VERSION "HNNBNNNYNNNNNNNNNNNNNNNNNNNNNNNNNNNNNNNNNN/4/%%%/4/'%**4NNN///"

NS_ :

BS_:

BU_: BAP_Tester BCM1 Gateway Gateway_PAG Klima_MSB Lift_VA VAS_L VAS_R

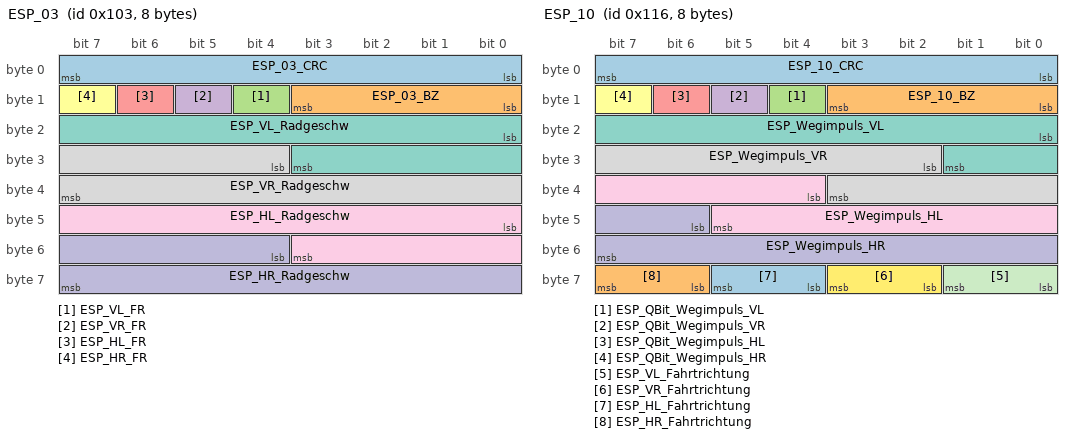
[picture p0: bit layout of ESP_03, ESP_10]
BO_ 259 ESP_03: 8 Gateway
 SG_ ESP_03_CRC : 0|8@1+ (1,0) [0|255] ""  Vector__XXX
 SG_ ESP_03_BZ : 8|4@1+ (1,0) [0|15] ""  Vector__XXX
 SG_ ESP_VL_FR : 12|1@1+ (1.0,0.0) [0.0|1] ""  BCM1
 SG_ ESP_VR_FR : 13|1@1+ (1.0,0.0) [0.0|1] ""  BCM1
 SG_ ESP_HL_FR : 14|1@1+ (1.0,0.0) [0.0|1] ""  BCM1
 SG_ ESP_HR_FR : 15|1@1+ (1.0,0.0) [0.0|1] ""  BCM1
 SG_ ESP_VL_Radgeschw : 16|12@1+ (0.1,0) [0.0|409.2] "Unit_KiloMeterPerHour"  BCM1
 SG_ ESP_VR_Radgeschw : 28|12@1+ (0.1,0) [0.0|409.2] "Unit_KiloMeterPerHour"  BCM1
 SG_ ESP_HL_Radgeschw : 40|12@1+ (0.1,0) [0.0|409.2] "Unit_KiloMeterPerHour"  BCM1
 SG_ ESP_HR_Radgeschw : 52|12@1+ (0.1,0) [0.0|409.2] "Unit_KiloMeterPerHour"  BCM1

BO_ 914 ESP_07: 8 Gateway
 SG_ ESP_07_CRC : 0|8@1+ (1,0) [0|255] ""  Vector__XXX
 SG_ ESP_07_BZ : 8|4@1+ (1,0) [0|15] ""  Vector__XXX
 SG_ ESP_Allrad_Antrieb : 13|1@1+ (1.0,0.0) [0.0|1] ""  Vector__XXX
 SG_ ESP_Codierung_ADS : 14|2@1+ (1.0,0.0) [0.0|3] ""  BCM1
 SG_ ESP_RTA_HL : 16|8@1+ (0.048828125,-6.20117) [-6.201170000|6.152345625] "Unit_PerCent"  Vector__XXX
 SG_ ESP_RTA_HR : 24|8@1+ (0.048828125,-6.20117) [-6.201170000|6.152345625] "Unit_PerCent"  Vector__XXX
 SG_ ESP_RTA_VR : 32|8@1+ (0.048828125,-6.20117) [-6.201170000|6.152345625] "Unit_PerCent"  Vector__XXX
 SG_ OBD_Fehler_Radsensor_HL : 40|4@1+ (1.0,0.0) [0.0|15] ""  Vector__XXX
 SG_ OBD_Fehler_Radsensor_HR : 44|4@1+ (1.0,0.0) [0.0|15] ""  Vector__XXX
 SG_ OBD_Fehler_Radsensor_VL : 48|4@1+ (1.0,0.0) [0.0|15] ""  Vector__XXX
 SG_ OBD_Fehler_Radsensor_VR : 52|4@1+ (1.0,0.0) [0.0|15] ""  Vector__XXX
 SG_ ESP_Qualifizierung_Antriebsart : 56|1@1+ (1.0,0.0) [0.0|1] ""  Vector__XXX
 SG_ ESP_Offroad_Modus : 57|1@1+ (1.0,0.0) [0.0|1] ""  Vector__XXX
 SG_ ESP_MKB_ausloesbar : 58|1@1+ (1.0,0.0) [0.0|1] ""  Vector__XXX
 SG_ ESP_Stat_FallBack_eBKV : 59|1@1+ (1.0,0.0) [0.0|1] ""  Vector__XXX
 SG_ ESC_cAQP_Trigger : 60|1@1+ (1.0,0.0) [0.0|1] ""  Vector__XXX
 SG_ ESP_OBD_Status : 61|1@1+ (1.0,0.0) [0.0|1] ""  Vector__XXX
 SG_ ESP_Rollenmodus_Deaktivieren : 62|1@1+ (1.0,0.0) [0.0|1] ""  BCM1,Klima_MSB
 SG_ ESP_nachtr_Stopp_Anf : 63|1@1+ (1.0,0.0) [0.0|1] ""  Vector__XXX

BO_ 278 ESP_10: 8 Gateway
 SG_ ESP_10_CRC : 0|8@1+ (1,0) [0|255] ""  BCM1
 SG_ ESP_10_BZ : 8|4@1+ (1,0) [0|15] ""  BCM1
 SG_ ESP_QBit_Wegimpuls_VL : 12|1@1+ (1.0,0.0) [0.0|1] ""  BCM1
 SG_ ESP_QBit_Wegimpuls_VR : 13|1@1+ (1.0,0.0) [0.0|1] ""  BCM1
 SG_ ESP_QBit_Wegimpuls_HL : 14|1@1+ (1.0,0.0) [0.0|1] ""  BCM1
 SG_ ESP_QBit_Wegimpuls_HR : 15|1@1+ (1.0,0.0) [0.0|1] ""  BCM1
 SG_ ESP_Wegimpuls_VL : 16|10@1+ (1,0) [0|1000] ""  BCM1
 SG_ ESP_Wegimpuls_VR : 26|10@1+ (1,0) [0|1000] ""  BCM1
 SG_ ESP_Wegimpuls_HL : 36|10@1+ (1,0) [0|1000] ""  BCM1
 SG_ ESP_Wegimpuls_HR : 46|10@1+ (1,0) [0|1000] ""  BCM1
 SG_ ESP_VL_Fahrtrichtung : 56|2@1+ (1.0,0.0) [0.0|3] ""  BCM1
 SG_ ESP_VR_Fahrtrichtung : 58|2@1+ (1.0,0.0) [0.0|3] ""  BCM1
 SG_ ESP_HL_Fahrtrichtung : 60|2@1+ (1.0,0.0) [0.0|3] ""  BCM1
 SG_ ESP_HR_Fahrtrichtung : 62|2@1+ (1.0,0.0) [0.0|3] ""  BCM1

BO_ 418 ESP_15: 8 Gateway
 SG_ ESP_15_CRC : 0|8@1+ (1,0) [0|255] ""  Vector__XXX
 SG_ ESP_15_BZ : 8|4@1+ (1,0) [0|15] ""  Vector__XXX
 SG_ HMS_P_beibehalten_GE : 12|2@1+ (1.0,0.0) [0.0|3] ""  Vector__XXX
 SG_ HMS_Konsistenz_GE : 14|1@1+ (1.0,0.0) [0.0|1] ""  Vector__XXX
 SG_ HMS_Konsistenz_IPA : 15|1@1+ (1.0,0.0) [0.0|1] ""  BCM1
 SG_ HMS_Konsistenz_STA : 18|1@1+ (1.0,0.0) [0.0|1] ""  Vector__XXX
 SG_ HMS_Konsistenz_MO : 19|1@1+ (1.0,0.0) [0.0|1] ""  Vector__XXX
 SG_ HMS_halten_nicht_verfuegbar : 20|1@1+ (1.0,0.0) [0.0|1] ""  Vector__XXX
 SG_ NL_PRIM_STP_01_Status : 21|3@1+ (1.0,0.0) [0.0|7] ""  Vector__XXX
 SG_ VMM_Warnblinken : 24|1@1+ (1.0,0.0) [0.0|1] ""  Vector__XXX
 SG_ VZM_Status : 26|3@1+ (1.0,0.0) [0.0|7] ""  BCM1
 SG_ HMS_Notstopp_Status : 29|3@1+ (1.0,0.0) [0.0|7] ""  Vector__XXX
 SG_ HMS_parken_nicht_verfuegbar : 32|1@1+ (1.0,0.0) [0.0|1] ""  Vector__XXX
 SG_ HMS_Anforderung_GE : 33|3@1+ (1.0,0.0) [0.0|7] ""  Vector__XXX
 SG_ HMS_Systemstatus : 36|4@1+ (1.0,0.0) [0.0|15] ""  BCM1
 SG_ HMS_Stillstand : 40|3@1+ (1.0,0.0) [0.0|7] ""  BCM1
 SG_ HMS_aktives_System : 43|5@1+ (1.0,0.0) [0.0|31] ""  BCM1
 SG_ HMS_Konsistenz_HVLM : 48|1@1+ (1.0,0.0) [0.0|1] ""  Vector__XXX
 SG_ HMS_Konsistenz_ACC : 49|1@1+ (1.0,0.0) [0.0|1] ""  Vector__XXX
 SG_ HMS_Fehlerstatus : 50|3@1+ (1.0,0.0) [0.0|7] ""  BCM1
 SG_ ESP_Index_Haltemoment : 53|1@1+ (1.0,0.0) [0.0|1] ""  Vector__XXX
 SG_ ESP_Haltemoment : 54|10@1+ (10,0) [0|10210] "Unit_NewtoMeter"  Vector__XXX

BO_ 253 ESP_21: 8 Gateway
 SG_ ESP_21_CRC : 0|8@1+ (1,0) [0|255] ""  BCM1
 SG_ ESP_21_BZ : 8|4@1+ (1,0) [0|15] ""  BCM1
 SG_ BR_Eingriffsmoment : 12|10@1+ (1,-509) [-509|509] ""  BCM1
 SG_ MSR_verfuegbar : 22|1@1+ (1.0,0.0) [0.0|1] ""  Vector__XXX
 SG_ ESP_Diagnose : 23|1@1+ (1.0,0.0) [0.0|1] ""  BCM1
 SG_ ESC_v_Signal_Qualifier_High_Low : 24|3@1+ (1.0,0.0) [0.0|7] ""  BCM1
 SG_ ESP_Vorsteuerung : 28|1@1+ (1.0,0.0) [0.0|1] ""  BCM1
 SG_ OBD_Schlechtweg : 30|1@1+ (1.0,0.0) [0.0|1] ""  BCM1
 SG_ OBD_QBit_Schlechtweg : 31|1@1+ (1.0,0.0) [0.0|1] ""  BCM1
 SG_ ESP_v_Signal : 32|16@1+ (0.01,0) [0.00|655.32] "Unit_KiloMeterPerHour"  BCM1,Klima_MSB,Lift_VA,VAS_L,VAS_R
 SG_ ASR_Tastung_passiv : 48|1@1+ (1.0,0.0) [0.0|1] ""  BCM1
 SG_ ESP_Tastung_passiv : 49|1@1+ (1.0,0.0) [0.0|1] ""  BCM1
 SG_ ESP_Systemstatus : 50|1@1+ (1.0,0.0) [0.0|1] ""  BCM1
 SG_ ASR_Schalteingriff : 51|2@1+ (1.0,0.0) [0.0|3] ""  BCM1
 SG_ ESP_QBit_v_Signal : 55|1@1+ (1.0,0.0) [0.0|1] ""  BCM1,Klima_MSB,VAS_L,VAS_R
 SG_ ABS_Bremsung : 56|1@1+ (1.0,0.0) [0.0|1] ""  BCM1
 SG_ ASR_Anf : 57|1@1+ (1.0,0.0) [0.0|1] ""  BCM1
 SG_ MSR_Anf : 58|1@1+ (1.0,0.0) [0.0|1] ""  BCM1
 SG_ EBV_Eingriff : 59|1@1+ (1.0,0.0) [0.0|1] ""  BCM1
 SG_ EDS_Eingriff : 60|1@1+ (1.0,0.0) [0.0|1] ""  BCM1
 SG_ ESP_Eingriff : 61|1@1+ (1.0,0.0) [0.0|1] ""  BCM1
 SG_ ESP_ASP : 62|1@1+ (1.0,0.0) [0.0|1] ""  BCM1
 SG_ ESC_Neutralschaltung : 63|1@1+ (1.0,0.0) [0.0|1] ""  Vector__XXX

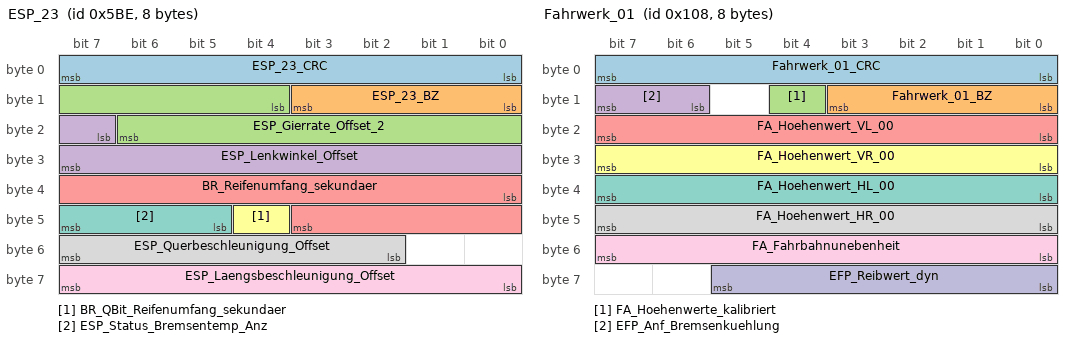
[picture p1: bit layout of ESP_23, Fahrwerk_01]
BO_ 1470 ESP_23: 8 Gateway
 SG_ ESP_23_CRC : 0|8@1+ (1,0) [0|255] ""  Vector__XXX
 SG_ ESP_23_BZ : 8|4@1+ (1,0) [0|15] ""  Vector__XXX
 SG_ ESP_Gierrate_Offset_2 : 12|11@1+ (0.01,-10.23) [-10.23|10.22] "Unit_DegreOfArcPerSecon"  VAS_L,VAS_R
 SG_ ESP_Lenkwinkel_Offset : 23|9@1+ (0.1,-25.5) [-25.5|25.4] "Unit_DegreOfArc"  Vector__XXX
 SG_ BR_Reifenumfang_sekundaer : 32|12@1+ (1,0) [0|4095] "Unit_MilliMeter"  Vector__XXX
 SG_ BR_QBit_Reifenumfang_sekundaer : 44|1@1+ (1.0,0.0) [0.0|1] ""  Vector__XXX
 SG_ ESP_Status_Bremsentemp_Anz : 45|3@1+ (1.0,0.0) [0.0|7] ""  Vector__XXX
 SG_ ESP_Querbeschleunigung_Offset : 50|6@1+ (0.01,-0.3) [-0.30|0.31] "Unit_ForceOfGravi"  Vector__XXX
 SG_ ESP_Laengsbeschleunigung_Offset : 56|8@1+ (0.03125,-3.9375) [-3.93750|3.93750] "Unit_MeterPerSeconSquar"  Vector__XXX

BO_ 508 ESP_32: 8 Gateway
 SG_ ESP_32_CRC : 0|8@1+ (1,0) [0|255] ""  Vector__XXX
 SG_ ESP_32_BZ : 8|4@1+ (1,0) [0|15] ""  Vector__XXX
 SG_ ESP_Status_Bremsentemp_02 : 12|2@1+ (1.0,0.0) [0.0|3] ""  Vector__XXX
 SG_ ESP_Aggregataktivitaet : 14|1@1+ (1.0,0.0) [0.0|1] ""  Vector__XXX
 SG_ ESP_Stillstandsflag : 15|1@1+ (1.0,0.0) [0.0|1] ""  BCM1
 SG_ ESC_MBK_Meldungen : 16|2@1+ (1.0,0.0) [0.0|3] ""  Vector__XXX
 SG_ ESP_EDS_Anzeige : 32|3@1+ (1.0,0.0) [0.0|7] ""  Vector__XXX
 SG_ RLE_Anzeigen : 35|3@1+ (1.0,0.0) [0.0|7] ""  Vector__XXX
 SG_ ESP_Wiederstart_Anz_Std : 38|1@1+ (1.0,0.0) [0.0|1] ""  Vector__XXX
 SG_ ESC_Anforderung_Airbrake : 39|1@1+ (1.0,0.0) [0.0|1] ""  Vector__XXX
 SG_ ESC_FBA_Meldungen : 40|2@1+ (1.0,0.0) [0.0|3] ""  Vector__XXX
 SG_ ESP_Rollover_Status_dyn : 42|2@1+ (1.0,0.0) [0.0|3] ""  Vector__XXX
 SG_ ESP_Rollover_Status_stat : 44|2@1+ (1.0,0.0) [0.0|3] ""  Vector__XXX
 SG_ ESP_AVH_LED : 46|3@1+ (1.0,0.0) [0.0|7] ""  BCM1
 SG_ ESP_HDC_LED : 49|3@1+ (1.0,0.0) [0.0|7] ""  BCM1
 SG_ ESP_Off_LED : 52|3@1+ (1.0,0.0) [0.0|7] ""  BCM1
 SG_ ESP_Notbremsanzeige : 55|1@1+ (1.0,0.0) [0.0|1] ""  Vector__XXX
 SG_ ESC_Motorstartverzoegerung : 56|1@1+ (1.0,0.0) [0.0|1] ""  Vector__XXX
 SG_ ESP_Offroad_Lampe : 57|1@1+ (1.0,0.0) [0.0|1] ""  Vector__XXX
 SG_ ESP_HDC_Textanzeigen : 58|5@1+ (1.0,0.0) [0.0|31] ""  Vector__XXX
 SG_ ESP_HOLD_verf : 63|1@1+ (1.0,0.0) [0.0|1] ""  Vector__XXX

BO_ 427 ESP_33: 8 Gateway
 SG_ ESP_33_CRC : 0|8@1+ (1,0) [0|255] ""  Vector__XXX
 SG_ ESP_33_BZ : 8|4@1+ (1,0) [0|15] ""  Vector__XXX
 SG_ ESC_AHW_aktiv : 12|3@1+ (1.0,0.0) [0.0|7] ""  BCM1
 SG_ ESC_AHW_nicht_verfuegbar : 15|1@1+ (1.0,0.0) [0.0|1] ""  BCM1
 SG_ ESC_ANB_CM_aktiv : 16|2@1+ (1.0,0.0) [0.0|3] ""  Vector__XXX
 SG_ ESC_ANB_CM_nicht_verfuegbar : 18|1@1+ (1.0,0.0) [0.0|1] ""  Vector__XXX
 SG_ ESC_Warnruck_aktiv : 19|4@1+ (1.0,0.0) [0.0|15] ""  Vector__XXX
 SG_ ESC_Warnruck_nicht_verfuegbar : 23|1@1+ (1.0,0.0) [0.0|1] ""  Vector__XXX
 SG_ ESC_Prefill_aktiv : 24|1@1+ (1.0,0.0) [0.0|1] ""  Vector__XXX
 SG_ ESC_Prefill_nicht_verfuegbar : 25|1@1+ (1.0,0.0) [0.0|1] ""  Vector__XXX
 SG_ ESC_HBA_aktiv : 26|1@1+ (1.0,0.0) [0.0|1] ""  Vector__XXX
 SG_ ESC_HBA_nicht_verfuegbar : 27|1@1+ (1.0,0.0) [0.0|1] ""  Vector__XXX
 SG_ ESC_TSK_SRBM_Anf : 28|1@1+ (1.0,0.0) [0.0|1] ""  Vector__XXX
 SG_ ESC_TSK_SRBM_nicht_verfuegbar : 29|1@1+ (1.0,0.0) [0.0|1] ""  Vector__XXX
 SG_ ESC_Verz_Reg_aktiv : 30|4@1+ (1.0,0.0) [0.0|15] ""  BCM1
 SG_ ESC_Verz_Reg_nicht_verfuegbar : 34|1@1+ (1.0,0.0) [0.0|1] ""  BCM1
 SG_ ESC_Verz_Reg_TB_nicht_verfuegbar : 35|1@1+ (1.0,0.0) [0.0|1] ""  BCM1
 SG_ ESC_Verz_Reg_ZB_nicht_verfuegbar : 36|1@1+ (1.0,0.0) [0.0|1] ""  BCM1
 SG_ ESC_Bremslicht_unplausibel : 37|1@1+ (1.0,0.0) [0.0|1] ""  Vector__XXX
 SG_ ESC_Konsistenz_ACC : 38|1@1+ (1.0,0.0) [0.0|1] ""  Vector__XXX
 SG_ ESC_Konsistenz_AWV : 39|1@1+ (1.0,0.0) [0.0|1] ""  Vector__XXX
 SG_ ESC_Konsistenz_ARA : 40|1@1+ (1.0,0.0) [0.0|1] ""  BCM1
 SG_ ESC_Konsistenz_IPA : 41|1@1+ (1.0,0.0) [0.0|1] ""  BCM1
 SG_ ESC_Konsistenz_FCW : 42|1@1+ (1.0,0.0) [0.0|1] ""  Vector__XXX
 SG_ ESC_Konsistenz_NV : 43|1@1+ (1.0,0.0) [0.0|1] ""  Vector__XXX
 SG_ ESC_Konsistenz_RCTA : 44|1@1+ (1.0,0.0) [0.0|1] ""  Vector__XXX
 SG_ ESC_Konsistenz_TSK : 45|1@1+ (1.0,0.0) [0.0|1] ""  Vector__XXX
 SG_ ESC_Konsistenz_vFGS : 46|1@1+ (1.0,0.0) [0.0|1] ""  Vector__XXX
 SG_ ESC_Konsistenz_STA : 47|1@1+ (1.0,0.0) [0.0|1] ""  Vector__XXX
 SG_ ESC_Fahrer_Bremsdruck_bestimmend : 48|1@1+ (1.0,0.0) [0.0|1] ""  BCM1
 SG_ ESC_Konsistenz_EA : 49|1@1+ (1.0,0.0) [0.0|1] ""  Vector__XXX
 SG_ ESC_Konsistenz_BFF : 50|1@1+ (1.0,0.0) [0.0|1] ""  Vector__XXX
 SG_ ESC_Konsistenz_MKB : 51|1@1+ (1.0,0.0) [0.0|1] ""  Vector__XXX
 SG_ ESC_Verz_ASIL_Verfuegbarkeit : 52|3@1+ (1.0,0.0) [0.0|7] ""  BCM1
 SG_ ESC_Pumpenanlauf_aktiv : 55|1@1+ (1.0,0.0) [0.0|1] ""  Vector__XXX
 SG_ ESC_Konsistenz_AGW : 56|1@1+ (1.0,0.0) [0.0|1] ""  Vector__XXX
 SG_ ESC_Konsistenz_KAS : 57|1@1+ (1.0,0.0) [0.0|1] ""  Vector__XXX
 SG_ ESC_Konsistenz_PCF : 58|1@1+ (1.0,0.0) [0.0|1] ""  Vector__XXX
 SG_ ESC_Konsistenz_FAS_VK : 59|1@1+ (1.0,0.0) [0.0|1] ""  Vector__XXX
 SG_ ESC_Verz_Begrenzung : 60|1@1+ (1.0,0.0) [0.0|1] ""  Vector__XXX
 SG_ ESC_Konsistenz_AWA : 61|1@1+ (1.0,0.0) [0.0|1] ""  Vector__XXX

BO_ 264 Fahrwerk_01: 8 Gateway
 SG_ Fahrwerk_01_CRC : 0|8@1+ (1,0) [0|255] ""  Vector__XXX
 SG_ Fahrwerk_01_BZ : 8|4@1+ (1,0) [0|15] ""  Vector__XXX
 SG_ FA_Hoehenwerte_kalibriert : 12|1@1+ (1.0,0.0) [0.0|1] ""  BCM1,Lift_VA,VAS_L,VAS_R
 SG_ EFP_Anf_Bremsenkuehlung : 14|2@1+ (1.0,0.0) [0.0|3] ""  Vector__XXX
 SG_ FA_Hoehenwert_VL_00 : 16|8@1+ (1,-127) [-127|126] "Unit_MilliMeter"  BCM1,Lift_VA,VAS_L,VAS_R
 SG_ FA_Hoehenwert_VR_00 : 24|8@1+ (1,-127) [-127|126] "Unit_MilliMeter"  Lift_VA,VAS_L,VAS_R
 SG_ FA_Hoehenwert_HL_00 : 32|8@1+ (1,-127) [-127|126] "Unit_MilliMeter"  BCM1,Lift_VA,VAS_L,VAS_R
 SG_ FA_Hoehenwert_HR_00 : 40|8@1+ (1,-127) [-127|126] "Unit_MilliMeter"  Lift_VA,VAS_L,VAS_R
 SG_ FA_Fahrbahnunebenheit : 48|8@1+ (1,0) [0|253] ""  Vector__XXX
 SG_ EFP_Reibwert_dyn : 56|6@1+ (0.03,0) [0.00|1.50] "Unit_None"  Vector__XXX

BO_ 429 Fahrwerk_06: 8 Gateway
 SG_ Fahrwerk_06_CRC : 0|8@1+ (1,0) [0|255] ""  Vector__XXX
 SG_ Fahrwerk_06_BZ : 8|4@1+ (1,0) [0|15] ""  Vector__XXX
 SG_ NR_Reglerstatus : 12|4@1+ (1.0,0.0) [0.0|15] ""  BCM1
 SG_ FA_Verstellung_in_Kuerze : 16|1@1+ (1.0,0.0) [0.0|1] ""  Vector__XXX
 SG_ FA_Verstellung_aktiv : 17|1@1+ (1.0,0.0) [0.0|1] ""  Vector__XXX
 SG_ FA_Kompressor_laeuft_in_Kuerze : 18|1@1+ (1.0,0.0) [0.0|1] ""  Vector__XXX
 SG_ FA_Kompressor_laeuft : 19|1@1+ (1.0,0.0) [0.0|1] ""  Vector__XXX
 SG_ NR_Anforderung_v_Begrenzung : 20|2@1+ (1.0,0.0) [0.0|3] ""  Vector__XXX
 SG_ NR_LED_SGN : 22|1@1+ (1.0,0.0) [0.0|1] ""  BCM1
 SG_ NR_LED_TN : 23|1@1+ (1.0,0.0) [0.0|1] ""  BCM1
 SG_ NR_LED_BN : 24|1@1+ (1.0,0.0) [0.0|1] ""  BCM1
 SG_ FA_Absenkung_Fahrzeug : 25|1@1+ (1.0,0.0) [0.0|1] ""  Vector__XXX
 SG_ FA_Anhaengerstatus_intern : 26|3@1+ (1.0,0.0) [0.0|7] ""  Vector__XXX
 SG_ FA_Anhebung_Fahrzeug : 29|1@1+ (1.0,0.0) [0.0|1] ""  Vector__XXX
 SG_ FA_Druckspeicher_verfuegbar : 30|1@1+ (1.0,0.0) [0.0|1] ""  Vector__XXX
 SG_ FA_HAL_Abschaltung : 31|1@1+ (1.0,0.0) [0.0|1] ""  Vector__XXX
 SG_ FA_ESP_Zuschaltung : 32|1@1+ (1.0,0.0) [0.0|1] ""  Vector__XXX
 SG_ NR_LED_HN : 33|1@1+ (1.0,0.0) [0.0|1] ""  BCM1
 SG_ FA_Zwischenniveau : 34|1@1+ (1.0,0.0) [0.0|1] ""  Vector__XXX
 SG_ FA_Systemstatus : 35|1@1+ (1.0,0.0) [0.0|1] ""  Vector__XXX
 SG_ EFP_Soll_FahrPr_HAL : 36|4@1+ (1.0,0.0) [0.0|15] ""  Vector__XXX
 SG_ NR_Kompressor_Strom_02 : 40|8@1+ (0.2,0) [0.0|50.8] "Unit_Amper"  Vector__XXX
 SG_ NR_Kompressor_Temp_Zylinderkopf : 48|8@1+ (1,-40) [-40|213] "Unit_DegreCelsi"  Vector__XXX
 SG_ FA_Signal_Drucksensor : 56|8@1+ (0.1,0) [0.0|25.3] "Unit_Bar"  Vector__XXX

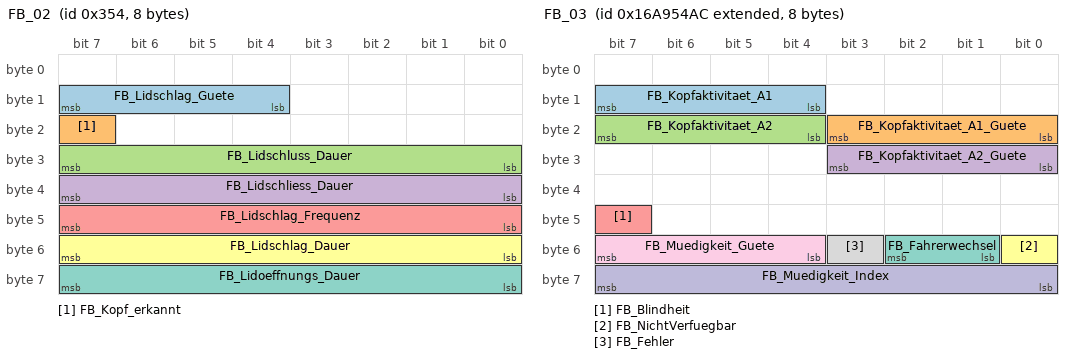
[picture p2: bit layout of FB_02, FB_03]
BO_ 852 FB_02: 8 Gateway
 SG_ FB_Lidschlag_Guete : 12|4@1+ (6.667,0) [0.000|100.005] "Unit_PerCent"  Vector__XXX
 SG_ FB_Kopf_erkannt : 23|1@1+ (1.0,0.0) [0.0|1] ""  VAS_L,VAS_R
 SG_ FB_Lidschluss_Dauer : 24|8@1+ (40,0) [0|10160] "Unit_MilliSecon"  Vector__XXX
 SG_ FB_Lidschliess_Dauer : 32|8@1+ (40,0) [0|10160] "Unit_MilliSecon"  Vector__XXX
 SG_ FB_Lidschlag_Frequenz : 40|8@1+ (0.02,0) [0.00|5.00] "Unit_Hertz"  Vector__XXX
 SG_ FB_Lidschlag_Dauer : 48|8@1+ (40,0) [0|10160] "Unit_MilliSecon"  Vector__XXX
 SG_ FB_Lidoeffnungs_Dauer : 56|8@1+ (40,0) [0|10160] "Unit_MilliSecon"  Vector__XXX

BO_ 2527679660 FB_03: 8 Gateway
 SG_ FB_Kopfaktivitaet_A1 : 12|4@1+ (7.143,0) [0.000|100.002] "Unit_None"  Vector__XXX
 SG_ FB_Kopfaktivitaet_A1_Guete : 16|4@1+ (6.667,0) [0.000|100.005] "Unit_PerCent"  Vector__XXX
 SG_ FB_Kopfaktivitaet_A2 : 20|4@1+ (7.143,0) [0.000|100.002] "Unit_None"  Vector__XXX
 SG_ FB_Kopfaktivitaet_A2_Guete : 24|4@1+ (6.667,0) [0.000|100.005] "Unit_PerCent"  Vector__XXX
 SG_ FB_Blindheit : 47|1@1+ (1.0,0.0) [0.0|1] ""  Vector__XXX
 SG_ FB_NichtVerfuegbar : 48|1@1+ (1.0,0.0) [0.0|1] ""  VAS_L,VAS_R
 SG_ FB_Fahrerwechsel : 49|2@1+ (1.0,0.0) [0.0|3] ""  Vector__XXX
 SG_ FB_Fehler : 51|1@1+ (1.0,0.0) [0.0|1] ""  Vector__XXX
 SG_ FB_Muedigkeit_Guete : 52|4@1+ (6.667,0) [0.000|100.005] "Unit_PerCent"  Vector__XXX
 SG_ FB_Muedigkeit_Index : 56|8@1+ (0.05,0) [0.00|9.00] "Unit_None"  Vector__XXX

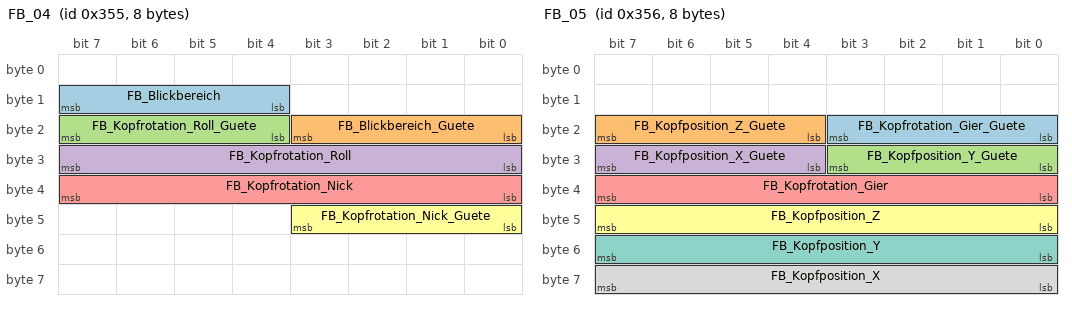
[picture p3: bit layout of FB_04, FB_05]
BO_ 853 FB_04: 8 Gateway
 SG_ FB_Blickbereich : 12|4@1+ (1,0) [0|14] "Unit_None"  Vector__XXX
 SG_ FB_Blickbereich_Guete : 16|4@1+ (6.667,0) [0.000|100.005] "Unit_PerCent"  Vector__XXX
 SG_ FB_Kopfrotation_Roll_Guete : 20|4@1+ (6.667,0) [0.000|100.005] "Unit_PerCent"  VAS_L,VAS_R
 SG_ FB_Kopfrotation_Roll : 24|8@1+ (0.03,-3.15) [-3.15|3.15] "Unit_Radia"  VAS_L,VAS_R
 SG_ FB_Kopfrotation_Nick : 32|8@1+ (0.03,-3.15) [-3.15|3.15] "Unit_Radia"  VAS_L,VAS_R
 SG_ FB_Kopfrotation_Nick_Guete : 40|4@1+ (6.667,0) [0.000|100.005] "Unit_PerCent"  VAS_L,VAS_R

BO_ 854 FB_05: 8 Gateway
 SG_ FB_Kopfrotation_Gier_Guete : 16|4@1+ (6.667,0) [0.000|100.005] "Unit_PerCent"  VAS_L,VAS_R
 SG_ FB_Kopfposition_Z_Guete : 20|4@1+ (6.667,0) [0.000|100.005] "Unit_PerCent"  VAS_L,VAS_R
 SG_ FB_Kopfposition_Y_Guete : 24|4@1+ (6.667,0) [0.000|100.005] "Unit_PerCent"  VAS_L,VAS_R
 SG_ FB_Kopfposition_X_Guete : 28|4@1+ (6.667,0) [0.000|100.005] "Unit_PerCent"  VAS_L,VAS_R
 SG_ FB_Kopfrotation_Gier : 32|8@1+ (0.03,-3.15) [-3.15|3.15] "Unit_Radia"  VAS_L,VAS_R
 SG_ FB_Kopfposition_Z : 40|8@1+ (0.01,0) [0.00|2.00] "Unit_Meter"  VAS_L,VAS_R
 SG_ FB_Kopfposition_Y : 48|8@1+ (0.01,-1) [-1.00|1.00] "Unit_Meter"  VAS_L,VAS_R
 SG_ FB_Kopfposition_X : 56|8@1+ (0.02,0) [0.00|4.00] "Unit_Meter"  VAS_L,VAS_R

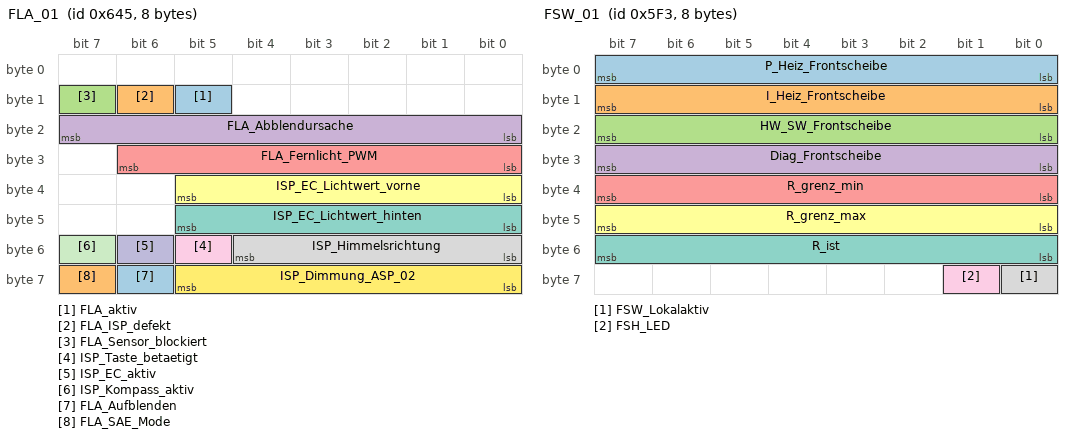
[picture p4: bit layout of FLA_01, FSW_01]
BO_ 1605 FLA_01: 8 Gateway
 SG_ FLA_aktiv : 13|1@1+ (1.0,0.0) [0.0|1] ""  BCM1
 SG_ FLA_ISP_defekt : 14|1@1+ (1.0,0.0) [0.0|1] ""  BCM1
 SG_ FLA_Sensor_blockiert : 15|1@1+ (1.0,0.0) [0.0|1] ""  BCM1
 SG_ FLA_Abblendursache : 16|8@1+ (1.0,0.0) [0.0|255] ""  Vector__XXX
 SG_ FLA_Fernlicht_PWM : 24|7@1+ (1,0) [0|100] "Unit_PerCent"  BCM1
 SG_ ISP_EC_Lichtwert_vorne : 32|6@1+ (1,0) [0|61] "Unit_None"  Vector__XXX
 SG_ ISP_EC_Lichtwert_hinten : 40|6@1+ (1,0) [0|61] "Unit_None"  Vector__XXX
 SG_ ISP_Himmelsrichtung : 48|5@1+ (12,0) [0|348] "Unit_DegreOfArc"  Vector__XXX
 SG_ ISP_Taste_betaetigt : 53|1@1+ (1.0,0.0) [0.0|1] ""  Vector__XXX
 SG_ ISP_EC_aktiv : 54|1@1+ (1.0,0.0) [0.0|1] ""  Vector__XXX
 SG_ ISP_Kompass_aktiv : 55|1@1+ (1.0,0.0) [0.0|1] ""  Vector__XXX
 SG_ ISP_Dimmung_ASP_02 : 56|6@1+ (0.0226,0) [0.0000|1.4012] "Unit_Volt"  Vector__XXX
 SG_ FLA_Aufblenden : 62|1@1+ (1.0,0.0) [0.0|1] ""  BCM1
 SG_ FLA_SAE_Mode : 63|1@1+ (1.0,0.0) [0.0|1] ""  Vector__XXX

BO_ 2589283684 FoD_01: 8 Gateway
 SG_ FoD_Transmission_Info : 60|2@1+ (1.0,0.0) [0.0|3] ""  BCM1
 SG_ FoD_Anz_Funktionsabschaltung : 62|2@1+ (1.0,0.0) [0.0|3] ""  Vector__XXX

BO_ 2549875470 FoD_BCM1_Req: 8 Gateway
 SG_ FoD_BCM1_Req_Data : 0|64@1+ (1.0,0.0) [0.0|18446744073709551615] ""  BCM1

BO_ 2550006542 FoD_BCM1_Resp: 8 BCM1
 SG_ FoD_BCM1_Resp_Data : 0|64@1+ (1.0,0.0) [0.0|18446744073709551615] ""  Gateway,Gateway_PAG

BO_ 1523 FSW_01: 8 Gateway
 SG_ P_Heiz_Frontscheibe : 0|8@1+ (10,0) [0|2500] "Unit_Watt"  Klima_MSB
 SG_ I_Heiz_Frontscheibe : 8|8@1+ (0.5,0) [0.0|125.0] "Unit_Amper"  BCM1
 SG_ HW_SW_Frontscheibe : 16|8@1+ (1.0,0.0) [0.0|255] ""  Vector__XXX
 SG_ Diag_Frontscheibe : 24|8@1+ (1.0,0.0) [0.0|255] ""  Vector__XXX
 SG_ R_grenz_min : 32|8@1+ (0.05,0) [0.00|10.00] "Unit_Ohm"  Vector__XXX
 SG_ R_grenz_max : 40|8@1+ (0.05,0) [0.00|10.00] "Unit_Ohm"  Vector__XXX
 SG_ R_ist : 48|8@1+ (0.05,0) [0.00|10.00] "Unit_Ohm"  Vector__XXX
 SG_ FSW_Lokalaktiv : 56|1@1+ (1.0,0.0) [0.0|1] ""  Vector__XXX
 SG_ FSH_LED : 57|1@1+ (1.0,0.0) [0.0|1] ""  Vector__XXX

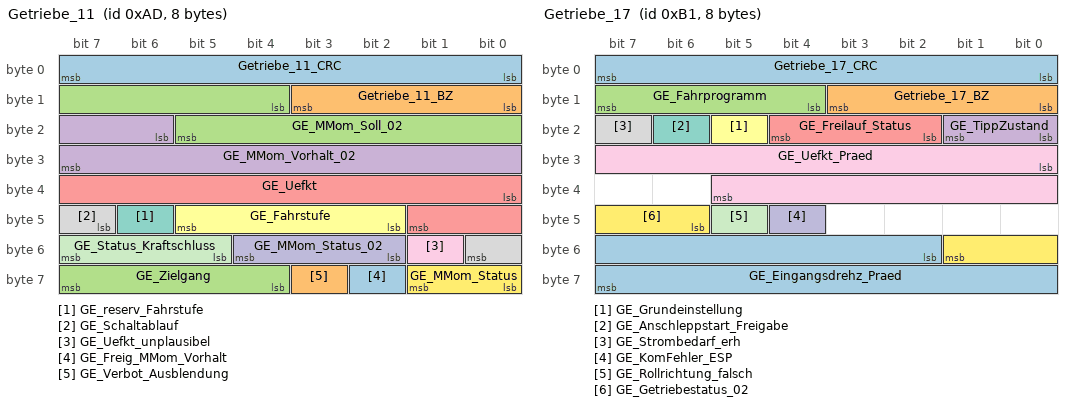
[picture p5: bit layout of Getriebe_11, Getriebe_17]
BO_ 173 Getriebe_11: 8 Gateway
 SG_ Getriebe_11_CRC : 0|8@1+ (1,0) [0|255] ""  Vector__XXX
 SG_ Getriebe_11_BZ : 8|4@1+ (1,0) [0|15] ""  Vector__XXX
 SG_ GE_MMom_Soll_02 : 12|10@1+ (1,-509) [-509|509] ""  Vector__XXX
 SG_ GE_MMom_Vorhalt_02 : 22|10@1+ (1,-509) [-509|509] ""  Vector__XXX
 SG_ GE_Uefkt : 32|10@1+ (0.1,0) [0.0|102.2] ""  Vector__XXX
 SG_ GE_Fahrstufe : 42|4@1+ (1.0,0.0) [0.0|15] ""  BCM1,Lift_VA
 SG_ GE_reserv_Fahrstufe : 46|1@1+ (1,0) [0|1] ""  Vector__XXX
 SG_ GE_Schaltablauf : 47|2@1+ (1.0,0.0) [0.0|3] ""  Vector__XXX
 SG_ GE_Uefkt_unplausibel : 49|1@1+ (1.0,0.0) [0.0|1] ""  Vector__XXX
 SG_ GE_MMom_Status_02 : 50|3@1+ (1.0,0.0) [0.0|7] ""  Vector__XXX
 SG_ GE_Status_Kraftschluss : 53|3@1+ (1.0,0.0) [0.0|7] ""  Vector__XXX
 SG_ GE_MMom_Status : 56|2@1+ (1.0,0.0) [0.0|3] ""  Vector__XXX
 SG_ GE_Freig_MMom_Vorhalt : 58|1@1+ (1.0,0.0) [0.0|1] ""  Vector__XXX
 SG_ GE_Verbot_Ausblendung : 59|1@1+ (1.0,0.0) [0.0|1] ""  Vector__XXX
 SG_ GE_Zielgang : 60|4@1+ (1.0,0.0) [0.0|15] ""  BCM1

BO_ 177 Getriebe_17: 8 Gateway
 SG_ Getriebe_17_CRC : 0|8@1+ (1,0) [0|255] ""  Vector__XXX
 SG_ Getriebe_17_BZ : 8|4@1+ (1,0) [0|15] ""  Vector__XXX
 SG_ GE_Fahrprogramm : 12|4@1+ (1.0,0.0) [0.0|15] ""  Vector__XXX
 SG_ GE_TippZustand : 16|2@1+ (1.0,0.0) [0.0|3] ""  Vector__XXX
 SG_ GE_Freilauf_Status : 18|3@1+ (1.0,0.0) [0.0|7] ""  BCM1,Klima_MSB
 SG_ GE_Grundeinstellung : 21|1@1+ (1.0,0.0) [0.0|1] ""  Vector__XXX
 SG_ GE_Anschleppstart_Freigabe : 22|1@1+ (1.0,0.0) [0.0|1] ""  Vector__XXX
 SG_ GE_Strombedarf_erh : 23|1@1+ (1.0,0.0) [0.0|1] ""  Vector__XXX
 SG_ GE_Uefkt_Praed : 24|14@1+ (0.008,0) [0.000|131.056] ""  Vector__XXX
 SG_ GE_KomFehler_ESP : 44|1@1+ (1.0,0.0) [0.0|1] ""  Vector__XXX
 SG_ GE_Rollrichtung_falsch : 45|1@1+ (1.0,0.0) [0.0|1] ""  Vector__XXX
 SG_ GE_Getriebestatus_02 : 46|4@1+ (1.0,0.0) [0.0|15] ""  Vector__XXX
 SG_ GE_Eingangsdrehz_Praed : 50|14@1+ (1,0) [0|16381] "Unit_MinutInver"  Vector__XXX

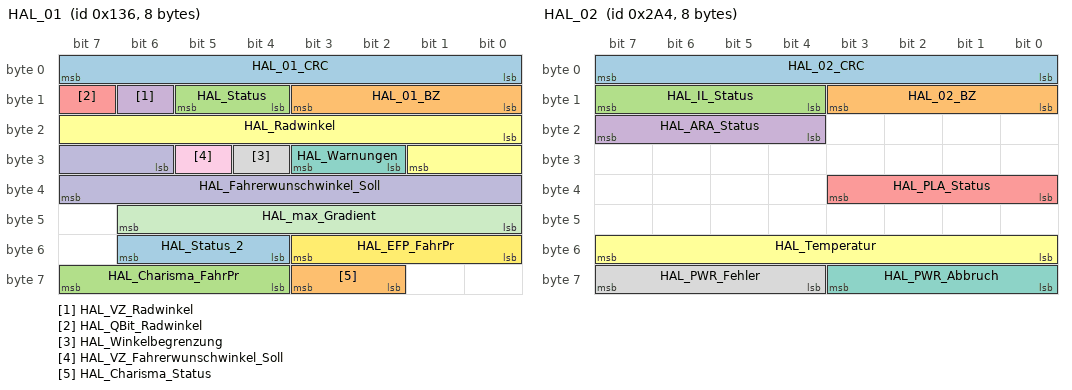
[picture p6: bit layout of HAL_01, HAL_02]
BO_ 310 HAL_01: 8 Gateway
 SG_ HAL_01_CRC : 0|8@1+ (1,0) [0|255] ""  BCM1
 SG_ HAL_01_BZ : 8|4@1+ (1,0) [0|15] ""  BCM1
 SG_ HAL_Status : 12|2@1+ (1.0,0.0) [0.0|3] ""  BCM1
 SG_ HAL_VZ_Radwinkel : 14|1@1+ (1.0,0.0) [0.0|1] ""  BCM1
 SG_ HAL_QBit_Radwinkel : 15|1@1+ (1.0,0.0) [0.0|1] ""  BCM1
 SG_ HAL_Radwinkel : 16|10@1+ (0.01,0) [0.00|10.19] "Unit_DegreOfArc"  BCM1
 SG_ HAL_Warnungen : 26|2@1+ (1.0,0.0) [0.0|3] ""  Vector__XXX
 SG_ HAL_Winkelbegrenzung : 28|1@1+ (1.0,0.0) [0.0|1] ""  Vector__XXX
 SG_ HAL_VZ_Fahrerwunschwinkel_Soll : 29|1@1+ (1.0,0.0) [0.0|1] ""  BCM1
 SG_ HAL_Fahrerwunschwinkel_Soll : 30|10@1+ (0.01,0) [0.00|10.21] "Unit_DegreOfArc"  BCM1
 SG_ HAL_max_Gradient : 40|7@1+ (0.1,0) [0.0|12.5] "Unit_DegreOfArcPerSecon"  BCM1
 SG_ HAL_EFP_FahrPr : 48|4@1+ (1.0,0.0) [0.0|15] ""  Vector__XXX
 SG_ HAL_Status_2 : 52|3@1+ (1.0,0.0) [0.0|7] ""  Vector__XXX
 SG_ HAL_Charisma_Status : 58|2@1+ (1.0,0.0) [0.0|3] ""  Vector__XXX
 SG_ HAL_Charisma_FahrPr : 60|4@1+ (1.0,0.0) [0.0|15] ""  Vector__XXX

BO_ 676 HAL_02: 8 Gateway
 SG_ HAL_02_CRC : 0|8@1+ (1,0) [0|255] ""  BCM1
 SG_ HAL_02_BZ : 8|4@1+ (1,0) [0|15] ""  BCM1
 SG_ HAL_IL_Status : 12|4@1+ (1.0,0.0) [0.0|15] ""  Vector__XXX
 SG_ HAL_ARA_Status : 20|4@1+ (1.0,0.0) [0.0|15] ""  BCM1
 SG_ HAL_PLA_Status : 32|4@1+ (1.0,0.0) [0.0|15] ""  BCM1
 SG_ HAL_Temperatur : 48|8@1+ (1,-41) [-40|125] "Unit_DegreCelsi"  Vector__XXX
 SG_ HAL_PWR_Abbruch : 56|4@1+ (1.0,0.0) [0.0|15] ""  BCM1
 SG_ HAL_PWR_Fehler : 60|4@1+ (1.0,0.0) [0.0|15] ""  BCM1

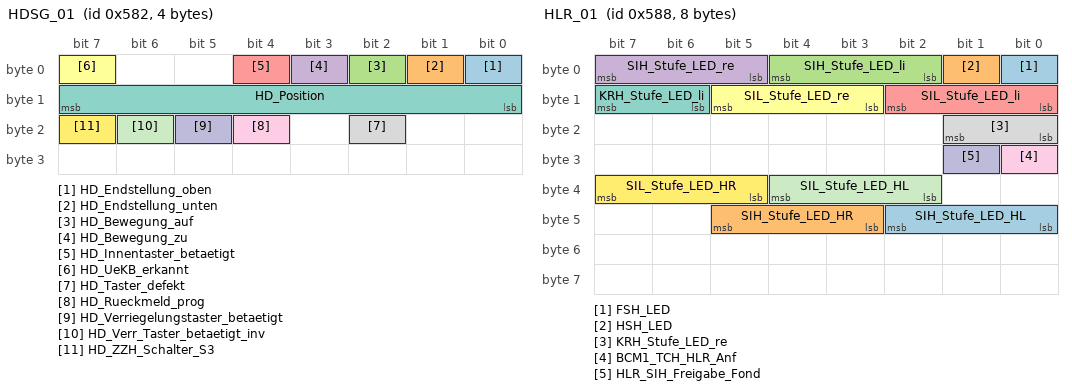
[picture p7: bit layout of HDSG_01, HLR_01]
BO_ 1410 HDSG_01: 4 Gateway
 SG_ HD_Endstellung_oben : 0|1@1+ (1.0,0.0) [0.0|1] ""  BCM1
 SG_ HD_Endstellung_unten : 1|1@1+ (1.0,0.0) [0.0|1] ""  BCM1
 SG_ HD_Bewegung_auf : 2|1@1+ (1.0,0.0) [0.0|1] ""  Vector__XXX
 SG_ HD_Bewegung_zu : 3|1@1+ (1.0,0.0) [0.0|1] ""  BCM1,Klima_MSB
 SG_ HD_Innentaster_betaetigt : 4|1@1+ (1.0,0.0) [0.0|1] ""  Vector__XXX
 SG_ HD_UeKB_erkannt : 7|1@1+ (1.0,0.0) [0.0|1] ""  Vector__XXX
 SG_ HD_Position : 8|8@1+ (1,0) [0|100] "Unit_PerCent"  BCM1,Klima_MSB
 SG_ HD_Taster_defekt : 18|1@1+ (1.0,0.0) [0.0|1] ""  Vector__XXX
 SG_ HD_Rueckmeld_prog : 20|1@1+ (1.0,0.0) [0.0|1] ""  Vector__XXX
 SG_ HD_Verriegelungstaster_betaetigt : 21|1@1+ (1.0,0.0) [0.0|1] ""  Vector__XXX
 SG_ HD_Verr_Taster_betaetigt_inv : 22|1@1+ (1.0,0.0) [0.0|1] ""  Vector__XXX
 SG_ HD_ZZH_Schalter_S3 : 23|1@1+ (1.0,0.0) [0.0|1] ""  Vector__XXX

BO_ 1416 HLR_01: 8 BCM1
 SG_ FSH_LED : 0|1@1+ (1.0,0.0) [0.0|1] ""  Gateway,Gateway_PAG
 SG_ HSH_LED : 1|1@1+ (1.0,0.0) [0.0|1] ""  Gateway,Gateway_PAG
 SG_ SIH_Stufe_LED_li : 2|3@1+ (1.0,0.0) [0.0|7] ""  Gateway,Gateway_PAG,Klima_MSB
 SG_ SIH_Stufe_LED_re : 5|3@1+ (1.0,0.0) [0.0|7] ""  Gateway,Gateway_PAG,Klima_MSB
 SG_ SIL_Stufe_LED_li : 8|3@1+ (1.0,0.0) [0.0|7] ""  Gateway,Gateway_PAG,Klima_MSB
 SG_ SIL_Stufe_LED_re : 11|3@1+ (1.0,0.0) [0.0|7] ""  Gateway,Gateway_PAG,Klima_MSB
 SG_ KRH_Stufe_LED_li : 14|2@1+ (1.0,0.0) [0.0|3] ""  Gateway,Gateway_PAG,Klima_MSB
 SG_ KRH_Stufe_LED_re : 16|2@1+ (1.0,0.0) [0.0|3] ""  Gateway,Gateway_PAG,Klima_MSB
 SG_ BCM1_TCH_HLR_Anf : 24|1@1+ (1.0,0.0) [0.0|1] ""  Gateway,Gateway_PAG
 SG_ HLR_SIH_Freigabe_Fond : 25|1@1+ (1.0,0.0) [0.0|1] ""  Gateway,Gateway_PAG
 SG_ SIL_Stufe_LED_HL : 34|3@1+ (1.0,0.0) [0.0|7] ""  Gateway,Gateway_PAG,Klima_MSB
 SG_ SIL_Stufe_LED_HR : 37|3@1+ (1.0,0.0) [0.0|7] ""  Gateway,Gateway_PAG,Klima_MSB
 SG_ SIH_Stufe_LED_HL : 40|3@1+ (1.0,0.0) [0.0|7] ""  Gateway,Gateway_PAG,Klima_MSB
 SG_ SIH_Stufe_LED_HR : 43|3@1+ (1.0,0.0) [0.0|7] ""  Gateway,Gateway_PAG,Klima_MSB

BO_ 1016 HLR_02: 8 Gateway
 SG_ HLR_FlHz_Freigabe_Ruhesitz : 14|2@1+ (1.0,0.0) [0.0|3] ""  BCM1
 SG_ HLR_FlHz_Freigabe_VR : 16|2@1+ (1.0,0.0) [0.0|3] ""  BCM1,Klima_MSB
 SG_ HLR_FlHz_Freigabe_VL : 18|2@1+ (1.0,0.0) [0.0|3] ""  BCM1,Klima_MSB
 SG_ HLR_FlHz_Freigabe_HR : 20|2@1+ (1.0,0.0) [0.0|3] ""  BCM1,Klima_MSB
 SG_ HLR_FlHz_Freigabe_HL : 22|2@1+ (1.0,0.0) [0.0|3] ""  BCM1,Klima_MSB
 SG_ HLR_TCH_Freigabe : 24|1@1+ (1.0,0.0) [0.0|1] ""  BCM1
 SG_ HLR_SIH_Freigabe_Fond : 25|1@1+ (1.0,0.0) [0.0|1] ""  BCM1
 SG_ HLR_Sp_Heizung_Freigabe_BT : 26|1@1+ (1.0,0.0) [0.0|1] ""  Vector__XXX
 SG_ HLR_Sp_Heizung_Freigabe_FT : 27|1@1+ (1.0,0.0) [0.0|1] ""  Vector__XXX
 SG_ HLR_KRH_Freigabe_VL : 28|2@1+ (1.0,0.0) [0.0|3] ""  BCM1
 SG_ HLR_KRH_Freigabe_VR : 30|2@1+ (1.0,0.0) [0.0|3] ""  BCM1
 SG_ HLR_SIH_Freigabe_VL : 32|2@1+ (1.0,0.0) [0.0|3] ""  BCM1,Klima_MSB
 SG_ HLR_SIH_Freigabe_VR : 34|2@1+ (1.0,0.0) [0.0|3] ""  BCM1,Klima_MSB
 SG_ HLR_SIH_Freigabe_HL : 36|2@1+ (1.0,0.0) [0.0|3] ""  BCM1,Klima_MSB
 SG_ HLR_SIH_Freigabe_HR : 38|2@1+ (1.0,0.0) [0.0|3] ""  BCM1,Klima_MSB
 SG_ HLR_SIL_Freigabe_VL : 40|2@1+ (1.0,0.0) [0.0|3] ""  BCM1,Klima_MSB
 SG_ HLR_SIL_Freigabe_VR : 42|2@1+ (1.0,0.0) [0.0|3] ""  BCM1,Klima_MSB
 SG_ HLR_SIL_Freigabe_HL : 44|2@1+ (1.0,0.0) [0.0|3] ""  BCM1,Klima_MSB
 SG_ HLR_SIL_Freigabe_HR : 46|2@1+ (1.0,0.0) [0.0|3] ""  BCM1,Klima_MSB
 SG_ HLR_FSH_Freigabe : 48|6@1+ (20,0) [20|1240] "Unit_Watt"  BCM1,Klima_MSB
 SG_ HLR_HSH_Freigabe : 54|1@1+ (1.0,0.0) [0.0|1] ""  Vector__XXX
 SG_ HLR_LRH_Freigabe : 55|1@1+ (1.0,0.0) [0.0|1] ""  Vector__XXX
 SG_ HLR_PTC_linear_Freigabe : 56|6@1+ (50,0) [0|3100] "Unit_Watt"  BCM1,Klima_MSB
 SG_ HLR_PTC_Freigabe : 62|2@1+ (1.0,0.0) [0.0|3] ""  BCM1

BO_ 1283 HVK_01: 8 Gateway
 SG_ HVK_01_CRC : 0|8@1+ (1,0) [0|255] ""  Vector__XXX
 SG_ HVK_01_BZ : 8|4@1+ (1,0) [0|15] ""  Vector__XXX
 SG_ HVK_Istmodus_Anf : 12|1@1+ (1.0,0.0) [0.0|1] ""  Vector__XXX
 SG_ HVK_TN1_Sollmodus : 13|2@1+ (1.0,0.0) [0.0|3] ""  Vector__XXX
 SG_ HVK_MO_EmSollzustand : 16|8@1+ (1.0,0.0) [0.0|255] ""  Vector__XXX
 SG_ HVK_BMS_Sollmodus : 24|3@1+ (1.0,0.0) [0.0|7] ""  Vector__XXX
 SG_ HVK_DCDC_Sollmodus : 27|3@1+ (1.0,0.0) [0.0|7] ""  Vector__XXX
 SG_ HVK_EKK_Sollmodus : 30|3@1+ (1.0,0.0) [0.0|7] ""  Vector__XXX
 SG_ HVK_HVPTC_Sollmodus : 33|3@1+ (1.0,0.0) [0.0|7] ""  BCM1,Klima_MSB
 SG_ HVK_HVLM_Sollmodus : 36|3@1+ (1.0,0.0) [0.0|7] ""  Vector__XXX
 SG_ HVK_HV_Netz_Warnungen : 39|2@1+ (1.0,0.0) [0.0|3] ""  Vector__XXX
 SG_ HV_Bordnetz_aktiv : 41|1@1+ (1.0,0.0) [0.0|1] ""  Vector__XXX
 SG_ HV_Bordnetz_Fehler : 42|1@1+ (1.0,0.0) [0.0|1] ""  Vector__XXX
 SG_ HVK_Gesamtst_Spgfreiheit : 43|2@1+ (1.0,0.0) [0.0|3] ""  Vector__XXX
 SG_ HVK_AktiveEntladung_Anf : 45|1@1+ (1.0,0.0) [0.0|1] ""  Vector__XXX
 SG_ HVK_Iso_Fehlerstatus : 48|1@1+ (1.0,0.0) [0.0|1] ""  Vector__XXX
 SG_ HVK_Iso_Messung_Start : 50|3@1+ (1.0,0.0) [0.0|7] ""  Vector__XXX
 SG_ HVK_AIAD_Sollmodus_2 : 53|1@1+ (1.0,0.0) [0.0|1] ""  Vector__XXX
 SG_ HVK_DCDC_EKK_Sollmodus : 62|2@1+ (1.0,0.0) [0.0|3] ""  Vector__XXX

BO_TX_BU_ 259 :Gateway,Gateway_PAG;
BO_TX_BU_ 914 :Gateway,Gateway_PAG;
BO_TX_BU_ 278 :Gateway,Gateway_PAG;
BO_TX_BU_ 418 :Gateway,Gateway_PAG;
BO_TX_BU_ 253 :Gateway,Gateway_PAG;
BO_TX_BU_ 1470 :Gateway,Gateway_PAG;
BO_TX_BU_ 508 :Gateway,Gateway_PAG;
BO_TX_BU_ 427 :Gateway,Gateway_PAG;
BO_TX_BU_ 264 :Gateway,Gateway_PAG;
BO_TX_BU_ 429 :Gateway,Gateway_PAG;
BO_TX_BU_ 852 :Gateway,Gateway_PAG;
BO_TX_BU_ 2527679660 :Gateway,Gateway_PAG;
BO_TX_BU_ 853 :Gateway,Gateway_PAG;
BO_TX_BU_ 854 :Gateway,Gateway_PAG;
BO_TX_BU_ 1605 :Gateway,Gateway_PAG;
BO_TX_BU_ 2589283684 :Gateway,Gateway_PAG;
BO_TX_BU_ 2549875470 :Gateway,Gateway_PAG;
BO_TX_BU_ 1523 :Gateway,Gateway_PAG;
BO_TX_BU_ 173 :Gateway,Gateway_PAG;
BO_TX_BU_ 177 :Gateway,Gateway_PAG;
BO_TX_BU_ 310 :Gateway,Gateway_PAG;
BO_TX_BU_ 676 :Gateway,Gateway_PAG;
BO_TX_BU_ 1410 :Gateway,Gateway_PAG;
BO_TX_BU_ 1016 :Gateway,Gateway_PAG;
BO_TX_BU_ 1283 :Gateway,Gateway_PAG;
CM_ BO_ 259 "MLBevo - CRC-Absicherung";
CM_ BO_ 418 "MLBevo verlangsamte 100ms-Botschaft";
CM_ BO_ 253 "Neue Momente im MQB
Struktur ab MQB mit CRC8 entstanden aus ESP_01";
CM_ BO_ 1470 "MSS (AU724/5, LBxxx) Botschaft zur Offsetkompentation";
CM_ BO_ 508 "CAN-Botschaft";
CM_ BO_ 264 "ab MLBevo mit CRC";
CM_ BO_ 1416 "Heizleistungsregelung";
CM_ BO_ 1016 "Heizleistungsregelung 
MLBevo (NVEM im Gateway)";

CM_ SG_ 259 ESP_03_CRC "Ab MQB und MLBevo:
'Berechnung siehe Lastenheft 'End-to-End Kommunikationsabsicherung''

Endwerte siehe Begleitdokument 'S-PDU Kennungsfolgen'";
CM_ SG_ 259 ESP_HL_FR "Fahrtrichtungserkennung Rad Hinten Links
";
CM_ SG_ 259 ESP_HL_Radgeschw "Radgeschwindigkeit hinten links";
CM_ SG_ 259 ESP_HR_FR "Fahrtrichtungserkennung Rad Hinten Rechts
";
CM_ SG_ 259 ESP_HR_Radgeschw "Radgeschwindigkeit hinten rechts";
CM_ SG_ 259 ESP_VL_FR "Fahrtrichtungserkennung Rad Vorne Links
";
CM_ SG_ 259 ESP_VL_Radgeschw "Radgeschwindigkeit vorne links";
CM_ SG_ 259 ESP_VR_FR "Fahrtrichtungserkennung Rad Vorne Rechts

";
CM_ SG_ 259 ESP_VR_Radgeschw "Radgeschwindigkeit vorne rechts";

CM_ SG_ 914 ESC_cAQP_Trigger "Trigger zur statistischen Auswertung durch die Connected Car Funktion Aquaplaning Praediktion (AQP).

Ansprechpartner: Timo Maise (PAG- EEC2)";
CM_ SG_ 914 ESP_07_CRC "Für MLB:
'Berechnung siehe Lastenheft 'Kommunikationsabsicherung für FlexRay und CAN''

Ab MQB und MLBevo:
'Berechnung siehe Lastenheft 'End-to-End Kommunikationsabsicherung''

Endwerte siehe Begleitdokument 'S-PDU Kennungsfolgen'";
CM_ SG_ 914 ESP_Allrad_Antrieb "Im MQB wird das Signal nicht unterstützt!";
CM_ SG_ 914 ESP_Codierung_ADS "ESP gibt für Empfänger im Fahrzeug aus, ob ADS verbaut/nicht verbaut ist.

Im MQB wird das Signal nicht unterstützt!
";
CM_ SG_ 914 ESP_MKB_ausloesbar "ESP hat Funktion Multi-Kollisions-Bremsung freigeschaltet";
CM_ SG_ 914 ESP_nachtr_Stopp_Anf "Dieses Signal dient dem Motor als Trigger, dass ein nachträglicher Motorstopp eingeleitet werden kann, wenn es die Bedingungen des StSt Koordinators dies zulassen. ";
CM_ SG_ 914 ESP_OBD_Status "Dieses Bit steuert die MIL-Lampe an (Motorsteuergerät reicht diese Info an Kombi weiter).";
CM_ SG_ 914 ESP_Offroad_Modus "Nur VW526: Bei Offroad-Fahrzeugen kann über einen Schalter ein Offroadmodus gewählt werden, dieser wird hier angezeigt. Bei Offroad Plus- Fahrzeugen wird hier der Offroadmodus indirekt durch das Verteilergetriebe vorgegeben (ALR_Offroad = 1) und eingespie";
CM_ SG_ 914 ESP_Qualifizierung_Antriebsart "Signal for Bentley BY83x: ESP_wheel_drive_selector

Bit qualifiziert für neue Projekte (ab D4 ff.) das Signal 'ESP_Quattro_Antrieb', d.h. ist 'ESP_Qualifizierung_Antriebsart'
auf 0x1 gesetzt, ändert sich die bisherige Bedeutung des Signals 'ESP_Quattro";
CM_ SG_ 914 ESP_Rollenmodus_Deaktivieren "Zwang zum Abbruch des Rollenmodus mit anschließender ESP-Vollfunktion.
MQB: Zwang zum Abbruch des Rollenmodus in allen Funktionsteilnehmern (Empfänger) mit anschließender ESP-Vollfunktion (Sender).
Signal wird vom ESP dauerhaft mit gültigen Werten bedat";
CM_ SG_ 914 ESP_RTA_HL "Physikalischer Wertebereich +/-5%. Der Reifentoleranzabgleich bezieht sich auf das linke Vorderrad.

physikalischer Wert = ( (Hex-Wert - 0x7F) / 2048 )*100%

Im MQB wird das Signal nicht unterstützt!";
CM_ SG_ 914 ESP_RTA_HR "Physikalischer Wertebereich +/-5%. Der Reifentoleranzabgleich bezieht sich auf das linke Vorderrad.

physikalischer Wert = ( (Hex-Wert - 0x7F) / 2048 )*100%

Im MQB wird das Signal nicht unterstützt!";
CM_ SG_ 914 ESP_RTA_VR "Physikalischer Wertebereich +/-5%. Der Reifentoleranzabgleich bezieht sich auf das linke Vorderrad.

physikalischer Wert = ( (Hex-Wert - 0x7F) / 2048 )*100%

Im MQB wird das Signal nicht unterstützt!";
CM_ SG_ 914 ESP_Stat_FallBack_eBKV "Das Signal zeigt dem eBKV an, ob seine Rückfallebene im ESP verfügbar ist.";
CM_ SG_ 914 OBD_Fehler_Radsensor_HL "Für Motor-SG (gesetzliche Vorgabe)";
CM_ SG_ 914 OBD_Fehler_Radsensor_HR "Für Motor-SG (gesetzliche Vorgabe)";
CM_ SG_ 914 OBD_Fehler_Radsensor_VL "Für Motor-SG (gesetzliche Vorgabe)";
CM_ SG_ 914 OBD_Fehler_Radsensor_VR "Für Motor-SG (gesetzliche Vorgabe)";

CM_ SG_ 278 ESP_10_BZ "Botschaftszähler

Wird im Projekt D4 und D4Hybrid nicht verwendet!  Wird im D4 PA verwendet";
CM_ SG_ 278 ESP_10_CRC "Für MLB:
'Berechnung siehe Lastenheft 'Kommunikationsabsicherung für FlexRay und CAN''

Ab MQB und MLBevo:
'Berechnung siehe Lastenheft 'End-to-End Kommunikationsabsicherung''

Endwerte siehe Begleitdokument 'S-PDU Kennungsfolgen'

Wird im Projekt";
CM_ SG_ 278 ESP_HL_Fahrtrichtung "Drehrichtung Rad HL

Weiterführende Informationen im Lastenheft spezifiziert und in der entsprechenden Fachabteilung zu erfragen.

Wird im Projekt D4 und D4Hybrid nicht verwendet!  Wird im D4 PA verwendet";
CM_ SG_ 278 ESP_HR_Fahrtrichtung "Drehrichtung Rad HR

Weiterführende Informationen im Lastenheft spezifiziert und in der entsprechenden Fachabteilung zu erfragen.

Wird im Projekt D4 und D4Hybrid nicht verwendet!  Wird im D4 PA verwendet";
CM_ SG_ 278 ESP_QBit_Wegimpuls_HL "Qualifizierungsbit Wegimpulszähler HL

Wird im Projekt D4 und D4Hybrid nicht verwendet!  Wird im D4 PA verwendet";
CM_ SG_ 278 ESP_QBit_Wegimpuls_HR "Qualifizierungsbit Wegimpulszähler HR

Wird im Projekt D4 und D4Hybrid nicht verwendet!  Wird im D4 PA verwendet";
CM_ SG_ 278 ESP_QBit_Wegimpuls_VL "Qualifizierungsbit Wegimpulszähler VL

Wird im Projekt D4 und D4Hybrid nicht verwendet!  Wird im D4 PA verwendet";
CM_ SG_ 278 ESP_QBit_Wegimpuls_VR "Qualifizierungsbit Wegimpulszähler VR

Wird im Projekt D4 und D4Hybrid nicht verwendet!  Wird im D4 PA verwendet";
CM_ SG_ 278 ESP_VL_Fahrtrichtung "Drehrichtung Rad VL

Weiterführende Informationen im Lastenheft spezifiziert und in der entsprechenden Fachabteilung zu erfragen.

Wird im Projekt D4 und D4Hybrid nicht verwendet!  Wird im D4 PA verwendet";
CM_ SG_ 278 ESP_VR_Fahrtrichtung "Drehrichtung Rad VR

Weiterführende Informationen im Lastenheft spezifiziert und in der entsprechenden Fachabteilung zu erfragen.

Wird im Projekt D4 und D4Hybrid nicht verwendet!  Wird im D4 PA verwendet";
CM_ SG_ 278 ESP_Wegimpuls_HL "Wegimpulszähler HL.
Anzahl der Wegimpulse Hinterrad links (steigende und fallende Flanke)
Zähler läuft grundsätzlich vorwärts, auch bei Rückwärtsfahrt.
Nach SG-Reset ist immer, ohne Ausnahme, 1mal der Init Wert 1021 zu senden.

Wird im Projekt D4 und";
CM_ SG_ 278 ESP_Wegimpuls_HR "Wegimpulszähler HR.
Anzahl der Wegimpulse Hinterrad rechts (steigende und fallende Flanke)
Zähler läuft grundsätzlich vorwärts, auch bei Rückwärtsfahrt.
Nach SG-Reset ist immer, ohne Ausnahme, 1mal der Init Wert 1021 zu senden.

Wird im Projekt D4 un";
CM_ SG_ 278 ESP_Wegimpuls_VL "Wegimpulszähler VL.
Anzahl der Wegimpulse Vorderrad links (steigende und fallende Flanke)
Zähler läuft grundsätzlich vorwärts, auch bei Rückwärtsfahrt.
Nach SG-Reset ist immer, ohne Ausnahme, 1mal der Init Wert 1021 zu senden.

Wird im Projekt D4 und";
CM_ SG_ 278 ESP_Wegimpuls_VR "Wegimpulszähler VR.
Anzahl der Wegimpulse Vorderrad rechts (steigende und fallende Flanke)
Zähler läuft grundsätzlich vorwärts, auch bei Rückwärtsfahrt.
Nach SG-Reset ist immer, ohne Ausnahme, 1mal der Init Wert 1021 zu senden.

Wird im Projekt D4 un";

CM_ SG_ 418 ESP_15_BZ "Botschaftszähler
Botschaft asynchron geroutet. Zählerwert kann springen.";
CM_ SG_ 418 ESP_15_CRC "Für MLB:
'Berechnung siehe Lastenheft 'Kommunikationsabsicherung für FlexRay und CAN''

Ab MQB und MLBevo:
'Berechnung siehe Lastenheft 'End-to-End Kommunikationsabsicherung''

Endwerte siehe Begleitdokument 'S-PDU Kennungsfolgen'

Wird im Projekt";
CM_ SG_ 418 ESP_Haltemoment "Zeigt in Abhängigkeit von ESP_Index_Haltemoment das notwendige Summen-Radmoment an (bergab: Bremsmoment; bergauf: Antriebsmoment), das mindestens notwendig ist um das Fahrzeug an der aktuellen Neigung zu halten.";
CM_ SG_ 418 ESP_Index_Haltemoment "Zeigt an, ob das Summen-Radmoment von ESP_Haltemoment ein Bremsmoment (bergab) oder ein Antriebsmoment (bergauf) darstellt.";
CM_ SG_ 418 HMS_aktives_System "Zeigt an, von welchem System die Anforderung gerade umgesetzt wird.";
CM_ SG_ 418 HMS_Anforderung_GE "Fordert vom Getriebe bestimmte Schaltstellungen an.";
CM_ SG_ 418 HMS_Fehlerstatus "Zeigt den Fehlerstatus des Haltemanagementsystems HMS an.
Details zu den Werten 3/4:
3=Systemeinschränkung, Parken EPB oder GSG nicht möglich
4=Systemstörung bzw. Parken EPB und GSG nicht möglich  ";
CM_ SG_ 418 HMS_halten_nicht_verfuegbar "Rueckmeldung HMS-Teilfunktion 'Halten' nicht verfuegbar.";
CM_ SG_ 418 HMS_Konsistenz_ACC "Zeigt an, ob die Kommunikation und die Anforderungen plausibel sind.";
CM_ SG_ 418 HMS_Konsistenz_GE "Zeigt an, ob die Kommunikation und die Anforderungen plausibel sind.";
CM_ SG_ 418 HMS_Konsistenz_HVLM "Zeigt an, ob die Kommunikation und die Anforderungen plausibel sind.";
CM_ SG_ 418 HMS_Konsistenz_IPA "Zeigt an, ob die Kommunikation und die Anforderungen plausibel sind.
";
CM_ SG_ 418 HMS_Konsistenz_MO "Zeigt an, ob die Kommunikation und die Anforderungen plausibel sind.";
CM_ SG_ 418 HMS_Konsistenz_STA "Zeigt an, ob die Kommunikation und die Anforderungen plausibel sind.";
CM_ SG_ 418 HMS_Notstopp_Status "Statusinformation des Notstoppsystems an die beteiligten Systeme.";
CM_ SG_ 418 HMS_P_beibehalten_GE "Fordert das Getriebe auf in Stellung 'P' zu bleiben.";
CM_ SG_ 418 HMS_parken_nicht_verfuegbar "Rueckmeldung HMS-Teilfunktionen 'Parken' nicht verfuegbar.";
CM_ SG_ 418 HMS_Stillstand "Das Signal zeigt, basierend auf den vier ESP-Raddrehzahlinformatioen, gefiltert und/oder entprellt mehrstufig den Fahrzeuggeschwindigkeitszustand an.";
CM_ SG_ 418 HMS_Systemstatus "Zeigt den aktuellen Systemstatus des HMS an.";
CM_ SG_ 418 NL_PRIM_STP_01_Status "Das Primär- Bremsregelsystem übermittelt seinen Systemstatus an zFAS und Sekundär- Bremsregelsystem. 

Der Staupilot ermittelt sich über den Status des Primär-und des Sekundärbremsregelsystems den Gesamtzustand des Notlaufreglers.";
CM_ SG_ 418 VMM_Warnblinken "Über dieses Signal wird ein Warnblinken von Funktionen des VMM (VehicleMotionManagers) angefordert.";
CM_ SG_ 418 VZM_Status "Zeigt die Verfuegbarkeit und den Zustand der VZM Funktionen im ESC an";

CM_ SG_ 253 ABS_Bremsung "Antiblockiersystem, Bit zeigt auch Druckabbau an (z.B. ESP hat zuviel Druck aufgebaut oder ungebremste Regelung auf Bahnübergang)
Weiterführende Informationen im Lastenheft spezifiziert und in der entsprechenden Fachabteilung zu erfragen.";
CM_ SG_ 253 ASR_Anf "MLB: Die Momentenanforderung 'ASR_MSR_Moment_schnell' und 'ASR_Moment_langsam' sind auszuführen
MQB: Die Momentenanforderung 'BR_Eingriffsmoment' ist auszuführen";
CM_ SG_ 253 ASR_Schalteingriff "Wunsch an das Getriebe während einer ASR Regelung

MLB: Es wird nur 0x0 und 0x1 genutzt

";
CM_ SG_ 253 ASR_Tastung_passiv "ASR deaktiviert oder Schwellen geändert (projektabhängig)
Weiterführende Informationen im Lastenheft spezifiziert und in der entsprechenden Fachabteilung zu erfragen.
";
CM_ SG_ 253 BR_Eingriffsmoment "Einheitenloser Wert! Faktor in MO_Faktor_Momente_02 in Motor_Code_01 beachten!
Schnelle reduzierende (ASR) oder erhöhende (MSR) Momentanforderung an den Motor.";
CM_ SG_ 253 EBV_Eingriff "Elektronische Bremskraftverteilung, aktueller Eingriff (Druckhalten, Druckabbau)

Im MLB: kein ABS / ESP-Eingriff ???";
CM_ SG_ 253 EDS_Eingriff "Elektronische Differentialsperre";
CM_ SG_ 253 ESC_Neutralschaltung "Aufforderung seitens ABS an das Getriebe die Momentenübertragung zu unterbrechen";
CM_ SG_ 253 ESC_v_Signal_Qualifier_High_Low "Das Qualifizerungssignal ESC_v_Signal_Qualifier_High_Low gibt eine Information über die Güte der vom Bremsregelsystem ausgegebenen Geschwindigkeitsinformation 'mittlere Geschwindigkeit', wobei Vertrauensbereiche für das ausgegebene Geschwindigkeitssignal ";
CM_ SG_ 253 ESP_21_CRC "Für MLB:
'Berechnung siehe Lastenheft 'Kommunikationsabsicherung für FlexRay und CAN''

Ab MQB und MLBevo:
'Berechnung siehe Lastenheft 'End-to-End Kommunikationsabsicherung''

Endwerte siehe Begleitdokument 'S-PDU Kennungsfolgen'";
CM_ SG_ 253 ESP_ASP "MLB: Anhaenger-Stabilisierungs-Programm
MQB: Gespannstabilisierung";
CM_ SG_ 253 ESP_Diagnose "MLB: Nach Diagnoseende wird ein SW-Reset ausgelöst welcher einen Kommunikatiosausfall für max. 150ms verursacht. Dies ist bei SG mit verschärfter Timeoutüberwachung (nicht nach Konzern-LH) zu beachten.

MQB: Weiterführende Informationen im Lastenheft sp";
CM_ SG_ 253 ESP_Eingriff "Eingriff des Fahrdynamikreglers";
CM_ SG_ 253 ESP_QBit_v_Signal "Geschwindigkeit wird vom ABS/ASR oder ESP aus Ersatzwerten errechnet, wenn Bit gesetzt ist. Güte des Signals ist verändert.";
CM_ SG_ 253 ESP_Systemstatus "Fehler steht für Stillegung ESP mit Fehlereintrag.

MLB: Flag wird bei Unterspannung im Stand bis einmalig 6km/h (AU48x) oder 10 km/h (AU641, AU57x) überschritten nicht gesetzt (Ausblendung Startvorgang)
Im AU64x, AU57x gilt ESP D4 Funktionsanforderung";
CM_ SG_ 253 ESP_Tastung_passiv "ESP deaktiviert oder Schwellen geändert (projektabhängig)
Weiterführende Informationen im Lastenheft spezifiziert und in der entsprechenden Fachabteilung zu erfragen.";
CM_ SG_ 253 ESP_v_Signal "Geschwindigkeitssignal vom ABS/ASR oder ESP. Mittelwert der angetriebenen Räder.
Bei MSR oder ABS Eingriffen wird die ABS-Referenzgeschwindigkeit für >= 200ms eingespiegelt (Zeit wird mit Aktiv-Flanke der Funktionsbits getriggert)

MQB: Bei Frontantrie";
CM_ SG_ 253 ESP_Vorsteuerung "zur Unterscheidung zwischen ESP-Vorsteuermaßnahmen und ESP-Regeleingriffen";
CM_ SG_ 253 MSR_Anf "MLB: Die Momentenanforderung 'ASR_MSR_Moment_schnell' ist auszuführen.
MQB: Die Momentenanforderung 'BR_Eingriffsmoment' ist auszuführen";
CM_ SG_ 253 MSR_verfuegbar "Anzeige Verfügbarkeit der MSR Funktion 
0 = verfuegbar (MSR_Vollsystem oder MSR_Backup)
1 = nicht_verfuegbar (Init und Fehler)";
CM_ SG_ 253 OBD_Schlechtweg "Für Ausblendung der Zündaussetzererkennung im Motorsteuergerät (Otto). Bit wird gesetzt, wenn Rad-Drehbeschleunigung im ESP > Grenzwert ist. Vorteil gegenüber Radgeschwindigkeiten, dass ESP alle 2 ms dynamisch die Rad-Drehbeschleunigung errechnet und dem ";

CM_ SG_ 1470 BR_QBit_Reifenumfang_sekundaer "QBit des Signals BR_Reifenumfang_sekundaer. 
Gesetzt bei Ersatzwert, Init oder Fehler.";
CM_ SG_ 1470 BR_Reifenumfang_sekundaer "Radumfang der Sekundärchse gerechnet in Millimeter.
Von der Bremse plausibilisierter Wert (Kopie von KBI_Reifenumfang_sekundaer wenn dieser plausibel) 
oder Ersatzwert aus Bremse wenn KBI_Reifenumfang_sekundaer unplausibel. Bitte das QBit beachten!
";
CM_ SG_ 1470 ESP_23_CRC "Für MLB:
'Berechnung siehe Lastenheft 'Kommunikationsabsicherung für FlexRay und CAN''

Ab MQB und MLBevo:
'Berechnung siehe Lastenheft 'End-to-End Kommunikationsabsicherung''

Endwerte siehe Begleitdokument 'S-PDU Kennungsfolgen'";
CM_ SG_ 1470 ESP_Gierrate_Offset_2 "Gierratenoffset berechnet durch ESP-Modell. 

nur für MLBevo gilt:
Der Offsetwert entspricht der Abweichung nach Anti-DIN-Vorzeichenlogik.
Gierrate_korrigiert = Gierrate_Rohwert + Gierratenoffset";
CM_ SG_ 1470 ESP_Laengsbeschleunigung_Offset "Offset der Längsbeschleunigung
Längsbeschleunigung = Rohwert - Offset

nur für MLBevo gilt:
Laengsbeschleunigungsoffset berechnet durch ESP-Modell. 
Laengsbeschleunigung_korrigiert = Laengsbeschleunigung_Rohwert - Laengsbeschleunigungsoffset";
CM_ SG_ 1470 ESP_Lenkwinkel_Offset "Lenkwinkelsoffset berechnet durch ESP-Modell!

nur für MLBevo gilt:
Der Offsetwert entspricht der Abweichung nach Anti-DIN-Vorzeichenlogik.
Lenkwinkel_korrigiert = Lenkwinkel_Rohwert + Lenkwinkeloffset";
CM_ SG_ 1470 ESP_Querbeschleunigung_Offset "Offset der Querbeschleunigung
Querbeschleunigung = Rohwert - Offset

nur für MLBevo gilt:
Querbeschleunigungsoffset berechnet durch ESP-Modell. 
Der Offsetwert entspricht der Abweichung nach Anti-DIN-Vorzeichenlogik.
Querbeschleunigung_korrigiert = ";
CM_ SG_ 1470 ESP_Status_Bremsentemp_Anz "Anzeigesignal für Bremsentemperatur";

CM_ SG_ 508 ESC_Anforderung_Airbrake "ESC fordert die Bremsperformancestellung der aktiven Aerodynamik";
CM_ SG_ 508 ESC_FBA_Meldungen "Hinweis an den Fahrer über das Kombi, bei dauerhafter Bergabfahrt einen Gang einzulegen um die Motorbremse zu nutzen.
Unterscheidung zwischen: 
Handschalterfahrzeugen (FBA_Warnung_aktiv_MT)
Automatikfahrzeugen (FBA_Warnung_aktiv_AT)";
CM_ SG_ 508 ESC_MBK_Meldungen "Das Signal steuert die Schaltempfehlung im Kombi, die bei Bergabfahrt den Fahrer darauf hinweist in eine geeignete Fahrstufe zu schalten um eine Rekuperation zu ermöglichen.";
CM_ SG_ 508 ESC_Motorstartverzoegerung "Mit dem Signal 'Motorstartverzögerung' wird den aktiven Teilnehmern ermöglicht, einen Motorstart durch die Start-Stop-Funktion zu verzögern.";
CM_ SG_ 508 ESP_32_BZ "Botschaft asynchron geroutet. Zählerwert kann springen.";
CM_ SG_ 508 ESP_32_CRC "Für MLB:
'Berechnung siehe Lastenheft 'Kommunikationsabsicherung für FlexRay und CAN''

Ab MQB und MLBevo:
'Berechnung siehe Lastenheft 'End-to-End Kommunikationsabsicherung''

Endwerte siehe Begleitdokument 'S-PDU Kennungsfolgen'";
CM_ SG_ 508 ESP_Aggregataktivitaet "Info über die Aktivität des ESP Aggregats bei aktivem Druckaufbau oder Ventilaktivität";
CM_ SG_ 508 ESP_AVH_LED "Ansteuerung der AVH Funktions-LED durch das BCM.
0 = LED aus
1 = LED ein
2 = LED blinken
3 = Funktion gesperrt, LED aus
4 = frei
5 = frei
6 = Init
7 = frei";
CM_ SG_ 508 ESP_EDS_Anzeige "Grafische Anzeige der EDS-Funktion im Kombiinstrument und MMI für Bentley";
CM_ SG_ 508 ESP_HDC_LED "Ansteuerung der HDC LED in der Schalterleiste durch BCM
0 = LED aus
1 = LED ein
2 = LED blinken
3 = Funktion gesperrt, LED aus
4 = frei
5 = frei
6 = Init
7 = frei";
CM_ SG_ 508 ESP_HDC_Textanzeigen "Textanzeigen der HDC im Kombiinstrument
Zustände 16,17,18 nur für Porsche";
CM_ SG_ 508 ESP_HOLD_verf "Das Signal ESP_HOLD_verf = 1 signalisiert dem Empfänger, dass die Aktivierungsbedingungen für die autonome HOLD-Funktion erfüllt sind (Steigung > parametrierbare Grenzsteigung mit Wunschfahrtrichtung bergauf) und die autonome HOLD-Funktion aktivierbar ist";
CM_ SG_ 508 ESP_Notbremsanzeige "ABS/ASR oder ESP hat Notbremssituation erkannt.
Weiterführende Informationen im Lastenheft spezifiziert und in der entsprechenden Fachabteilung zu erfragen.

";
CM_ SG_ 508 ESP_Off_LED "Ansteuerung der ESP-Off LED in der Schalterleiste durch BCM
0 = LED aus
1 = LED ein
2 = LED blinken
3 = Funktion gesperrt, LED aus
4 = frei
5 = frei
6 = Init
7 = frei";
CM_ SG_ 508 ESP_Offroad_Lampe "Anzeige der ESC-Offroad-Lampe im Kombiinstrument für Bentley";
CM_ SG_ 508 ESP_Rollover_Status_dyn "Information vom ESP an die Dämpferregelung über den dynamischen Rolloverstatus";
CM_ SG_ 508 ESP_Rollover_Status_stat "Information vom ESP an die Dämpferregelung über den statischen Rolloverstatus";
CM_ SG_ 508 ESP_Status_Bremsentemp_02 "Bremsscheibentemperaturmodell. Rückmeldung für Sender einer Verzögerungsanforderung";
CM_ SG_ 508 ESP_Stillstandsflag "Bei RB-Projekten wird das Stillstandsflag gesetzt, wenn der absolute Stillstand der Raddrehzahlsensoren erkannt wurde, d.h. kein Zahn bewegt sich mehr. Dieses Bit wird bspw. im MOST für TV-Tuner-Abschaltung Australien verwendet, d.h. leichte Erschütterung";
CM_ SG_ 508 ESP_Wiederstart_Anz_Std "Dieses Signal gibt die detaillierte Begründung für einen Wiederstart vom Bremsensteuergerät ausgelöst durch die HBC Funktion an.";
CM_ SG_ 508 RLE_Anzeigen "Anzeigen für die Radlöseerkennung";

CM_ SG_ 427 ESC_AHW_aktiv "Rueckmeldung Anhaltewegregelung aktiv
";
CM_ SG_ 427 ESC_AHW_nicht_verfuegbar "Rueckmeldung Anhaltewegregelung nicht verfuegbar
";
CM_ SG_ 427 ESC_ANB_CM_aktiv "Rueckmeldung ANB_CM (Autom_Notbremsung_Collision_Mitigation) aktiv
";
CM_ SG_ 427 ESC_ANB_CM_nicht_verfuegbar "Rueckmeldung ANB_CM nicht verfuegbar
";
CM_ SG_ 427 ESC_Bremslicht_unplausibel "Plausibilisierung der Rückmeldeinformation von BCM/AAG bezüglich Anforderung ESC_Bremslicht";
CM_ SG_ 427 ESC_Fahrer_Bremsdruck_bestimmend "Das Signal zeigt an, dass der Fahrer Bremsdruck bestimmend ist";
CM_ SG_ 427 ESC_HBA_aktiv "Rueckmeldung HBA (hydraulischer Bremsassistent) aktiv";
CM_ SG_ 427 ESC_HBA_nicht_verfuegbar "Rueckmeldung HBA (hydraulischer Bremsassistent) nicht verfuegbar";
CM_ SG_ 427 ESC_Konsistenz_ACC "Rueckmeldung Konsistenz der ACC Botschaften";
CM_ SG_ 427 ESC_Konsistenz_AGW "Rückmeldung Konsistenz der AGW-Botschaft an das ESC.";
CM_ SG_ 427 ESC_Konsistenz_ARA "Rueckmeldung Konsistenz der ARA Botschaften";
CM_ SG_ 427 ESC_Konsistenz_AWA "Rueckmeldung Konsistenz der AWA-Botschaften";
CM_ SG_ 427 ESC_Konsistenz_AWV "Rueckmeldung Konsistenz der AWV Botschaften";
CM_ SG_ 427 ESC_Konsistenz_BFF "Rückmeldung Konsistenz der Verzögerungsanforderung an das ESC-Steuergerät der Funktion 'Bremsen im freien Fahren' vom PDC_PLA_ARA-Steuergerät";
CM_ SG_ 427 ESC_Konsistenz_EA "Rueckmeldung Konsistenz der EA Botschaften (HCA)";
CM_ SG_ 427 ESC_Konsistenz_FAS_VK "Rueckmeldung Konsistenz der FAS_VK Botschaften";
CM_ SG_ 427 ESC_Konsistenz_FCW "Rueckmeldung Konsistenz der FCW Botschaften";
CM_ SG_ 427 ESC_Konsistenz_IPA "Rueckmeldung Konsistenz der IPA Botschaften";
CM_ SG_ 427 ESC_Konsistenz_KAS "Rückmeldung Konsistenz für Kreuzungsassistent-Anforderungen";
CM_ SG_ 427 ESC_Konsistenz_MKB "Rückmeldung Konsistenz für MKB-Verzögerungsanfoorderung";
CM_ SG_ 427 ESC_Konsistenz_NV "Rueckmeldung Konsistenz der NightVision Botschaften";
CM_ SG_ 427 ESC_Konsistenz_PCF "Rückmeldung der Konsistenz der PCF-Anforderungen";
CM_ SG_ 427 ESC_Konsistenz_RCTA "Rueckmeldung Konsistenz der RCTA (Rear Cross Traffic Alert) Botschaften";
CM_ SG_ 427 ESC_Konsistenz_STA "Rueckmeldung Konsistenz der STA Botschaften";
CM_ SG_ 427 ESC_Konsistenz_TSK "Rueckmeldung Konsistenz der TSK Botschaften";
CM_ SG_ 427 ESC_Konsistenz_vFGS "Rueckmeldung Konsistenz der vFGS Botschaften";
CM_ SG_ 427 ESC_Prefill_aktiv "Rueckmeldung Prefill aktiv";
CM_ SG_ 427 ESC_Prefill_nicht_verfuegbar "Rueckmeldung Prefill nicht verfuegbar";
CM_ SG_ 427 ESC_Pumpenanlauf_aktiv "Bestätigung der Durchführung eines Vorsteuerpumpenanlaufes";
CM_ SG_ 427 ESC_TSK_SRBM_Anf "Quittierung fuer TSK (SRBM=Summenradbremsmoment) Anforderung";
CM_ SG_ 427 ESC_TSK_SRBM_nicht_verfuegbar "Rueckmeldung TSK (SRBM= Summenradbremsmoment) nicht verfuegbar";
CM_ SG_ 427 ESC_Verz_ASIL_Verfuegbarkeit "Gibt die Verfuegbarkeit der VZM-Regelung an, wobei folgende Zustaende beruecksichtigt werden:
-Nicht Verfuegbarkeit wegen Sonderbetriebszustaenden (z.B. Produktionsmodus)
-ueber VZM abgebaute Fahrzeuggeschwindigkeit bei Verzögerungen a>5m/s², wobei gilt";
CM_ SG_ 427 ESC_Verz_Begrenzung "Rückmeldung angeforderte Verzögerung oder Summenradbremsmoment wird begrenzt umgesetzt  ";
CM_ SG_ 427 ESC_Verz_Reg_aktiv "Rueckmeldung Verzoegerungsregelung aktiv";
CM_ SG_ 427 ESC_Verz_Reg_nicht_verfuegbar "Rueckmeldung Verzoegerungsregelung nicht verfuegbar";
CM_ SG_ 427 ESC_Verz_Reg_TB_nicht_verfuegbar "Rueckmeldung Verzoegerungsregelung (Teilbremsung) nicht verfuegbar";
CM_ SG_ 427 ESC_Verz_Reg_ZB_nicht_verfuegbar "Rueckmeldung Verzoegerungsregelung ZB (Zielbremsung) nicht verfuegbar";
CM_ SG_ 427 ESC_Warnruck_aktiv "Rueckmeldung Warnruck aktiv";
CM_ SG_ 427 ESC_Warnruck_nicht_verfuegbar "Rueckmeldung Warnruck nicht verfuegbar";
CM_ SG_ 427 ESP_33_BZ "Botschaft asynchron geroutet. Zählerwert kann springen.";
CM_ SG_ 427 ESP_33_CRC "Für MLB:
'Berechnung siehe Lastenheft 'Kommunikationsabsicherung für FlexRay und CAN''

Ab MQB und MLBevo:
'Berechnung siehe Lastenheft 'End-to-End Kommunikationsabsicherung''

Endwerte siehe Begleitdokument 'S-PDU Kennungsfolgen'";

CM_ SG_ 264 EFP_Anf_Bremsenkuehlung "Signal steuert das Oeffnen des Bremsenkuehlkanals und ggf. das Aktivieren eines unterstützenden Lüfters.";
CM_ SG_ 264 EFP_Reibwert_dyn "Dynamisch geschaetzter Reibwert zwischen Reifen und Strasse im Grenzbereich (Variante 2)";
CM_ SG_ 264 FA_Fahrbahnunebenheit "Informationsbeschreibung des Fahrbahnzustandes";
CM_ SG_ 264 FA_Hoehenwert_HL_00 "Aktueller Höhenwert (kalibriert) Hinten Links; ungefiltertes Signal
Einheit, Offset und Faktor sind abhänig von 'FA_Hoehenwert_kalibriert'

Achtung:
Wird im AUDI B8 nicht bedient";
CM_ SG_ 264 FA_Hoehenwert_HR_00 "Aktueller Höhenwert (kalibriert) Hinten Rechts; ungefiltertes Signal
Einheit, Offset und Faktor sind abhänig von 'FA_Hoehenwert_kalibriert'

Achtung:
Wird im AUDI B8 nicht bedient";
CM_ SG_ 264 FA_Hoehenwert_VL_00 "Aktueller Höhenwert (kalibriert) Vorne Links; ungefiltertes Signal
Einheit, Offset und Faktor sind abhänig von 'FA_Hoehenwert_kalibriert'

Achtung:
Wird im AUDI B8 nicht bedient";
CM_ SG_ 264 FA_Hoehenwert_VR_00 "Aktueller Höhenwert (kalibriert) Vorne Rechts; ungefiltertes Signal
Einheit, Offset und Faktor sind abhänig von 'FA_Hoehenwert_kalibriert'

Achtung:
Wird im AUDI B8 nicht bedient";
CM_ SG_ 264 FA_Hoehenwerte_kalibriert "Legt fest, wie die Höhensensorwerte interpretiert werden müssen. Umschaltung kalibrierte Höhenwerte / Rohsignale in Byte 3-6

Achtung:
Im AUDI B8 Konstante: 0x1. D.h. es werden nur Rohwerte bedient!
Im AUDI D4 Konstante: 0x0. D.h. es werden nur Millim";
CM_ SG_ 264 Fahrwerk_01_CRC "Für MLB:
'Berechnung siehe Lastenheft 'Kommunikationsabsicherung für FlexRay und CAN''

Ab MQB und MLBevo:
'Berechnung siehe Lastenheft 'End-to-End Kommunikationsabsicherung''

Endwerte siehe Begleitdokument 'S-PDU Kennungsfolgen'";

CM_ SG_ 429 EFP_Soll_FahrPr_HAL "Anforderung einer Zwangsumschaltung des Fahrprogramms der HAL durch EFP";
CM_ SG_ 429 FA_Absenkung_Fahrzeug "Nächsttieferes Niveau wird angefahren (Absenken). Dieses Bit wird immer gesetzt in Verbindung mit einer Auswahl aus den Bits FA_Verstellung_xx.";
CM_ SG_ 429 FA_Anhaengerstatus_intern "Anzeige des SG-internen Verarbeitungsstatus Anhängers";
CM_ SG_ 429 FA_Anhebung_Fahrzeug "Nächsthöheres Niveau wird angefahren (Anheben). Dieses Bit wird immer gesetzt in Verbindung mit einer Auswahl aus den Bits FA_Verstellung_xx.";
CM_ SG_ 429 FA_Druckspeicher_verfuegbar "Bit ist gesetzt, wenn eine Regelung aus dem Druckspeicher möglich ist.";
CM_ SG_ 429 FA_ESP_Zuschaltung "Zwangsweise Aktivierung der ESP-Funktionalität wird angefordert auch bei Passivtastung";
CM_ SG_ 429 FA_HAL_Abschaltung "Anforderung einer Zwangs-Deaktivierung der HAL wegen zu geringem
Radfreigang durch Luftfeder oder Schneekettenbetrieb.";
CM_ SG_ 429 FA_Kompressor_laeuft "Zustand der Kompressoransteuerung";
CM_ SG_ 429 FA_Kompressor_laeuft_in_Kuerze "Kompressorlauf steht unmittelbar bevor. Das Bit wird immer gesetzt in Verbindung mit den Bits FA_Anhebung_Fahrzeug oder FA_Absenkung_Fahrzeug.";
CM_ SG_ 429 FA_Signal_Drucksensor "Signalwert des Drucksensors im Magnetventilblock";
CM_ SG_ 429 FA_Systemstatus "Bit wird gesetzt, wenn interne Funktionsprüfung i.O. und System generell funktionsfähig ist.";
CM_ SG_ 429 FA_Verstellung_aktiv "Verstellung ist aktiv. Dieses Bit wird immer gesetzt in Verbindung mit den Bits FA_Anhebung_Fahrzeug oder FA_Absenkung_Fahrzeug.";
CM_ SG_ 429 FA_Verstellung_in_Kuerze "Dieses Bit wird gesetzt, wenn eine Verstellung unmittelbar bevorsteht.";
CM_ SG_ 429 FA_Zwischenniveau "Dieses Bit wird gesetzt, wenn die Fahrzeughöhe zwischen 2 definierten Niveaus liegt, z.B.. während des Regelvorgangs.";
CM_ SG_ 429 Fahrwerk_06_BZ "Botschaft asynchron geroutet. Zählerwert kann springen.";
CM_ SG_ 429 Fahrwerk_06_CRC "Ab MQB und MLBevo:
'Berechnung siehe Lastenheft 'End-to-End Kommunikationsabsicherung''

Endwerte siehe Begleitdokument 'S-PDU Kennungsfolgen'";
CM_ SG_ 429 NR_Anforderung_v_Begrenzung "Anforderung einer v-Begrenzung an das Motor-SG.";
CM_ SG_ 429 NR_Kompressor_Strom_02 "Gemessener Strom am Kompressors.";
CM_ SG_ 429 NR_Kompressor_Temp_Zylinderkopf "Gemessene Temperatur im Zylinderkopf des Luftfeder-Kompressors";
CM_ SG_ 429 NR_LED_BN "Statusrückmeldung der eingestellten Fahrzeughöhe Beladungsniveau bzw. Tasterbetätigung Anheben/Absenken.";
CM_ SG_ 429 NR_LED_HN "Statusrückmeldung der eingestellten Fahrzeughöhe Hochniveau
";
CM_ SG_ 429 NR_LED_SGN "Statusrückmeldung der eingestellten Fahrzeughöhe Sondergeländeniveau bzw. Tasterbetätigung Anheben/Absenken.";
CM_ SG_ 429 NR_LED_TN "Statusrückmeldung der eingestellten Fahrzeughöhe Tiefniveau";
CM_ SG_ 429 NR_Reglerstatus "Anzeige des auszuregelnden Sollniveaus (wird bei Beginn der Regelung auf entsprechenden Wert gesetzt).";

CM_ SG_ 852 FB_Kopf_erkannt "Erkennung des Fahrerkopf";
CM_ SG_ 852 FB_Lidoeffnungs_Dauer "durchschnittliche Lidöffnungsdauer";
CM_ SG_ 852 FB_Lidschlag_Dauer "durchschnittliche Lidschlagdauer";
CM_ SG_ 852 FB_Lidschlag_Frequenz "Lidschläge pro Sekunde";
CM_ SG_ 852 FB_Lidschlag_Guete "Güte der Lidschlagerkennung";
CM_ SG_ 852 FB_Lidschliess_Dauer "durchschnittliche Lidschliessdauer";
CM_ SG_ 852 FB_Lidschluss_Dauer "durchschnittliche Lidschlussdauer";

CM_ SG_ 2527679660 FB_Blindheit "Blindheit: Sensor operativ aber Sichtbeeinträchtigung";
CM_ SG_ 2527679660 FB_Fahrerwechsel "Fahrerwechsel erkannt";
CM_ SG_ 2527679660 FB_Fehler "Fehler liegt vor";
CM_ SG_ 2527679660 FB_Kopfaktivitaet_A1 "kurzfristige Kopfbewegungen
";
CM_ SG_ 2527679660 FB_Kopfaktivitaet_A1_Guete "Guete kurzfristige Kopfbewegung";
CM_ SG_ 2527679660 FB_Kopfaktivitaet_A2 "langfristige Kopfbewegungen
";
CM_ SG_ 2527679660 FB_Kopfaktivitaet_A2_Guete "Guete Langfristige Kopfbewegung";
CM_ SG_ 2527679660 FB_Muedigkeit_Guete "Güte der Müdigkeitserkennung";
CM_ SG_ 2527679660 FB_Muedigkeit_Index "Müdigkeitsignal nach HFC Müdigkeitsskala";
CM_ SG_ 2527679660 FB_NichtVerfuegbar "Fahrerbeobachtung nicht verfügbar";

CM_ SG_ 853 FB_Blickbereich "Enumeration Blickbereich";
CM_ SG_ 853 FB_Blickbereich_Guete "Güte der Blickbereichserkennung";
CM_ SG_ 853 FB_Kopfrotation_Nick "Nickwinkel des Kopfes im Kopfkoordinatensystem";
CM_ SG_ 853 FB_Kopfrotation_Nick_Guete "Güte des Nickwinkels";
CM_ SG_ 853 FB_Kopfrotation_Roll "Rollwinkel des Kopfs im Kopfkoordinatensystem";
CM_ SG_ 853 FB_Kopfrotation_Roll_Guete "Güte des Rollwinkels";

CM_ SG_ 854 FB_Kopfposition_X "Kopfposition in X  (Fzg Koordinatensystem VW 01052)";
CM_ SG_ 854 FB_Kopfposition_X_Guete "Güte der Kopfposition in Richtung X";
CM_ SG_ 854 FB_Kopfposition_Y "Kopfposition in  Y (Fzg Koordinatensystem VW 01052)";
CM_ SG_ 854 FB_Kopfposition_Y_Guete "Güte der Kopfposition in Richtung Y";
CM_ SG_ 854 FB_Kopfposition_Z "Kopfposition in Z  (Fzg Koordinatensystem VW 01052)";
CM_ SG_ 854 FB_Kopfposition_Z_Guete "Güte der Kopfposition in Richtung Z";
CM_ SG_ 854 FB_Kopfrotation_Gier "Gierwinkel des Kopfes im Kopfkoordinatensystem";
CM_ SG_ 854 FB_Kopfrotation_Gier_Guete "Güte des Gierwinkels";

CM_ SG_ 1605 FLA_Abblendursache "FLA Abblendursache
(20ms Task)";
CM_ SG_ 1605 FLA_aktiv "FLA aktiv  (200ms Task)";
CM_ SG_ 1605 FLA_Aufblenden "FLA Aufblenden (20ms Task)";
CM_ SG_ 1605 FLA_Fernlicht_PWM "FLA PWM Vorgabe Fernlicht
(20ms Task)";
CM_ SG_ 1605 FLA_ISP_defekt "FLA defekt (Innenspiegelkamera oder Multifunktionskamera)
interner Fehler  (200ms Task)";
CM_ SG_ 1605 FLA_SAE_Mode "Rückmeldung an den Fahrer, über Wechsel in den SAE Modus --> wird nur für den amerikanischen Markt benötigt.";
CM_ SG_ 1605 FLA_Sensor_blockiert "FLA Sensor blockiert
Sichtbeeinträchtigung der Kamera  (200ms Task)";
CM_ SG_ 1605 ISP_Dimmung_ASP_02 "Dimmwertvorgabe für Aussenspiegel
Es wird 1:1 die Spannung am Innenspiegel nach außen übertragen.";
CM_ SG_ 1605 ISP_EC_aktiv "Status Innenspiegel (EC-Spiegel)";
CM_ SG_ 1605 ISP_EC_Lichtwert_hinten "Innenspiegel: Lichtwert hinten
";
CM_ SG_ 1605 ISP_EC_Lichtwert_vorne "Innenspiegel: Lichtwert vorne
";
CM_ SG_ 1605 ISP_Himmelsrichtung "Himmelsrichtung Kompass im EC Spiegel
Wertebereich 0-29 (12°-Schritte, 0-348°)
";
CM_ SG_ 1605 ISP_Kompass_aktiv "Status Kompass Innenspiegel";
CM_ SG_ 1605 ISP_Taste_betaetigt "ISP Taste betätigt
(200ms Task)";

CM_ SG_ 2589283684 FoD_Anz_Funktionsabschaltung "Signal triggert Aufschaltung eines Popups, um dem Fahrer die Abschaltung einer Funktion zu melden.";
CM_ SG_ 2589283684 FoD_Transmission_Info "Mit dem Signal zeigt der FoD-Master allen FoD-Slaves den Beginn und das Ende eines Freischaltuebertragungszykluses (FS-ID-Zyklus) an.";

CM_ SG_ 2549875470 FoD_BCM1_Req_Data "FoD - Function On Demand
ISO-TP Datenkanal - FID2NA
Request Funktion 0x03 FoD-Master

FoD-Master an BCM1";

CM_ SG_ 2550006542 FoD_BCM1_Resp_Data "FoD - Function On Demand
ISO-TP Datenkanal - FID2NA
Response Knoten 0x0E BCM

BCM an FoD Master";

CM_ SG_ 1523 Diag_Frontscheibe "Übertragung der Fehler:
    Bit 1: Unterer Grenzwert unterschritten
    Bit 2: Oberer Grenzwert ueberschritten
    Bit 3: zur Zeit nicht pruefbar
    Bit 4: Unterbrechung
    Bit 5: El. Fehler im Stromkreis 
    Bit 6: El. Fehler im Stromkreis 
   ";
CM_ SG_ 1523 FSH_LED "LED Ansteuerung Frontscheibenheizung";
CM_ SG_ 1523 HW_SW_Frontscheibe "HW/SW-Version:
    HW Bit 1..4
    SW Bit 5..8";
CM_ SG_ 1523 I_Heiz_Frontscheibe "Stromaufnahme Frontscheibenheizung";
CM_ SG_ 1523 P_Heiz_Frontscheibe "aktuelle Leistungsaufnahme";
CM_ SG_ 1523 R_grenz_max "Oberer Widerstandsgrenzwert";
CM_ SG_ 1523 R_grenz_min "Unterer Widerstandsgrenzwert";
CM_ SG_ 1523 R_ist "aktueller Widerstandsmesswert";

CM_ SG_ 173 GE_Fahrstufe "Fahrprogramm des Getriebes

Hinweis: Zwischenstellung '0x0' darf nur für Zustandswechsel P/R, R/N, N/D ausgegeben werden, nicht für D/S oder D/Tippgasse wegen Abschaltkriterium GRA/ACC";
CM_ SG_ 173 GE_Freig_MMom_Vorhalt "Freigabe für die Anforderung einer Momentenreserve durch das Getriebe über das Signal
MLB: GE_MMom_Vorhalt
MQB/MLBevo: GE_MMom_Vorhalt_02";
CM_ SG_ 173 GE_MMom_Soll_02 "Momenteneingriff an den Motor.
Fordert vom MSG eine kurzfristige Reduzierung oder Anhebung des Moments.
Das Signal ist nur gültig in Kombination mit GE_MMom_Status (bei MQB) bzw. GE_MMom_Status_02 (bei MLBevo).

Achtung:
Einheitenloser Wert! Faktor i";
CM_ SG_ 173 GE_MMom_Status "Qualifiziert 
MLB: GE_MMom_Soll
MQB: GE_MMom_Soll_02";
CM_ SG_ 173 GE_MMom_Status_02 "Das Signal qualifiziert GE_MMom_Soll_02 und gibt an, wie der Wert aus GE_MMom_soll – vorbehaltlich der Umsetzbarkeit aufgrund motorinterner Restriktionen – umgesetzt werden soll.
Werte:
0= kein Eingriff
1=   absoluter reduzierender Eingriff auf Gesamt ";
CM_ SG_ 173 GE_MMom_Vorhalt_02 "Anforderung einer Momentenreserve durch das Getriebe, gilt nur mit Freigabe durch 
GE_Freig_MMom_Vorhalt

Anforderung wird als Absolut-Wert umgesetzt, nicht als Relativ-Wert/Delta zum aktuellen Ist-Moment (d. h. eine Momentenreserve wird eingestellt, w";
CM_ SG_ 173 GE_reserv_Fahrstufe "reserviert, falls künftig Erweiterung von GE_Fahrstufe nötig";
CM_ SG_ 173 GE_Schaltablauf "Das Signal zeigt den aktuellen Status eines Schaltvorgangs.

Bei Signal = 0 liegt kein Schaltvorgang vor.
Bei Signal =2 liegt die Befüllphase der zuschaltenden Kupplung bzw. 
                      die Vorbereitungsphase dazu vor.

Mit den unterschie";
CM_ SG_ 173 GE_Status_Kraftschluss "Zeigt den Ist-Status des Kraftschlusses im Getriebe.
(Anmerkung: meist wird damit der Zustand des Anfahrelements beschrieben, d.h. bei DL/DQ die Kupplung;  bei AQ/AL der Wandler incl. Überbrückungskupplung)
0 = offen, kein Kraftschluss
1 = offen mit Kr";
CM_ SG_ 173 GE_Uefkt "Übertragungsfunktion des Getriebes
Drehzahlverhältnis = Eingangsdrehzahl / Ausgangsdrehzahl

AL: Wandlerverstärkung x Drehzahlverhältnis
VL: Drehzahlverhältnis
DL: Drehzahlverhältnis der aktiven und kraftschluß führenden Welle zum Abtrieb, bei Schalt";
CM_ SG_ 173 GE_Uefkt_unplausibel "Das Signal darf nur im Reku-Manager in Hybrid-Varianten verwendet werden.
Zeigt an, ob die Plausibilisierung Momenten-Verhältnis zu Drehzahl-Verhältnis i.O. ist.
Ein gesetztes Signal meldet eine unplausible GE_Uefkt bzw. GE_Uefkt_02.";
CM_ SG_ 173 GE_Verbot_Ausblendung "Verbot Einspritzausblendung für komfortable Schaltungen";
CM_ SG_ 173 GE_Zielgang "VL-Getriebe:
Signalisiert den Zielgang im manuellen Modus während eines Schaltvorgangs bzw. die momentane simulierte Gangstufe wenn kein Schaltvorgang aktiv ist. In den Fahrprogrammen 'D' und 'S' ist die Übersetzung variabel und somit wird dauerhaft 'Ist";
CM_ SG_ 173 Getriebe_11_BZ "Botschaftszähler
Botschaft asynchron geroutet. Zählerwert kann springen.";
CM_ SG_ 173 Getriebe_11_CRC "Für MLB:
'Berechnung siehe Lastenheft 'Kommunikationsabsicherung für FlexRay und CAN''

Ab MQB und MLBevo:
'Berechnung siehe Lastenheft 'End-to-End Kommunikationsabsicherung''

Endwerte siehe Begleitdokument 'S-PDU Kennungsfolgen'";

CM_ SG_ 177 GE_Anschleppstart_Freigabe "Bilden einer Schleppstartfreigabe aus Fahrdynamiksicht. Schleppstartabbruch bei kritischer Fahrzeugstabilität";
CM_ SG_ 177 GE_Eingangsdrehz_Praed "prädizierte Getriebe-Eingangsdrehzahl (während Schaltungen kann die voraussichtliche Drehzahl am Ende der Schaltung gezeigt werden)";
CM_ SG_ 177 GE_Fahrprogramm "Signalisiert das Fahrprogramm  im Bezug auf
die Fahrstufe des Getriebes.

Audi/MQB:
Offroad

Bentley:
Snow
Gravel
Mud_Ruts
Sand_Dune

Touareg:
Offroad
Snow";
CM_ SG_ 177 GE_Freilauf_Status "Freilauf-Status-Signal vom Frailauf-Master an aktive Freilauf-Teilnehmer. In diesem Signal zeigt der Freilauf-Master an, welchen aktuellen Status die Freilauf-Betriebsstrategie hat.";
CM_ SG_ 177 GE_Getriebestatus_02 "Signalisierung von speziellen Betriebszuständen des Getriebes:
1= Rennstartvorbereitung; genutzt im MSG zum Aufbau einer Momentenreserve, in Allrad und Quersperre (GQS)
2= Rennstart; nicht genutzt im MSG
3= Anfahrt; genutzt im MSG zur Umschaltung des F";
CM_ SG_ 177 GE_Grundeinstellung "Grundeinstellung des Getriebes ist aktiv

Hinweis:
Verwendung nur im MQB";
CM_ SG_ 177 GE_KomFehler_ESP "Anzeige Kommunikationsfehler bei Empfang vom ESP.

Einsatz nur in PDK-Projekten.";
CM_ SG_ 177 GE_Rollrichtung_falsch "Rollrichtung des Fahrzeugs ist entgegen der eingelegten Fahrstufe (bezogen auf GE_Fahrstufe);
0 = Rollrichtung richtig bzw. Init (auch im Stillstand bzw. in P/N/Zwischenposition)
1 = Rollrichtung falsch";
CM_ SG_ 177 GE_Strombedarf_erh "Das GSG teilt dem MSG einen aufgrund der Kühlung erhöhten Strombedarf mit, damit gleichzeitig die Kühler-Lüfter-Ansteuerung kurzzeitig reduziert wird.

Signal wird bisher nur im MQB-PHEV verwendet.";
CM_ SG_ 177 GE_TippZustand "Zeigt den Tippzustand in eine Fahrstufe und ein Fahrprogramm via Paddles oder Schaltbetätigung an.
Das Signal ist gültig in Kombination mit GE_Fahrstufe und GE_Fahrprogramm.

MLBevo:
DL und AL: nur Tipp_in_permanent
PDK2: Tipp_in_temporaer und Tipp_i";
CM_ SG_ 177 GE_Uefkt_Praed "Praedizierte Triebstrangübertragungsfunktion 
(Verständnis Übertragungsfunktion gemäß Ge_Uefkt_02)
Weiterführende Informationen sind bei der entsprechenden Fachabteilung zu erfragen.";
CM_ SG_ 177 Getriebe_17_BZ "Botschaftszähler
Botschaft asynchron geroutet. Zählerwert kann springen.";
CM_ SG_ 177 Getriebe_17_CRC "Für MLB:
'Berechnung siehe Lastenheft 'Kommunikationsabsicherung für FlexRay und CAN''

Ab MQB und MLBevo:
'Berechnung siehe Lastenheft 'End-to-End Kommunikationsabsicherung''

Endwerte siehe Begleitdokument 'S-PDU Kennungsfolgen'";

CM_ SG_ 310 HAL_01_CRC "Für MLB:
'Berechnung siehe Lastenheft 'Kommunikationsabsicherung für FlexRay und CAN''

Ab MQB und MLBevo:
'Berechnung siehe Lastenheft 'End-to-End Kommunikationsabsicherung''

Endwerte siehe Begleitdokument 'S-PDU Kennungsfolgen'
";
CM_ SG_ 310 HAL_Charisma_FahrPr "MLBevo: Aktuelles Fahrprogramm des Charisma-Teilnehmers (siehe Systemlastenheft Drive Select)
MQB: Istwert der Kennlinie (siehe Systemlastenheft MQB FPA)";
CM_ SG_ 310 HAL_Charisma_Status "Rückmeldung an den Charisma-Master";
CM_ SG_ 310 HAL_EFP_FahrPr "Aktueller Ist-Zustand der HAL";
CM_ SG_ 310 HAL_Fahrerwunschwinkel_Soll "Zielwinkel (=Fahrerwunschwinkel) am Rad Hinterachslenkung in Grad";
CM_ SG_ 310 HAL_max_Gradient "maximaler Zustellgradient für die Stabilisierungsfunktion mit HAL durch ESP";
CM_ SG_ 310 HAL_QBit_Radwinkel "Wenn Bit gesetzt, dann entspreicht das Signal nicht mehr ASIL-D. (z.B. Ausfall der redundanten Sensorik)";
CM_ SG_ 310 HAL_Radwinkel "Zusätzlich durch die HAL gestellter Radwinkeloffset an der Hinterachse in Grad";
CM_ SG_ 310 HAL_Status "Status der Hinterachslenkung
0: normaler Betrieb 
1: HAL verriegelt (z.B. harter Fehler, nicht kalibriert)
2: Rücknahme der Leistung, Funktion eingeschränkt/Derating aktiv 
3: HAL deaktiviert";
CM_ SG_ 310 HAL_Status_2 "Zustand der Hinterachlenkung in der Smart application";
CM_ SG_ 310 HAL_VZ_Fahrerwunschwinkel_Soll "Soll-Lenkrichtung der HAL";
CM_ SG_ 310 HAL_VZ_Radwinkel "Lenkrichtung der HAL";
CM_ SG_ 310 HAL_Warnungen "Warnmeldungsanforderung von der Hinterachslenkung an das Kombiinstrumnent";
CM_ SG_ 310 HAL_Winkelbegrenzung "Signal liefert die Info über eine aktive Winkelbegrenzung in der HAL aufgrund Bauteilschutz";

CM_ SG_ 676 HAL_02_BZ "4bit Botschaftszaehler; wird in jeder Sendebotschaft inkrementiert";
CM_ SG_ 676 HAL_02_CRC "Für MLB:
'Berechnung siehe Lastenheft 'Kommunikationsabsicherung für FlexRay und CAN''

Ab MQB und MLBevo:
'Berechnung siehe Lastenheft 'End-to-End Kommunikationsabsicherung''

Endwerte siehe Begleitdokument 'S-PDU Kennungsfolgen'";
CM_ SG_ 676 HAL_ARA_Status "Anforderung vom Anhängerrangierassistent. 
16 Statuswerte";
CM_ SG_ 676 HAL_IL_Status "Status des Funktionsanteils Integrallenkung in der HAL";
CM_ SG_ 676 HAL_PLA_Status "16 Statuswerte (siehe LH PLA/HAL)";
CM_ SG_ 676 HAL_PWR_Abbruch "Dieses Signal gibt das Abbruchkriterium für PLA und ARA an.
";
CM_ SG_ 676 HAL_PWR_Fehler "Gibt den Fehler aus wenn eine Radwinkelanforderung nicht ausgeführt werden konnte.
";
CM_ SG_ 676 HAL_Temperatur "Leiterplattentemperatur der HAL";

CM_ SG_ 1410 HD_Bewegung_auf "Bewegung HD (öffnen)";
CM_ SG_ 1410 HD_Bewegung_zu "Bewegung HD (schließen)";
CM_ SG_ 1410 HD_Endstellung_oben "obere Endstellung HD
";
CM_ SG_ 1410 HD_Endstellung_unten "untere Endstellung HD";
CM_ SG_ 1410 HD_Innentaster_betaetigt "Betätigung Innentaster HD
";
CM_ SG_ 1410 HD_Position "HD Position von 0 bis 100 %";
CM_ SG_ 1410 HD_Rueckmeld_prog "Programmierung Endstellung HD 
";
CM_ SG_ 1410 HD_Taster_defekt "Anzeige ob Heckdeckeltaster defekt ist";
CM_ SG_ 1410 HD_UeKB_erkannt "Erkennung Einklemmschutz";
CM_ SG_ 1410 HD_Verr_Taster_betaetigt_inv "Inverses Bit (Fusi-Anforderung) Betätigung des Verriegelungstaster für Heckdeckel";
CM_ SG_ 1410 HD_Verriegelungstaster_betaetigt "Betätigung des Verriegelungstaster für Heckdeckel";
CM_ SG_ 1410 HD_ZZH_Schalter_S3 "Teilt den Zustand des Statusschalters in einer unidirektionalen ZZH mit.";

CM_ SG_ 1416 BCM1_TCH_HLR_Anf "Kundenanforderung des Thermocupholders zum Heizen-/Kühlen";
CM_ SG_ 1416 FSH_LED "LED Ansteuerung Frontscheibenheizung";
CM_ SG_ 1416 HLR_SIH_Freigabe_Fond "Freigabe des EM für Sitzheizungen hinten";
CM_ SG_ 1416 HSH_LED "LED Ansteuerung Heckscheibenheizung";
CM_ SG_ 1416 KRH_Stufe_LED_li "Statusmeldung Kopfraumheizung links";
CM_ SG_ 1416 KRH_Stufe_LED_re "Statusmeldung Kopfraumheizung rechts";
CM_ SG_ 1416 SIH_Stufe_LED_HL "Statusmeldung Sitzheizung hinten links";
CM_ SG_ 1416 SIH_Stufe_LED_HR "Statusmeldung Sitzheizung hinten rechts";
CM_ SG_ 1416 SIH_Stufe_LED_li "Statusmeldung Sitzheizung links";
CM_ SG_ 1416 SIH_Stufe_LED_re "Statusmeldung Sitzheizung rechts";
CM_ SG_ 1416 SIL_Stufe_LED_HL "Statusmeldung Sitzlüftung hinten links";
CM_ SG_ 1416 SIL_Stufe_LED_HR "Statusmeldung Sitzlüftung hinten rechts";
CM_ SG_ 1416 SIL_Stufe_LED_li "Statusmeldung Sitzlüftung links";
CM_ SG_ 1416 SIL_Stufe_LED_re "Statusmeldung Sitzlüftung rechts";

CM_ SG_ 1016 HLR_FlHz_Freigabe_HL "Freigabe des NVEM für die Flächenheizung hinten links";
CM_ SG_ 1016 HLR_FlHz_Freigabe_HR "Freigabe des NVEM für die Flächenheizung hinten rechts";
CM_ SG_ 1016 HLR_FlHz_Freigabe_Ruhesitz "Freigabe des NVEM für die Flächenheizung des Ruhesitzes";
CM_ SG_ 1016 HLR_FlHz_Freigabe_VL "Freigabe des NVEM für die Flächenheizung vorne links";
CM_ SG_ 1016 HLR_FlHz_Freigabe_VR "Freigabe des NVEM für die Flächenheizung vorne rechts";
CM_ SG_ 1016 HLR_FSH_Freigabe "Freigabe des EEM für die Frontscheibenheizung";
CM_ SG_ 1016 HLR_HSH_Freigabe "Freigabe des EEM für die Heckscheibenheizung";
CM_ SG_ 1016 HLR_KRH_Freigabe_VL "Freigabe des EEM für die Kopfraumheizung vorne links";
CM_ SG_ 1016 HLR_KRH_Freigabe_VR "Freigabe des EEM für die Kopfraumheizung vorne rechts";
CM_ SG_ 1016 HLR_LRH_Freigabe "Freigabe für die Lenkradheizung";
CM_ SG_ 1016 HLR_PTC_Freigabe "Freigabe des elektrischen Energiemanagements für das gestufte/geregelte PTC";
CM_ SG_ 1016 HLR_PTC_linear_Freigabe "Freigabe des EEM für den linearen PTC-Zuheizer";
CM_ SG_ 1016 HLR_SIH_Freigabe_Fond "Freigabe des EM für Sitzheizungen hinten";
CM_ SG_ 1016 HLR_SIH_Freigabe_HL "Freigabe des EEM für die Sitzheizung hinten links";
CM_ SG_ 1016 HLR_SIH_Freigabe_HR "Freigabe des EEM für die Sitzheizung hinten rechts";
CM_ SG_ 1016 HLR_SIH_Freigabe_VL "Freigabe des EEM für die Sitzheizung vorne links";
CM_ SG_ 1016 HLR_SIH_Freigabe_VR "Freigabe des EEM für die Sitzheizung vorne rechts";
CM_ SG_ 1016 HLR_SIL_Freigabe_HL "Freigabe des EEM für die Sitzbelüftung hinten links";
CM_ SG_ 1016 HLR_SIL_Freigabe_HR "Freigabe des EEM für die Sitzlüftung hinten rechts";
CM_ SG_ 1016 HLR_SIL_Freigabe_VL "Freigabe des EEM für die Sitzlüftung Vorne Links";
CM_ SG_ 1016 HLR_SIL_Freigabe_VR "Freigabe des EEM für die Sitzlüftung vorne Rechts";
CM_ SG_ 1016 HLR_Sp_Heizung_Freigabe_BT "Freigabe der Außenspiegelheizung Beifahrerseite";
CM_ SG_ 1016 HLR_Sp_Heizung_Freigabe_FT "Freigabe des EEM für die Außenspiegelheizung rechtsFreigabe der Außenspiegelheizung Fahrerseite";
CM_ SG_ 1016 HLR_TCH_Freigabe "Freigabe des NVEM für den Thermocupholder";

CM_ SG_ 1283 HV_Bordnetz_aktiv "Signalisiert ein aktives Hochvoltbordnetz. Für die Belastbarkeit des HV-Netzes müssen Strom- bzw. Leistungsgrenzen eingehalten werden";
CM_ SG_ 1283 HV_Bordnetz_Fehler "Status ob im  HV-Netz ein Fehler detektiert wurde.";
CM_ SG_ 1283 HVK_01_CRC "Für MLB:
'Berechnung siehe Lastenheft 'Kommunikationsabsicherung für FlexRay und CAN''

Ab MQB und MLBevo:
'Berechnung siehe Lastenheft 'End-to-End Kommunikationsabsicherung''

Endwerte siehe Begleitdokument 'S-PDU Kennungsfolgen'";
CM_ SG_ 1283 HVK_AIAD_Sollmodus_2 "Freigabe für die HV-Netz Teilnahme";
CM_ SG_ 1283 HVK_AktiveEntladung_Anf "Anforderung zum aktiven Entladen des HV-Netzes, während der Abschaltung des HV-Netz.";
CM_ SG_ 1283 HVK_BMS_Sollmodus "Angeforderter Sollmodus der HV-Batterie:
0 : HV_Off                                
1 : HV_On (HS geschlossen)                
2 : nicht belegbar                        
3 : AC-Laden_erw (HS +AC_2-Schütze geschlossen)                         
4 : AC-";
CM_ SG_ 1283 HVK_DCDC_EKK_Sollmodus "Bedarfsgerechtes Aktivieren des 400V-DCDC-Wandlers bei Anforderung durch TME";
CM_ SG_ 1283 HVK_DCDC_Sollmodus "angeforderte Soll-Betriebsart des DC/DC-Wandlers: 
0: Standby; Kommunikation aktiv
1: Zwischenkreis des HV-Netzes wird vorgeladen; HV-Netz wird aktiviert und darf nicht  
    belastet werden.
2: Tiefsetzen (HV --> BN 14,4V)
    Sollwertvorgabe projek";
CM_ SG_ 1283 HVK_EKK_Sollmodus "Sollmodus elektrischer Klimakompressor";
CM_ SG_ 1283 HVK_Gesamtst_Spgfreiheit "Status des HV-Systems";
CM_ SG_ 1283 HVK_HV_Netz_Warnungen "Anforderung Warnung/Fehler HV-System im Kombi
0: Keine Warnung/Init
1:Anforderung_Anzeige_Warnung_HV-Netz (gelbes Symbol)
2:Anforderung_Anzeige_Fehler_HV-Netz (rotes Symbol)
3:Anforderung_Anzeige_Warnung_Kein_Wiederstart_möglich";
CM_ SG_ 1283 HVK_HVLM_Sollmodus "Angeforderter Sollmodus des Lademanagers.";
CM_ SG_ 1283 HVK_HVPTC_Sollmodus "Sollmodus HV-PTC
0 : keine Freigabe
1 : Freigabe
2 : Freigabe_ausgesetzt
3 : nicht belegbar
4 : nicht belegbar
5 : nicht belegbar
6 : nicht belegbar
7 : Init   (CAN-Initialisierung)   

Info: 'nicht belegbar' d.h. Sollmodus nicht relevant für HV";
CM_ SG_ 1283 HVK_Iso_Fehlerstatus "Das Signal gibt an, ob ein Isolationsfehler an der Ladesäule vorliegt  (BMS_IsoFehler = IsoFehler_Schwelle_2) und dient als Trigger einer Warnmeldung im Kombi-Instrument.";
CM_ SG_ 1283 HVK_Iso_Messung_Start "Anforderung an die isolationswiderstandsüberwachenden HV-Komponenten zur Durchführung der Isolations-Widerstandsmessung.";
CM_ SG_ 1283 HVK_Istmodus_Anf "HVK-Anforderung an alle HV-Komponenten deren Istmodus im schnellen Zyklus (Inhibitzeit) zu senden.";
CM_ SG_ 1283 HVK_MO_EmSollzustand "Anforderung vom HVK Sollzustand der Elm_State
0 = HvOff              
1 = HvStbyReq          
2 = HvStbyWait         
3 = HvBattOnReq        
4 = HvBattOnWait       
10 = HvOnIdle          
18 = HvOnDrvReq        
19 = HvOnDrvWait       
20 = HvO";
CM_ SG_ 1283 HVK_TN1_Sollmodus "Angeforderter Sollmodus der Steuereinheit für das Schütze des Teilnetz1 'Ladepfad':
0 : HV_Off                                
1 : HV_On (Schütz geschlossen)                
2 : reserviert
3 : Init   (CAN-Initialisierung)";
BA_DEF_REL_ BU_SG_REL_  "GenSigTimeoutTime" INT 0 65535;
BA_DEF_ BO_  "DiagRequest" ENUM "No", "Yes";
BA_DEF_ BO_  "DiagResponse" ENUM "No", "Yes";
BA_DEF_ BO_  "DiagState" ENUM "No", "Yes";
BA_DEF_ BO_  "GenMsgChkConstant" HEX 0 4095;
BA_DEF_ BO_  "GenMsgCycleTime" INT 0 65535;
BA_DEF_ BO_  "GenMsgCycleTimeFast" INT 0 65535;
BA_DEF_ BO_  "GenMsgDelayTime" INT 0 100000;
BA_DEF_ BO_  "GenMsgILSupport" ENUM "No", "Yes";
BA_DEF_ BO_  "GenMsgNrOfRepetition" INT 0 100;
BA_DEF_ BO_  "GenMsgPDUConstants" STRING;
BA_DEF_ BO_  "GenMsgSendType" ENUM "Cyclic", "not_used", "not_used", "not_used", "not_used", "not_used", "not_used", "IfActive", "NoMsgSendType";
BA_DEF_ BO_  "GenMsgStartDelayTime" INT 0 100000;
BA_DEF_ BO_  "NmMessage" ENUM "No", "Yes";
BA_DEF_ BO_  "NmhMessage" ENUM "No", "Yes";
BA_DEF_ BO_  "MsgType" ENUM "Application", "NM ", "NMH", "TP2.0", "ISO-TP ", "BAP", "EID", "KS", "XCP_PRE_CONFIGURED", "XCP_RUNTIME_CONFIGURED";
BA_DEF_ BO_  "VAGTP20_API" HEX 0 255;
BA_DEF_ BO_  "VAGTP20_DynConnection" ENUM "No", "Yes";
BA_DEF_ BO_  "VAGTP20_DynSetup" ENUM "No", "Yes";
BA_DEF_ BO_  "VAGTP20_StatConnection" ENUM "No", "Yes";
BA_DEF_ SG_  "GenSigActiveRepetitions" INT -2147483648 2147483647;
BA_DEF_ SG_  "GenSigInactiveValue" INT -2147483648 2147483647;
BA_DEF_ SG_  "GenSigSendType" ENUM "Cyclic", "OnWrite", "OnWriteWithRepetition", "OnChange", "OnChangeWithRepetition", "IfActive", "IfActiveWithRepetition", "NoSigSendType", "OnChangeAndIfActive", "OnChangeAndIfActiveWithRepetition";
BA_DEF_ SG_  "GenSigStartValue" INT -2147483648 2147483647;
BA_DEF_ SG_  "NWM-WakeupAllowed" ENUM "No", "Yes";
BA_DEF_ SG_  "GenSigFuncType" ENUM "NoFunction", "MsgCounter", "CRC-8", "XOR", "XOR-2", "DatedBit", "SW-Kl15", "CHK", "Constant", "Protocol", "CRC-8-SAE_J1850", "CRC-32", "DataLength", "DataID", "MsgCounter16", "SOK-Signatur", "Cluster";
BA_DEF_ SG_  "GenSigSwitchedByIgnition" ENUM "No", "Yes";
BA_DEF_ SG_  "Fehlerwert" HEX 0 2147483647;
BA_DEF_ SG_  "GenSigMissingSourceValue" HEX 0 2147483647;
BA_DEF_DEF_REL_  "GenSigTimeoutTime" 0;
BA_DEF_DEF_  "DiagRequest" "No";
BA_DEF_DEF_  "DiagResponse" "No";
BA_DEF_DEF_  "DiagState" "No";
BA_DEF_DEF_  "GenMsgChkConstant" 0;
BA_DEF_DEF_  "GenMsgCycleTime" 0;
BA_DEF_DEF_  "GenMsgCycleTimeFast" 0;
BA_DEF_DEF_  "GenMsgDelayTime" 0;
BA_DEF_DEF_  "GenMsgILSupport" "No";
BA_DEF_DEF_  "GenMsgNrOfRepetition" 0;
BA_DEF_DEF_  "GenMsgPDUConstants" "";
BA_DEF_DEF_  "GenMsgSendType" "NoMsgSendType";
BA_DEF_DEF_  "GenMsgStartDelayTime" 0;
BA_DEF_DEF_  "NmMessage" "No";
BA_DEF_DEF_  "NmhMessage" "No";
BA_DEF_DEF_  "MsgType" "Application";
BA_DEF_DEF_  "VAGTP20_API" 0;
BA_DEF_DEF_  "VAGTP20_DynConnection" "No";
BA_DEF_DEF_  "VAGTP20_DynSetup" "No";
BA_DEF_DEF_  "VAGTP20_StatConnection" "No";
BA_DEF_DEF_  "GenSigActiveRepetitions" 0;
BA_DEF_DEF_  "GenSigInactiveValue" 0;
BA_DEF_DEF_  "GenSigSendType" "NoSigSendType";
BA_DEF_DEF_  "GenSigStartValue" 0;
BA_DEF_DEF_  "NWM-WakeupAllowed" "No";
BA_DEF_DEF_  "GenSigFuncType" "NoFunction";
BA_DEF_DEF_  "GenSigSwitchedByIgnition" "Yes";
BA_DEF_DEF_  "Fehlerwert" 0;
BA_DEF_DEF_  "GenSigMissingSourceValue" 0;
BA_ "GenMsgChkConstant" BO_ 259 2;
BA_ "GenMsgCycleTime" BO_ 259 20;
BA_ "GenMsgILSupport" BO_ 259 1;
BA_ "GenMsgPDUConstants" BO_ 259 "0x02,0x02,0x02,0x02,0x02,0x02,0x02,0x02,0x02,0x02,0x02,0x02,0x02,0x02,0x02,0x02";
BA_ "GenMsgSendType" BO_ 259 0;
BA_ "GenMsgChkConstant" BO_ 914 145;
BA_ "GenMsgCycleTime" BO_ 914 80;
BA_ "GenMsgILSupport" BO_ 914 1;
BA_ "GenMsgPDUConstants" BO_ 914 "0x91,0x91,0x91,0x91,0x91,0x91,0x91,0x91,0x91,0x91,0x91,0x91,0x91,0x91,0x91,0x91";
BA_ "GenMsgSendType" BO_ 914 0;
BA_ "GenMsgChkConstant" BO_ 278 172;
BA_ "GenMsgCycleTime" BO_ 278 20;
BA_ "GenMsgILSupport" BO_ 278 1;
BA_ "GenMsgPDUConstants" BO_ 278 "0xac,0xac,0xac,0xac,0xac,0xac,0xac,0xac,0xac,0xac,0xac,0xac,0xac,0xac,0xac,0xac";
BA_ "GenMsgSendType" BO_ 278 0;
BA_ "GenMsgCycleTime" BO_ 418 200;
BA_ "GenMsgDelayTime" BO_ 418 20;
BA_ "GenMsgILSupport" BO_ 418 1;
BA_ "GenMsgPDUConstants" BO_ 418 "0xcb,0x47,0xd7,0xd2,0x56,0x3e,0x20,0xea,0x6e,0x6d,0x8c,0x1b,0xdf,0x49,0xaa,0xab";
BA_ "GenMsgSendType" BO_ 418 0;
BA_ "GenMsgCycleTime" BO_ 253 20;
BA_ "GenMsgILSupport" BO_ 253 1;
BA_ "GenMsgPDUConstants" BO_ 253 "0xb4,0xef,0xf8,0x49,0x1e,0xe5,0xc2,0xc0,0x97,0x19,0x3c,0xc9,0xf1,0x98,0xd6,0x61";
BA_ "GenMsgSendType" BO_ 253 0;
BA_ "GenMsgCycleTime" BO_ 1470 320;
BA_ "GenMsgILSupport" BO_ 1470 1;
BA_ "GenMsgPDUConstants" BO_ 1470 "0xc9,0x21,0x6f,0x63,0xd2,0x42,0x6a,0x77,0x4a,0x3d,0xb0,0x62,0x9f,0x38,0xcd,0x5c";
BA_ "GenMsgSendType" BO_ 1470 0;
BA_ "GenMsgCycleTime" BO_ 508 100;
BA_ "GenMsgILSupport" BO_ 508 1;
BA_ "GenMsgPDUConstants" BO_ 508 "0x01,0x10,0x05,0xde,0xe0,0xdc,0x34,0xc4,0x8a,0xb1,0x6d,0x7b,0x62,0xef,0x1f,0x95";
BA_ "GenMsgSendType" BO_ 508 0;
BA_ "GenMsgCycleTime" BO_ 427 200;
BA_ "GenMsgDelayTime" BO_ 427 20;
BA_ "GenMsgILSupport" BO_ 427 1;
BA_ "GenMsgPDUConstants" BO_ 427 "0x13,0x21,0x9b,0x6a,0x9a,0x62,0xd4,0x65,0x18,0xf1,0xab,0x16,0x32,0x89,0xe7,0x26";
BA_ "GenMsgSendType" BO_ 427 0;
BA_ "GenMsgChkConstant" BO_ 264 9;
BA_ "GenMsgCycleTime" BO_ 264 20;
BA_ "GenMsgILSupport" BO_ 264 1;
BA_ "GenMsgPDUConstants" BO_ 264 "0x09,0x09,0x09,0x09,0x09,0x09,0x09,0x09,0x09,0x09,0x09,0x09,0x09,0x09,0x09,0x09";
BA_ "GenMsgSendType" BO_ 264 0;
BA_ "GenMsgCycleTime" BO_ 429 1000;
BA_ "GenMsgDelayTime" BO_ 429 40;
BA_ "GenMsgILSupport" BO_ 429 1;
BA_ "GenMsgPDUConstants" BO_ 429 "0x40,0x7a,0x23,0x13,0x03,0xf4,0xf8,0xe5,0x97,0xc9,0xd6,0x07,0x47,0x21,0x66,0xdd";
BA_ "GenMsgSendType" BO_ 429 0;
BA_ "GenMsgCycleTime" BO_ 852 80;
BA_ "GenMsgILSupport" BO_ 852 1;
BA_ "GenMsgSendType" BO_ 852 0;
BA_ "GenMsgCycleTime" BO_ 2527679660 320;
BA_ "GenMsgILSupport" BO_ 2527679660 1;
BA_ "GenMsgSendType" BO_ 2527679660 0;
BA_ "GenMsgCycleTime" BO_ 853 80;
BA_ "GenMsgILSupport" BO_ 853 1;
BA_ "GenMsgSendType" BO_ 853 0;
BA_ "GenMsgCycleTime" BO_ 854 80;
BA_ "GenMsgILSupport" BO_ 854 1;
BA_ "GenMsgSendType" BO_ 854 0;
BA_ "GenMsgCycleTime" BO_ 1605 1000;
BA_ "GenMsgDelayTime" BO_ 1605 20;
BA_ "GenMsgILSupport" BO_ 1605 1;
BA_ "GenMsgSendType" BO_ 1605 0;
BA_ "GenMsgCycleTime" BO_ 2589283684 960;
BA_ "GenMsgDelayTime" BO_ 2589283684 320;
BA_ "GenMsgILSupport" BO_ 2589283684 1;
BA_ "GenMsgSendType" BO_ 2589283684 0;
BA_ "GenMsgStartDelayTime" BO_ 2589283684 320;
BA_ "GenMsgILSupport" BO_ 2549875470 1;
BA_ "MsgType" BO_ 2549875470 4;
BA_ "GenMsgILSupport" BO_ 2550006542 1;
BA_ "MsgType" BO_ 2550006542 4;
BA_ "GenMsgCycleTime" BO_ 1523 200;
BA_ "GenMsgILSupport" BO_ 1523 1;
BA_ "GenMsgSendType" BO_ 1523 0;
BA_ "GenMsgCycleTime" BO_ 173 100;
BA_ "GenMsgDelayTime" BO_ 173 10;
BA_ "GenMsgILSupport" BO_ 173 1;
BA_ "GenMsgPDUConstants" BO_ 173 "0x3f,0x69,0x39,0xdc,0x94,0xf9,0x14,0x64,0xd8,0x6a,0x34,0xce,0xa2,0x55,0xb5,0x2c";
BA_ "GenMsgSendType" BO_ 173 0;
BA_ "GenMsgCycleTime" BO_ 177 500;
BA_ "GenMsgDelayTime" BO_ 177 10;
BA_ "GenMsgILSupport" BO_ 177 1;
BA_ "GenMsgPDUConstants" BO_ 177 "0xe1,0x9e,0xc2,0xe9,0x48,0x98,0xf5,0xb6,0x47,0x83,0x26,0x45,0x9a,0x10,0x7b,0x1c";
BA_ "GenMsgSendType" BO_ 177 0;
BA_ "GenMsgChkConstant" BO_ 310 55;
BA_ "GenMsgCycleTime" BO_ 310 10;
BA_ "GenMsgILSupport" BO_ 310 1;
BA_ "GenMsgPDUConstants" BO_ 310 "0x37,0x37,0x37,0x37,0x37,0x37,0x37,0x37,0x37,0x37,0x37,0x37,0x37,0x37,0x37,0x37";
BA_ "GenMsgSendType" BO_ 310 0;
BA_ "GenMsgCycleTime" BO_ 676 40;
BA_ "GenMsgILSupport" BO_ 676 1;
BA_ "GenMsgPDUConstants" BO_ 676 "0x42,0x54,0xd5,0x29,0xcc,0x16,0x4d,0xa8,0xd4,0xed,0x7c,0x21,0xdb,0x6b,0xe6,0x5a";
BA_ "GenMsgSendType" BO_ 676 0;
BA_ "GenMsgCycleTime" BO_ 1410 200;
BA_ "GenMsgDelayTime" BO_ 1410 20;
BA_ "GenMsgILSupport" BO_ 1410 1;
BA_ "GenMsgSendType" BO_ 1410 0;
BA_ "GenMsgCycleTime" BO_ 1416 500;
BA_ "GenMsgDelayTime" BO_ 1416 50;
BA_ "GenMsgILSupport" BO_ 1416 1;
BA_ "GenMsgSendType" BO_ 1416 0;
BA_ "GenMsgCycleTime" BO_ 1016 500;
BA_ "GenMsgDelayTime" BO_ 1016 50;
BA_ "GenMsgILSupport" BO_ 1016 1;
BA_ "GenMsgSendType" BO_ 1016 0;
BA_ "GenMsgStartDelayTime" BO_ 1016 70;
BA_ "GenMsgCycleTime" BO_ 1283 100;
BA_ "GenMsgDelayTime" BO_ 1283 10;
BA_ "GenMsgILSupport" BO_ 1283 1;
BA_ "GenMsgPDUConstants" BO_ 1283 "0xed,0xd6,0x96,0x63,0xa5,0x12,0xd5,0x9a,0x1e,0x0d,0x24,0xcd,0x8c,0xa6,0x2f,0x41";
BA_ "GenMsgSendType" BO_ 1283 0;
BA_ "GenMsgStartDelayTime" BO_ 1283 10;
BA_ "GenSigSendType" SG_ 259 ESP_03_BZ 0;
BA_ "GenSigFuncType" SG_ 259 ESP_03_BZ 1;
BA_ "GenSigSwitchedByIgnition" SG_ 259 ESP_03_BZ 0;
BA_ "GenSigSendType" SG_ 259 ESP_03_CRC 0;
BA_ "GenSigFuncType" SG_ 259 ESP_03_CRC 2;
BA_ "GenSigSwitchedByIgnition" SG_ 259 ESP_03_CRC 0;
BA_ "GenSigSendType" SG_ 259 ESP_HL_FR 0;
BA_ "GenSigSwitchedByIgnition" SG_ 259 ESP_HL_FR 0;
BA_ "GenSigSendType" SG_ 259 ESP_HL_Radgeschw 0;
BA_ "GenSigStartValue" SG_ 259 ESP_HL_Radgeschw 4094;
BA_ "GenSigSwitchedByIgnition" SG_ 259 ESP_HL_Radgeschw 0;
BA_ "Fehlerwert" SG_ 259 ESP_HL_Radgeschw 4095;
BA_ "GenSigSendType" SG_ 259 ESP_HR_FR 0;
BA_ "GenSigSwitchedByIgnition" SG_ 259 ESP_HR_FR 0;
BA_ "GenSigSendType" SG_ 259 ESP_HR_Radgeschw 0;
BA_ "GenSigStartValue" SG_ 259 ESP_HR_Radgeschw 4094;
BA_ "GenSigSwitchedByIgnition" SG_ 259 ESP_HR_Radgeschw 0;
BA_ "Fehlerwert" SG_ 259 ESP_HR_Radgeschw 4095;
BA_ "GenSigSendType" SG_ 259 ESP_VL_FR 0;
BA_ "GenSigSwitchedByIgnition" SG_ 259 ESP_VL_FR 0;
BA_ "GenSigSendType" SG_ 259 ESP_VL_Radgeschw 0;
BA_ "GenSigStartValue" SG_ 259 ESP_VL_Radgeschw 4094;
BA_ "GenSigSwitchedByIgnition" SG_ 259 ESP_VL_Radgeschw 0;
BA_ "Fehlerwert" SG_ 259 ESP_VL_Radgeschw 4095;
BA_ "GenSigSendType" SG_ 259 ESP_VR_FR 0;
BA_ "GenSigSwitchedByIgnition" SG_ 259 ESP_VR_FR 0;
BA_ "GenSigSendType" SG_ 259 ESP_VR_Radgeschw 0;
BA_ "GenSigStartValue" SG_ 259 ESP_VR_Radgeschw 4094;
BA_ "GenSigSwitchedByIgnition" SG_ 259 ESP_VR_Radgeschw 0;
BA_ "Fehlerwert" SG_ 259 ESP_VR_Radgeschw 4095;
BA_ "GenSigSendType" SG_ 914 ESC_cAQP_Trigger 0;
BA_ "GenSigSendType" SG_ 914 ESP_07_BZ 0;
BA_ "GenSigFuncType" SG_ 914 ESP_07_BZ 1;
BA_ "GenSigSwitchedByIgnition" SG_ 914 ESP_07_BZ 0;
BA_ "GenSigSendType" SG_ 914 ESP_07_CRC 0;
BA_ "GenSigFuncType" SG_ 914 ESP_07_CRC 2;
BA_ "GenSigSwitchedByIgnition" SG_ 914 ESP_07_CRC 0;
BA_ "GenSigSendType" SG_ 914 ESP_Allrad_Antrieb 0;
BA_ "GenSigFuncType" SG_ 914 ESP_Allrad_Antrieb 8;
BA_ "GenSigSwitchedByIgnition" SG_ 914 ESP_Allrad_Antrieb 0;
BA_ "GenSigSendType" SG_ 914 ESP_Codierung_ADS 0;
BA_ "GenSigFuncType" SG_ 914 ESP_Codierung_ADS 8;
BA_ "GenSigSwitchedByIgnition" SG_ 914 ESP_Codierung_ADS 0;
BA_ "GenSigSendType" SG_ 914 ESP_MKB_ausloesbar 0;
BA_ "GenSigSwitchedByIgnition" SG_ 914 ESP_MKB_ausloesbar 0;
BA_ "GenSigSendType" SG_ 914 ESP_nachtr_Stopp_Anf 0;
BA_ "GenSigSwitchedByIgnition" SG_ 914 ESP_nachtr_Stopp_Anf 0;
BA_ "GenSigSendType" SG_ 914 ESP_OBD_Status 0;
BA_ "GenSigSwitchedByIgnition" SG_ 914 ESP_OBD_Status 0;
BA_ "GenSigSendType" SG_ 914 ESP_Offroad_Modus 0;
BA_ "GenSigSwitchedByIgnition" SG_ 914 ESP_Offroad_Modus 0;
BA_ "GenSigSendType" SG_ 914 ESP_Qualifizierung_Antriebsart 0;
BA_ "GenSigFuncType" SG_ 914 ESP_Qualifizierung_Antriebsart 8;
BA_ "GenSigSwitchedByIgnition" SG_ 914 ESP_Qualifizierung_Antriebsart 0;
BA_ "GenSigSendType" SG_ 914 ESP_Rollenmodus_Deaktivieren 0;
BA_ "GenSigSwitchedByIgnition" SG_ 914 ESP_Rollenmodus_Deaktivieren 0;
BA_ "GenSigSendType" SG_ 914 ESP_RTA_HL 0;
BA_ "GenSigStartValue" SG_ 914 ESP_RTA_HL 254;
BA_ "GenSigSwitchedByIgnition" SG_ 914 ESP_RTA_HL 0;
BA_ "Fehlerwert" SG_ 914 ESP_RTA_HL 255;
BA_ "GenSigSendType" SG_ 914 ESP_RTA_HR 0;
BA_ "GenSigStartValue" SG_ 914 ESP_RTA_HR 254;
BA_ "GenSigSwitchedByIgnition" SG_ 914 ESP_RTA_HR 0;
BA_ "Fehlerwert" SG_ 914 ESP_RTA_HR 255;
BA_ "GenSigSendType" SG_ 914 ESP_RTA_VR 0;
BA_ "GenSigStartValue" SG_ 914 ESP_RTA_VR 254;
BA_ "GenSigSwitchedByIgnition" SG_ 914 ESP_RTA_VR 0;
BA_ "Fehlerwert" SG_ 914 ESP_RTA_VR 255;
BA_ "GenSigSendType" SG_ 914 ESP_Stat_FallBack_eBKV 0;
BA_ "GenSigSwitchedByIgnition" SG_ 914 ESP_Stat_FallBack_eBKV 0;
BA_ "GenSigSendType" SG_ 914 OBD_Fehler_Radsensor_HL 0;
BA_ "GenSigSwitchedByIgnition" SG_ 914 OBD_Fehler_Radsensor_HL 0;
BA_ "GenSigSendType" SG_ 914 OBD_Fehler_Radsensor_HR 0;
BA_ "GenSigSwitchedByIgnition" SG_ 914 OBD_Fehler_Radsensor_HR 0;
BA_ "GenSigSendType" SG_ 914 OBD_Fehler_Radsensor_VL 0;
BA_ "GenSigSwitchedByIgnition" SG_ 914 OBD_Fehler_Radsensor_VL 0;
BA_ "GenSigSendType" SG_ 914 OBD_Fehler_Radsensor_VR 0;
BA_ "GenSigSwitchedByIgnition" SG_ 914 OBD_Fehler_Radsensor_VR 0;
BA_ "GenSigSendType" SG_ 278 ESP_10_BZ 0;
BA_ "GenSigFuncType" SG_ 278 ESP_10_BZ 1;
BA_ "GenSigSwitchedByIgnition" SG_ 278 ESP_10_BZ 0;
BA_ "GenSigSendType" SG_ 278 ESP_10_CRC 0;
BA_ "GenSigFuncType" SG_ 278 ESP_10_CRC 2;
BA_ "GenSigSwitchedByIgnition" SG_ 278 ESP_10_CRC 0;
BA_ "GenSigSendType" SG_ 278 ESP_HL_Fahrtrichtung 0;
BA_ "GenSigStartValue" SG_ 278 ESP_HL_Fahrtrichtung 2;
BA_ "GenSigSwitchedByIgnition" SG_ 278 ESP_HL_Fahrtrichtung 0;
BA_ "GenSigSendType" SG_ 278 ESP_HR_Fahrtrichtung 0;
BA_ "GenSigStartValue" SG_ 278 ESP_HR_Fahrtrichtung 2;
BA_ "GenSigSwitchedByIgnition" SG_ 278 ESP_HR_Fahrtrichtung 0;
BA_ "GenSigSendType" SG_ 278 ESP_QBit_Wegimpuls_HL 0;
BA_ "GenSigStartValue" SG_ 278 ESP_QBit_Wegimpuls_HL 1;
BA_ "GenSigSwitchedByIgnition" SG_ 278 ESP_QBit_Wegimpuls_HL 0;
BA_ "GenSigSendType" SG_ 278 ESP_QBit_Wegimpuls_HR 0;
BA_ "GenSigStartValue" SG_ 278 ESP_QBit_Wegimpuls_HR 1;
BA_ "GenSigSwitchedByIgnition" SG_ 278 ESP_QBit_Wegimpuls_HR 0;
BA_ "GenSigSendType" SG_ 278 ESP_QBit_Wegimpuls_VL 0;
BA_ "GenSigStartValue" SG_ 278 ESP_QBit_Wegimpuls_VL 1;
BA_ "GenSigSwitchedByIgnition" SG_ 278 ESP_QBit_Wegimpuls_VL 0;
BA_ "GenSigSendType" SG_ 278 ESP_QBit_Wegimpuls_VR 0;
BA_ "GenSigStartValue" SG_ 278 ESP_QBit_Wegimpuls_VR 1;
BA_ "GenSigSwitchedByIgnition" SG_ 278 ESP_QBit_Wegimpuls_VR 0;
BA_ "GenSigSendType" SG_ 278 ESP_VL_Fahrtrichtung 0;
BA_ "GenSigStartValue" SG_ 278 ESP_VL_Fahrtrichtung 2;
BA_ "GenSigSwitchedByIgnition" SG_ 278 ESP_VL_Fahrtrichtung 0;
BA_ "GenSigSendType" SG_ 278 ESP_VR_Fahrtrichtung 0;
BA_ "GenSigStartValue" SG_ 278 ESP_VR_Fahrtrichtung 2;
BA_ "GenSigSwitchedByIgnition" SG_ 278 ESP_VR_Fahrtrichtung 0;
BA_ "GenSigSendType" SG_ 278 ESP_Wegimpuls_HL 0;
BA_ "GenSigStartValue" SG_ 278 ESP_Wegimpuls_HL 1021;
BA_ "GenSigSwitchedByIgnition" SG_ 278 ESP_Wegimpuls_HL 0;
BA_ "Fehlerwert" SG_ 278 ESP_Wegimpuls_HL 1023;
BA_ "GenSigSendType" SG_ 278 ESP_Wegimpuls_HR 0;
BA_ "GenSigStartValue" SG_ 278 ESP_Wegimpuls_HR 1021;
BA_ "GenSigSwitchedByIgnition" SG_ 278 ESP_Wegimpuls_HR 0;
BA_ "Fehlerwert" SG_ 278 ESP_Wegimpuls_HR 1023;
BA_ "GenSigSendType" SG_ 278 ESP_Wegimpuls_VL 0;
BA_ "GenSigStartValue" SG_ 278 ESP_Wegimpuls_VL 1021;
BA_ "GenSigSwitchedByIgnition" SG_ 278 ESP_Wegimpuls_VL 0;
BA_ "Fehlerwert" SG_ 278 ESP_Wegimpuls_VL 1023;
BA_ "GenSigSendType" SG_ 278 ESP_Wegimpuls_VR 0;
BA_ "GenSigStartValue" SG_ 278 ESP_Wegimpuls_VR 1021;
BA_ "GenSigSwitchedByIgnition" SG_ 278 ESP_Wegimpuls_VR 0;
BA_ "Fehlerwert" SG_ 278 ESP_Wegimpuls_VR 1023;
BA_ "GenSigSendType" SG_ 418 ESP_15_BZ 0;
BA_ "GenSigFuncType" SG_ 418 ESP_15_BZ 1;
BA_ "GenSigSwitchedByIgnition" SG_ 418 ESP_15_BZ 0;
BA_ "GenSigSendType" SG_ 418 ESP_15_CRC 0;
BA_ "GenSigFuncType" SG_ 418 ESP_15_CRC 2;
BA_ "GenSigSwitchedByIgnition" SG_ 418 ESP_15_CRC 0;
BA_ "GenSigSendType" SG_ 418 ESP_Haltemoment 0;
BA_ "GenSigStartValue" SG_ 418 ESP_Haltemoment 1022;
BA_ "GenSigSwitchedByIgnition" SG_ 418 ESP_Haltemoment 0;
BA_ "Fehlerwert" SG_ 418 ESP_Haltemoment 1023;
BA_ "GenSigSendType" SG_ 418 ESP_Index_Haltemoment 0;
BA_ "GenSigSwitchedByIgnition" SG_ 418 ESP_Index_Haltemoment 0;
BA_ "GenSigSendType" SG_ 418 HMS_aktives_System 3;
BA_ "GenSigSwitchedByIgnition" SG_ 418 HMS_aktives_System 0;
BA_ "GenSigSendType" SG_ 418 HMS_Anforderung_GE 0;
BA_ "GenSigSwitchedByIgnition" SG_ 418 HMS_Anforderung_GE 0;
BA_ "GenSigSendType" SG_ 418 HMS_Fehlerstatus 3;
BA_ "GenSigSwitchedByIgnition" SG_ 418 HMS_Fehlerstatus 0;
BA_ "GenSigSendType" SG_ 418 HMS_halten_nicht_verfuegbar 0;
BA_ "GenSigSwitchedByIgnition" SG_ 418 HMS_halten_nicht_verfuegbar 0;
BA_ "GenSigSendType" SG_ 418 HMS_Konsistenz_ACC 0;
BA_ "GenSigSwitchedByIgnition" SG_ 418 HMS_Konsistenz_ACC 0;
BA_ "GenSigSendType" SG_ 418 HMS_Konsistenz_GE 0;
BA_ "GenSigSwitchedByIgnition" SG_ 418 HMS_Konsistenz_GE 0;
BA_ "GenSigSendType" SG_ 418 HMS_Konsistenz_HVLM 3;
BA_ "GenSigSwitchedByIgnition" SG_ 418 HMS_Konsistenz_HVLM 0;
BA_ "GenSigSendType" SG_ 418 HMS_Konsistenz_IPA 3;
BA_ "GenSigSwitchedByIgnition" SG_ 418 HMS_Konsistenz_IPA 0;
BA_ "GenSigSendType" SG_ 418 HMS_Konsistenz_MO 0;
BA_ "GenSigSwitchedByIgnition" SG_ 418 HMS_Konsistenz_MO 0;
BA_ "GenSigSendType" SG_ 418 HMS_Konsistenz_STA 0;
BA_ "GenSigSwitchedByIgnition" SG_ 418 HMS_Konsistenz_STA 0;
BA_ "GenSigSendType" SG_ 418 HMS_Notstopp_Status 0;
BA_ "GenSigSwitchedByIgnition" SG_ 418 HMS_Notstopp_Status 0;
BA_ "GenSigSendType" SG_ 418 HMS_P_beibehalten_GE 0;
BA_ "GenSigStartValue" SG_ 418 HMS_P_beibehalten_GE 2;
BA_ "GenSigSwitchedByIgnition" SG_ 418 HMS_P_beibehalten_GE 0;
BA_ "Fehlerwert" SG_ 418 HMS_P_beibehalten_GE 3;
BA_ "GenSigSendType" SG_ 418 HMS_parken_nicht_verfuegbar 0;
BA_ "GenSigSwitchedByIgnition" SG_ 418 HMS_parken_nicht_verfuegbar 0;
BA_ "GenSigSendType" SG_ 418 HMS_Stillstand 3;
BA_ "GenSigStartValue" SG_ 418 HMS_Stillstand 6;
BA_ "GenSigSwitchedByIgnition" SG_ 418 HMS_Stillstand 0;
BA_ "Fehlerwert" SG_ 418 HMS_Stillstand 7;
BA_ "GenSigSendType" SG_ 418 HMS_Systemstatus 3;
BA_ "GenSigStartValue" SG_ 418 HMS_Systemstatus 14;
BA_ "GenSigSwitchedByIgnition" SG_ 418 HMS_Systemstatus 0;
BA_ "Fehlerwert" SG_ 418 HMS_Systemstatus 15;
BA_ "GenSigSendType" SG_ 418 NL_PRIM_STP_01_Status 0;
BA_ "GenSigSwitchedByIgnition" SG_ 418 NL_PRIM_STP_01_Status 0;
BA_ "GenSigSendType" SG_ 418 VMM_Warnblinken 3;
BA_ "GenSigSwitchedByIgnition" SG_ 418 VMM_Warnblinken 0;
BA_ "GenSigSendType" SG_ 418 VZM_Status 0;
BA_ "GenSigSwitchedByIgnition" SG_ 418 VZM_Status 0;
BA_ "Fehlerwert" SG_ 418 VZM_Status 4;
BA_ "GenSigSendType" SG_ 253 ABS_Bremsung 0;
BA_ "GenSigSwitchedByIgnition" SG_ 253 ABS_Bremsung 0;
BA_ "GenSigSendType" SG_ 253 ASR_Anf 0;
BA_ "GenSigSwitchedByIgnition" SG_ 253 ASR_Anf 0;
BA_ "GenSigSendType" SG_ 253 ASR_Schalteingriff 0;
BA_ "GenSigSwitchedByIgnition" SG_ 253 ASR_Schalteingriff 0;
BA_ "GenSigSendType" SG_ 253 ASR_Tastung_passiv 0;
BA_ "GenSigSwitchedByIgnition" SG_ 253 ASR_Tastung_passiv 0;
BA_ "GenSigSendType" SG_ 253 BR_Eingriffsmoment 0;
BA_ "GenSigStartValue" SG_ 253 BR_Eingriffsmoment 1022;
BA_ "GenSigSwitchedByIgnition" SG_ 253 BR_Eingriffsmoment 0;
BA_ "Fehlerwert" SG_ 253 BR_Eingriffsmoment 1023;
BA_ "GenSigSendType" SG_ 253 EBV_Eingriff 0;
BA_ "GenSigSwitchedByIgnition" SG_ 253 EBV_Eingriff 0;
BA_ "GenSigSendType" SG_ 253 EDS_Eingriff 0;
BA_ "GenSigSwitchedByIgnition" SG_ 253 EDS_Eingriff 0;
BA_ "GenSigSendType" SG_ 253 ESC_Neutralschaltung 0;
BA_ "GenSigSwitchedByIgnition" SG_ 253 ESC_Neutralschaltung 0;
BA_ "GenSigSendType" SG_ 253 ESC_v_Signal_Qualifier_High_Low 0;
BA_ "GenSigStartValue" SG_ 253 ESC_v_Signal_Qualifier_High_Low 6;
BA_ "GenSigSwitchedByIgnition" SG_ 253 ESC_v_Signal_Qualifier_High_Low 0;
BA_ "Fehlerwert" SG_ 253 ESC_v_Signal_Qualifier_High_Low 7;
BA_ "GenSigSendType" SG_ 253 ESP_21_BZ 0;
BA_ "GenSigFuncType" SG_ 253 ESP_21_BZ 1;
BA_ "GenSigSwitchedByIgnition" SG_ 253 ESP_21_BZ 0;
BA_ "GenSigSendType" SG_ 253 ESP_21_CRC 0;
BA_ "GenSigFuncType" SG_ 253 ESP_21_CRC 2;
BA_ "GenSigSwitchedByIgnition" SG_ 253 ESP_21_CRC 0;
BA_ "GenSigSendType" SG_ 253 ESP_ASP 0;
BA_ "GenSigSwitchedByIgnition" SG_ 253 ESP_ASP 0;
BA_ "GenSigSendType" SG_ 253 ESP_Diagnose 0;
BA_ "GenSigSwitchedByIgnition" SG_ 253 ESP_Diagnose 0;
BA_ "GenSigSendType" SG_ 253 ESP_Eingriff 0;
BA_ "GenSigSwitchedByIgnition" SG_ 253 ESP_Eingriff 0;
BA_ "GenSigSendType" SG_ 253 ESP_QBit_v_Signal 0;
BA_ "GenSigStartValue" SG_ 253 ESP_QBit_v_Signal 1;
BA_ "GenSigSwitchedByIgnition" SG_ 253 ESP_QBit_v_Signal 0;
BA_ "GenSigSendType" SG_ 253 ESP_Systemstatus 0;
BA_ "GenSigSwitchedByIgnition" SG_ 253 ESP_Systemstatus 0;
BA_ "GenSigSendType" SG_ 253 ESP_Tastung_passiv 0;
BA_ "GenSigSwitchedByIgnition" SG_ 253 ESP_Tastung_passiv 0;
BA_ "GenSigSendType" SG_ 253 ESP_v_Signal 0;
BA_ "GenSigStartValue" SG_ 253 ESP_v_Signal 65534;
BA_ "GenSigSwitchedByIgnition" SG_ 253 ESP_v_Signal 0;
BA_ "Fehlerwert" SG_ 253 ESP_v_Signal 65535;
BA_ "GenSigMissingSourceValue" SG_ 253 ESP_v_Signal 65534;
BA_ "GenSigSendType" SG_ 253 ESP_Vorsteuerung 0;
BA_ "GenSigSwitchedByIgnition" SG_ 253 ESP_Vorsteuerung 0;
BA_ "GenSigSendType" SG_ 253 MSR_Anf 0;
BA_ "GenSigSwitchedByIgnition" SG_ 253 MSR_Anf 0;
BA_ "GenSigSendType" SG_ 253 MSR_verfuegbar 0;
BA_ "GenSigStartValue" SG_ 253 MSR_verfuegbar 1;
BA_ "GenSigSwitchedByIgnition" SG_ 253 MSR_verfuegbar 0;
BA_ "GenSigSendType" SG_ 253 OBD_QBit_Schlechtweg 0;
BA_ "GenSigStartValue" SG_ 253 OBD_QBit_Schlechtweg 1;
BA_ "GenSigSwitchedByIgnition" SG_ 253 OBD_QBit_Schlechtweg 0;
BA_ "GenSigSendType" SG_ 253 OBD_Schlechtweg 0;
BA_ "GenSigSwitchedByIgnition" SG_ 253 OBD_Schlechtweg 0;
BA_ "GenSigSendType" SG_ 1470 BR_QBit_Reifenumfang_sekundaer 0;
BA_ "GenSigStartValue" SG_ 1470 BR_QBit_Reifenumfang_sekundaer 1;
BA_ "GenSigSwitchedByIgnition" SG_ 1470 BR_QBit_Reifenumfang_sekundaer 0;
BA_ "GenSigSendType" SG_ 1470 BR_Reifenumfang_sekundaer 0;
BA_ "GenSigSwitchedByIgnition" SG_ 1470 BR_Reifenumfang_sekundaer 0;
BA_ "GenSigSendType" SG_ 1470 ESP_23_BZ 0;
BA_ "GenSigFuncType" SG_ 1470 ESP_23_BZ 1;
BA_ "GenSigSwitchedByIgnition" SG_ 1470 ESP_23_BZ 0;
BA_ "GenSigSendType" SG_ 1470 ESP_23_CRC 0;
BA_ "GenSigFuncType" SG_ 1470 ESP_23_CRC 2;
BA_ "GenSigSwitchedByIgnition" SG_ 1470 ESP_23_CRC 0;
BA_ "GenSigSendType" SG_ 1470 ESP_Gierrate_Offset_2 0;
BA_ "GenSigStartValue" SG_ 1470 ESP_Gierrate_Offset_2 2046;
BA_ "GenSigSwitchedByIgnition" SG_ 1470 ESP_Gierrate_Offset_2 0;
BA_ "Fehlerwert" SG_ 1470 ESP_Gierrate_Offset_2 2047;
BA_ "GenSigSendType" SG_ 1470 ESP_Laengsbeschleunigung_Offset 0;
BA_ "GenSigStartValue" SG_ 1470 ESP_Laengsbeschleunigung_Offset 254;
BA_ "GenSigSwitchedByIgnition" SG_ 1470 ESP_Laengsbeschleunigung_Offset 0;
BA_ "Fehlerwert" SG_ 1470 ESP_Laengsbeschleunigung_Offset 255;
BA_ "GenSigSendType" SG_ 1470 ESP_Lenkwinkel_Offset 0;
BA_ "GenSigStartValue" SG_ 1470 ESP_Lenkwinkel_Offset 510;
BA_ "GenSigSwitchedByIgnition" SG_ 1470 ESP_Lenkwinkel_Offset 0;
BA_ "Fehlerwert" SG_ 1470 ESP_Lenkwinkel_Offset 511;
BA_ "GenSigSendType" SG_ 1470 ESP_Querbeschleunigung_Offset 0;
BA_ "GenSigStartValue" SG_ 1470 ESP_Querbeschleunigung_Offset 62;
BA_ "GenSigSwitchedByIgnition" SG_ 1470 ESP_Querbeschleunigung_Offset 0;
BA_ "Fehlerwert" SG_ 1470 ESP_Querbeschleunigung_Offset 63;
BA_ "GenSigSendType" SG_ 1470 ESP_Status_Bremsentemp_Anz 0;
BA_ "GenSigSwitchedByIgnition" SG_ 1470 ESP_Status_Bremsentemp_Anz 0;
BA_ "Fehlerwert" SG_ 1470 ESP_Status_Bremsentemp_Anz 7;
BA_ "GenSigSendType" SG_ 508 ESC_Anforderung_Airbrake 0;
BA_ "GenSigSwitchedByIgnition" SG_ 508 ESC_Anforderung_Airbrake 0;
BA_ "GenSigSendType" SG_ 508 ESC_FBA_Meldungen 0;
BA_ "GenSigSwitchedByIgnition" SG_ 508 ESC_FBA_Meldungen 0;
BA_ "GenSigSendType" SG_ 508 ESC_MBK_Meldungen 0;
BA_ "GenSigSwitchedByIgnition" SG_ 508 ESC_MBK_Meldungen 0;
BA_ "GenSigSendType" SG_ 508 ESC_Motorstartverzoegerung 0;
BA_ "GenSigSwitchedByIgnition" SG_ 508 ESC_Motorstartverzoegerung 0;
BA_ "GenSigSendType" SG_ 508 ESP_32_BZ 0;
BA_ "GenSigFuncType" SG_ 508 ESP_32_BZ 1;
BA_ "GenSigSwitchedByIgnition" SG_ 508 ESP_32_BZ 0;
BA_ "GenSigSendType" SG_ 508 ESP_32_CRC 0;
BA_ "GenSigFuncType" SG_ 508 ESP_32_CRC 2;
BA_ "GenSigSwitchedByIgnition" SG_ 508 ESP_32_CRC 0;
BA_ "GenSigSendType" SG_ 508 ESP_Aggregataktivitaet 0;
BA_ "GenSigSwitchedByIgnition" SG_ 508 ESP_Aggregataktivitaet 0;
BA_ "GenSigSendType" SG_ 508 ESP_AVH_LED 0;
BA_ "GenSigStartValue" SG_ 508 ESP_AVH_LED 6;
BA_ "GenSigSwitchedByIgnition" SG_ 508 ESP_AVH_LED 0;
BA_ "GenSigSendType" SG_ 508 ESP_EDS_Anzeige 0;
BA_ "GenSigSwitchedByIgnition" SG_ 508 ESP_EDS_Anzeige 0;
BA_ "GenSigSendType" SG_ 508 ESP_HDC_LED 0;
BA_ "GenSigStartValue" SG_ 508 ESP_HDC_LED 6;
BA_ "GenSigSwitchedByIgnition" SG_ 508 ESP_HDC_LED 0;
BA_ "GenSigSendType" SG_ 508 ESP_HDC_Textanzeigen 0;
BA_ "GenSigSwitchedByIgnition" SG_ 508 ESP_HDC_Textanzeigen 0;
BA_ "GenSigSendType" SG_ 508 ESP_HOLD_verf 0;
BA_ "GenSigSwitchedByIgnition" SG_ 508 ESP_HOLD_verf 0;
BA_ "GenSigSendType" SG_ 508 ESP_Notbremsanzeige 0;
BA_ "GenSigSwitchedByIgnition" SG_ 508 ESP_Notbremsanzeige 0;
BA_ "GenSigSendType" SG_ 508 ESP_Off_LED 0;
BA_ "GenSigStartValue" SG_ 508 ESP_Off_LED 6;
BA_ "GenSigSwitchedByIgnition" SG_ 508 ESP_Off_LED 0;
BA_ "GenSigSendType" SG_ 508 ESP_Offroad_Lampe 0;
BA_ "GenSigSwitchedByIgnition" SG_ 508 ESP_Offroad_Lampe 0;
BA_ "GenSigSendType" SG_ 508 ESP_Rollover_Status_dyn 0;
BA_ "GenSigSwitchedByIgnition" SG_ 508 ESP_Rollover_Status_dyn 0;
BA_ "GenSigSendType" SG_ 508 ESP_Rollover_Status_stat 0;
BA_ "GenSigSwitchedByIgnition" SG_ 508 ESP_Rollover_Status_stat 0;
BA_ "GenSigSendType" SG_ 508 ESP_Status_Bremsentemp_02 0;
BA_ "GenSigSwitchedByIgnition" SG_ 508 ESP_Status_Bremsentemp_02 0;
BA_ "GenSigSendType" SG_ 508 ESP_Stillstandsflag 0;
BA_ "GenSigSwitchedByIgnition" SG_ 508 ESP_Stillstandsflag 0;
BA_ "GenSigSendType" SG_ 508 ESP_Wiederstart_Anz_Std 0;
BA_ "GenSigSwitchedByIgnition" SG_ 508 ESP_Wiederstart_Anz_Std 0;
BA_ "GenSigSendType" SG_ 508 RLE_Anzeigen 0;
BA_ "GenSigSwitchedByIgnition" SG_ 508 RLE_Anzeigen 0;
BA_ "GenSigSendType" SG_ 427 ESC_AHW_aktiv 3;
BA_ "GenSigSwitchedByIgnition" SG_ 427 ESC_AHW_aktiv 0;
BA_ "GenSigSendType" SG_ 427 ESC_AHW_nicht_verfuegbar 3;
BA_ "GenSigSwitchedByIgnition" SG_ 427 ESC_AHW_nicht_verfuegbar 0;
BA_ "GenSigSendType" SG_ 427 ESC_ANB_CM_aktiv 0;
BA_ "GenSigSwitchedByIgnition" SG_ 427 ESC_ANB_CM_aktiv 0;
BA_ "GenSigSendType" SG_ 427 ESC_ANB_CM_nicht_verfuegbar 0;
BA_ "GenSigSwitchedByIgnition" SG_ 427 ESC_ANB_CM_nicht_verfuegbar 0;
BA_ "GenSigSendType" SG_ 427 ESC_Bremslicht_unplausibel 3;
BA_ "GenSigSwitchedByIgnition" SG_ 427 ESC_Bremslicht_unplausibel 0;
BA_ "GenSigSendType" SG_ 427 ESC_Fahrer_Bremsdruck_bestimmend 0;
BA_ "GenSigSwitchedByIgnition" SG_ 427 ESC_Fahrer_Bremsdruck_bestimmend 0;
BA_ "GenSigSendType" SG_ 427 ESC_HBA_aktiv 3;
BA_ "GenSigSwitchedByIgnition" SG_ 427 ESC_HBA_aktiv 0;
BA_ "GenSigSendType" SG_ 427 ESC_HBA_nicht_verfuegbar 3;
BA_ "GenSigSwitchedByIgnition" SG_ 427 ESC_HBA_nicht_verfuegbar 0;
BA_ "GenSigSendType" SG_ 427 ESC_Konsistenz_ACC 0;
BA_ "GenSigSwitchedByIgnition" SG_ 427 ESC_Konsistenz_ACC 0;
BA_ "GenSigSendType" SG_ 427 ESC_Konsistenz_AGW 0;
BA_ "GenSigSwitchedByIgnition" SG_ 427 ESC_Konsistenz_AGW 0;
BA_ "GenSigSendType" SG_ 427 ESC_Konsistenz_ARA 3;
BA_ "GenSigSwitchedByIgnition" SG_ 427 ESC_Konsistenz_ARA 0;
BA_ "GenSigSendType" SG_ 427 ESC_Konsistenz_AWA 0;
BA_ "GenSigSwitchedByIgnition" SG_ 427 ESC_Konsistenz_AWA 0;
BA_ "GenSigSendType" SG_ 427 ESC_Konsistenz_AWV 0;
BA_ "GenSigSwitchedByIgnition" SG_ 427 ESC_Konsistenz_AWV 0;
BA_ "GenSigSendType" SG_ 427 ESC_Konsistenz_BFF 0;
BA_ "GenSigSwitchedByIgnition" SG_ 427 ESC_Konsistenz_BFF 0;
BA_ "GenSigSendType" SG_ 427 ESC_Konsistenz_EA 0;
BA_ "GenSigSwitchedByIgnition" SG_ 427 ESC_Konsistenz_EA 0;
BA_ "GenSigSendType" SG_ 427 ESC_Konsistenz_FAS_VK 0;
BA_ "GenSigSwitchedByIgnition" SG_ 427 ESC_Konsistenz_FAS_VK 0;
BA_ "GenSigSendType" SG_ 427 ESC_Konsistenz_FCW 0;
BA_ "GenSigSwitchedByIgnition" SG_ 427 ESC_Konsistenz_FCW 0;
BA_ "GenSigSendType" SG_ 427 ESC_Konsistenz_IPA 0;
BA_ "GenSigSwitchedByIgnition" SG_ 427 ESC_Konsistenz_IPA 0;
BA_ "GenSigSendType" SG_ 427 ESC_Konsistenz_KAS 0;
BA_ "GenSigSwitchedByIgnition" SG_ 427 ESC_Konsistenz_KAS 0;
BA_ "GenSigSendType" SG_ 427 ESC_Konsistenz_MKB 0;
BA_ "GenSigSwitchedByIgnition" SG_ 427 ESC_Konsistenz_MKB 0;
BA_ "GenSigSendType" SG_ 427 ESC_Konsistenz_NV 3;
BA_ "GenSigSwitchedByIgnition" SG_ 427 ESC_Konsistenz_NV 0;
BA_ "GenSigSendType" SG_ 427 ESC_Konsistenz_PCF 0;
BA_ "GenSigSwitchedByIgnition" SG_ 427 ESC_Konsistenz_PCF 0;
BA_ "GenSigSendType" SG_ 427 ESC_Konsistenz_RCTA 3;
BA_ "GenSigSwitchedByIgnition" SG_ 427 ESC_Konsistenz_RCTA 0;
BA_ "GenSigSendType" SG_ 427 ESC_Konsistenz_STA 0;
BA_ "GenSigSwitchedByIgnition" SG_ 427 ESC_Konsistenz_STA 0;
BA_ "GenSigSendType" SG_ 427 ESC_Konsistenz_TSK 0;
BA_ "GenSigSwitchedByIgnition" SG_ 427 ESC_Konsistenz_TSK 0;
BA_ "GenSigSendType" SG_ 427 ESC_Konsistenz_vFGS 0;
BA_ "GenSigSwitchedByIgnition" SG_ 427 ESC_Konsistenz_vFGS 0;
BA_ "GenSigSendType" SG_ 427 ESC_Prefill_aktiv 3;
BA_ "GenSigSwitchedByIgnition" SG_ 427 ESC_Prefill_aktiv 0;
BA_ "GenSigSendType" SG_ 427 ESC_Prefill_nicht_verfuegbar 3;
BA_ "GenSigSwitchedByIgnition" SG_ 427 ESC_Prefill_nicht_verfuegbar 0;
BA_ "GenSigSendType" SG_ 427 ESC_Pumpenanlauf_aktiv 0;
BA_ "GenSigSwitchedByIgnition" SG_ 427 ESC_Pumpenanlauf_aktiv 0;
BA_ "GenSigSendType" SG_ 427 ESC_TSK_SRBM_Anf 0;
BA_ "GenSigSwitchedByIgnition" SG_ 427 ESC_TSK_SRBM_Anf 0;
BA_ "GenSigSendType" SG_ 427 ESC_TSK_SRBM_nicht_verfuegbar 0;
BA_ "GenSigSwitchedByIgnition" SG_ 427 ESC_TSK_SRBM_nicht_verfuegbar 0;
BA_ "GenSigSendType" SG_ 427 ESC_Verz_ASIL_Verfuegbarkeit 0;
BA_ "GenSigSwitchedByIgnition" SG_ 427 ESC_Verz_ASIL_Verfuegbarkeit 0;
BA_ "GenSigSendType" SG_ 427 ESC_Verz_Begrenzung 0;
BA_ "GenSigSwitchedByIgnition" SG_ 427 ESC_Verz_Begrenzung 0;
BA_ "GenSigSendType" SG_ 427 ESC_Verz_Reg_aktiv 3;
BA_ "GenSigSwitchedByIgnition" SG_ 427 ESC_Verz_Reg_aktiv 0;
BA_ "GenSigSendType" SG_ 427 ESC_Verz_Reg_nicht_verfuegbar 0;
BA_ "GenSigSwitchedByIgnition" SG_ 427 ESC_Verz_Reg_nicht_verfuegbar 0;
BA_ "GenSigSendType" SG_ 427 ESC_Verz_Reg_TB_nicht_verfuegbar 0;
BA_ "GenSigSwitchedByIgnition" SG_ 427 ESC_Verz_Reg_TB_nicht_verfuegbar 0;
BA_ "GenSigSendType" SG_ 427 ESC_Verz_Reg_ZB_nicht_verfuegbar 0;
BA_ "GenSigSwitchedByIgnition" SG_ 427 ESC_Verz_Reg_ZB_nicht_verfuegbar 0;
BA_ "GenSigSendType" SG_ 427 ESC_Warnruck_aktiv 3;
BA_ "GenSigSwitchedByIgnition" SG_ 427 ESC_Warnruck_aktiv 0;
BA_ "GenSigSendType" SG_ 427 ESC_Warnruck_nicht_verfuegbar 3;
BA_ "GenSigSwitchedByIgnition" SG_ 427 ESC_Warnruck_nicht_verfuegbar 0;
BA_ "GenSigSendType" SG_ 427 ESP_33_BZ 0;
BA_ "GenSigFuncType" SG_ 427 ESP_33_BZ 1;
BA_ "GenSigSwitchedByIgnition" SG_ 427 ESP_33_BZ 0;
BA_ "GenSigSendType" SG_ 427 ESP_33_CRC 0;
BA_ "GenSigFuncType" SG_ 427 ESP_33_CRC 2;
BA_ "GenSigSwitchedByIgnition" SG_ 427 ESP_33_CRC 0;
BA_ "GenSigSendType" SG_ 264 EFP_Anf_Bremsenkuehlung 0;
BA_ "GenSigSwitchedByIgnition" SG_ 264 EFP_Anf_Bremsenkuehlung 0;
BA_ "GenSigSendType" SG_ 264 EFP_Reibwert_dyn 0;
BA_ "GenSigStartValue" SG_ 264 EFP_Reibwert_dyn 62;
BA_ "GenSigSwitchedByIgnition" SG_ 264 EFP_Reibwert_dyn 0;
BA_ "Fehlerwert" SG_ 264 EFP_Reibwert_dyn 63;
BA_ "GenSigSendType" SG_ 264 FA_Fahrbahnunebenheit 0;
BA_ "GenSigStartValue" SG_ 264 FA_Fahrbahnunebenheit 254;
BA_ "GenSigSwitchedByIgnition" SG_ 264 FA_Fahrbahnunebenheit 0;
BA_ "Fehlerwert" SG_ 264 FA_Fahrbahnunebenheit 255;
BA_ "GenSigSendType" SG_ 264 FA_Hoehenwert_HL_00 0;
BA_ "GenSigStartValue" SG_ 264 FA_Hoehenwert_HL_00 254;
BA_ "Fehlerwert" SG_ 264 FA_Hoehenwert_HL_00 255;
BA_ "GenSigSendType" SG_ 264 FA_Hoehenwert_HR_00 0;
BA_ "GenSigStartValue" SG_ 264 FA_Hoehenwert_HR_00 254;
BA_ "Fehlerwert" SG_ 264 FA_Hoehenwert_HR_00 255;
BA_ "GenSigSendType" SG_ 264 FA_Hoehenwert_VL_00 0;
BA_ "GenSigStartValue" SG_ 264 FA_Hoehenwert_VL_00 254;
BA_ "Fehlerwert" SG_ 264 FA_Hoehenwert_VL_00 255;
BA_ "GenSigSendType" SG_ 264 FA_Hoehenwert_VR_00 0;
BA_ "GenSigStartValue" SG_ 264 FA_Hoehenwert_VR_00 254;
BA_ "Fehlerwert" SG_ 264 FA_Hoehenwert_VR_00 255;
BA_ "GenSigSendType" SG_ 264 FA_Hoehenwerte_kalibriert 0;
BA_ "GenSigSendType" SG_ 264 Fahrwerk_01_BZ 0;
BA_ "GenSigFuncType" SG_ 264 Fahrwerk_01_BZ 1;
BA_ "GenSigSendType" SG_ 264 Fahrwerk_01_CRC 0;
BA_ "GenSigFuncType" SG_ 264 Fahrwerk_01_CRC 2;
BA_ "GenSigSendType" SG_ 429 EFP_Soll_FahrPr_HAL 0;
BA_ "GenSigSwitchedByIgnition" SG_ 429 EFP_Soll_FahrPr_HAL 0;
BA_ "GenSigSendType" SG_ 429 FA_Absenkung_Fahrzeug 0;
BA_ "GenSigSwitchedByIgnition" SG_ 429 FA_Absenkung_Fahrzeug 0;
BA_ "GenSigSendType" SG_ 429 FA_Anhaengerstatus_intern 0;
BA_ "GenSigSwitchedByIgnition" SG_ 429 FA_Anhaengerstatus_intern 0;
BA_ "GenSigSendType" SG_ 429 FA_Anhebung_Fahrzeug 0;
BA_ "GenSigSwitchedByIgnition" SG_ 429 FA_Anhebung_Fahrzeug 0;
BA_ "GenSigSendType" SG_ 429 FA_Druckspeicher_verfuegbar 0;
BA_ "GenSigSwitchedByIgnition" SG_ 429 FA_Druckspeicher_verfuegbar 0;
BA_ "GenSigSendType" SG_ 429 FA_ESP_Zuschaltung 0;
BA_ "GenSigSendType" SG_ 429 FA_HAL_Abschaltung 0;
BA_ "GenSigSwitchedByIgnition" SG_ 429 FA_HAL_Abschaltung 0;
BA_ "GenSigSendType" SG_ 429 FA_Kompressor_laeuft 0;
BA_ "GenSigSwitchedByIgnition" SG_ 429 FA_Kompressor_laeuft 0;
BA_ "GenSigSendType" SG_ 429 FA_Kompressor_laeuft_in_Kuerze 0;
BA_ "GenSigSwitchedByIgnition" SG_ 429 FA_Kompressor_laeuft_in_Kuerze 0;
BA_ "GenSigSendType" SG_ 429 FA_Signal_Drucksensor 0;
BA_ "GenSigStartValue" SG_ 429 FA_Signal_Drucksensor 254;
BA_ "GenSigSwitchedByIgnition" SG_ 429 FA_Signal_Drucksensor 0;
BA_ "Fehlerwert" SG_ 429 FA_Signal_Drucksensor 255;
BA_ "GenSigSendType" SG_ 429 FA_Systemstatus 0;
BA_ "GenSigSwitchedByIgnition" SG_ 429 FA_Systemstatus 0;
BA_ "GenSigSendType" SG_ 429 FA_Verstellung_aktiv 0;
BA_ "GenSigSwitchedByIgnition" SG_ 429 FA_Verstellung_aktiv 0;
BA_ "GenSigSendType" SG_ 429 FA_Verstellung_in_Kuerze 0;
BA_ "GenSigSwitchedByIgnition" SG_ 429 FA_Verstellung_in_Kuerze 0;
BA_ "GenSigSendType" SG_ 429 FA_Zwischenniveau 0;
BA_ "GenSigSwitchedByIgnition" SG_ 429 FA_Zwischenniveau 0;
BA_ "GenSigSendType" SG_ 429 Fahrwerk_06_BZ 0;
BA_ "GenSigFuncType" SG_ 429 Fahrwerk_06_BZ 1;
BA_ "GenSigSwitchedByIgnition" SG_ 429 Fahrwerk_06_BZ 0;
BA_ "GenSigSendType" SG_ 429 Fahrwerk_06_CRC 0;
BA_ "GenSigFuncType" SG_ 429 Fahrwerk_06_CRC 2;
BA_ "GenSigSwitchedByIgnition" SG_ 429 Fahrwerk_06_CRC 0;
BA_ "GenSigSendType" SG_ 429 NR_Anforderung_v_Begrenzung 0;
BA_ "GenSigSwitchedByIgnition" SG_ 429 NR_Anforderung_v_Begrenzung 0;
BA_ "GenSigSendType" SG_ 429 NR_Kompressor_Strom_02 0;
BA_ "Fehlerwert" SG_ 429 NR_Kompressor_Strom_02 255;
BA_ "GenSigSendType" SG_ 429 NR_Kompressor_Temp_Zylinderkopf 0;
BA_ "GenSigStartValue" SG_ 429 NR_Kompressor_Temp_Zylinderkopf 254;
BA_ "Fehlerwert" SG_ 429 NR_Kompressor_Temp_Zylinderkopf 255;
BA_ "GenSigSendType" SG_ 429 NR_LED_BN 3;
BA_ "GenSigSwitchedByIgnition" SG_ 429 NR_LED_BN 0;
BA_ "GenSigSendType" SG_ 429 NR_LED_HN 3;
BA_ "GenSigSwitchedByIgnition" SG_ 429 NR_LED_HN 0;
BA_ "GenSigSendType" SG_ 429 NR_LED_SGN 3;
BA_ "GenSigSwitchedByIgnition" SG_ 429 NR_LED_SGN 0;
BA_ "GenSigSendType" SG_ 429 NR_LED_TN 3;
BA_ "GenSigSwitchedByIgnition" SG_ 429 NR_LED_TN 0;
BA_ "GenSigSendType" SG_ 429 NR_Reglerstatus 3;
BA_ "GenSigSwitchedByIgnition" SG_ 429 NR_Reglerstatus 0;
BA_ "GenSigSendType" SG_ 852 FB_Kopf_erkannt 0;
BA_ "GenSigSendType" SG_ 852 FB_Lidoeffnungs_Dauer 0;
BA_ "GenSigSendType" SG_ 852 FB_Lidschlag_Dauer 0;
BA_ "GenSigSendType" SG_ 852 FB_Lidschlag_Frequenz 0;
BA_ "GenSigStartValue" SG_ 852 FB_Lidschlag_Frequenz 255;
BA_ "GenSigSendType" SG_ 852 FB_Lidschlag_Guete 0;
BA_ "GenSigSendType" SG_ 852 FB_Lidschliess_Dauer 0;
BA_ "GenSigSendType" SG_ 852 FB_Lidschluss_Dauer 0;
BA_ "GenSigSendType" SG_ 2527679660 FB_Blindheit 0;
BA_ "GenSigSendType" SG_ 2527679660 FB_Fahrerwechsel 0;
BA_ "GenSigStartValue" SG_ 2527679660 FB_Fahrerwechsel 3;
BA_ "GenSigSendType" SG_ 2527679660 FB_Fehler 0;
BA_ "Fehlerwert" SG_ 2527679660 FB_Fehler 1;
BA_ "GenSigSendType" SG_ 2527679660 FB_Kopfaktivitaet_A1 0;
BA_ "GenSigStartValue" SG_ 2527679660 FB_Kopfaktivitaet_A1 15;
BA_ "GenSigSendType" SG_ 2527679660 FB_Kopfaktivitaet_A1_Guete 0;
BA_ "GenSigSendType" SG_ 2527679660 FB_Kopfaktivitaet_A2 0;
BA_ "GenSigStartValue" SG_ 2527679660 FB_Kopfaktivitaet_A2 15;
BA_ "GenSigSendType" SG_ 2527679660 FB_Kopfaktivitaet_A2_Guete 0;
BA_ "GenSigSendType" SG_ 2527679660 FB_Muedigkeit_Guete 0;
BA_ "GenSigSendType" SG_ 2527679660 FB_Muedigkeit_Index 0;
BA_ "GenSigStartValue" SG_ 2527679660 FB_Muedigkeit_Index 255;
BA_ "GenSigSendType" SG_ 2527679660 FB_NichtVerfuegbar 0;
BA_ "GenSigStartValue" SG_ 2527679660 FB_NichtVerfuegbar 1;
BA_ "GenSigSendType" SG_ 853 FB_Blickbereich 0;
BA_ "GenSigStartValue" SG_ 853 FB_Blickbereich 15;
BA_ "GenSigSendType" SG_ 853 FB_Blickbereich_Guete 0;
BA_ "GenSigSendType" SG_ 853 FB_Kopfrotation_Nick 0;
BA_ "GenSigStartValue" SG_ 853 FB_Kopfrotation_Nick 254;
BA_ "Fehlerwert" SG_ 853 FB_Kopfrotation_Nick 255;
BA_ "GenSigSendType" SG_ 853 FB_Kopfrotation_Nick_Guete 0;
BA_ "GenSigSendType" SG_ 853 FB_Kopfrotation_Roll 0;
BA_ "GenSigStartValue" SG_ 853 FB_Kopfrotation_Roll 254;
BA_ "Fehlerwert" SG_ 853 FB_Kopfrotation_Roll 255;
BA_ "GenSigSendType" SG_ 853 FB_Kopfrotation_Roll_Guete 0;
BA_ "GenSigSendType" SG_ 854 FB_Kopfposition_X 0;
BA_ "GenSigStartValue" SG_ 854 FB_Kopfposition_X 254;
BA_ "Fehlerwert" SG_ 854 FB_Kopfposition_X 255;
BA_ "GenSigSendType" SG_ 854 FB_Kopfposition_X_Guete 0;
BA_ "GenSigSendType" SG_ 854 FB_Kopfposition_Y 0;
BA_ "GenSigStartValue" SG_ 854 FB_Kopfposition_Y 254;
BA_ "Fehlerwert" SG_ 854 FB_Kopfposition_Y 255;
BA_ "GenSigSendType" SG_ 854 FB_Kopfposition_Y_Guete 0;
BA_ "GenSigSendType" SG_ 854 FB_Kopfposition_Z 0;
BA_ "GenSigStartValue" SG_ 854 FB_Kopfposition_Z 254;
BA_ "Fehlerwert" SG_ 854 FB_Kopfposition_Z 255;
BA_ "GenSigSendType" SG_ 854 FB_Kopfposition_Z_Guete 0;
BA_ "GenSigSendType" SG_ 854 FB_Kopfrotation_Gier 0;
BA_ "GenSigStartValue" SG_ 854 FB_Kopfrotation_Gier 254;
BA_ "Fehlerwert" SG_ 854 FB_Kopfrotation_Gier 255;
BA_ "GenSigSendType" SG_ 854 FB_Kopfrotation_Gier_Guete 0;
BA_ "GenSigSendType" SG_ 1605 FLA_Abblendursache 3;
BA_ "Fehlerwert" SG_ 1605 FLA_Abblendursache 255;
BA_ "GenSigSendType" SG_ 1605 FLA_aktiv 3;
BA_ "GenSigSendType" SG_ 1605 FLA_Aufblenden 3;
BA_ "GenSigSendType" SG_ 1605 FLA_Fernlicht_PWM 3;
BA_ "GenSigStartValue" SG_ 1605 FLA_Fernlicht_PWM 100;
BA_ "Fehlerwert" SG_ 1605 FLA_Fernlicht_PWM 127;
BA_ "GenSigSendType" SG_ 1605 FLA_ISP_defekt 3;
BA_ "GenSigSendType" SG_ 1605 FLA_SAE_Mode 3;
BA_ "GenSigSendType" SG_ 1605 FLA_Sensor_blockiert 3;
BA_ "GenSigSendType" SG_ 1605 ISP_Dimmung_ASP_02 3;
BA_ "GenSigSendType" SG_ 1605 ISP_EC_aktiv 3;
BA_ "GenSigStartValue" SG_ 1605 ISP_EC_aktiv 1;
BA_ "GenSigSendType" SG_ 1605 ISP_EC_Lichtwert_hinten 3;
BA_ "GenSigStartValue" SG_ 1605 ISP_EC_Lichtwert_hinten 62;
BA_ "Fehlerwert" SG_ 1605 ISP_EC_Lichtwert_hinten 63;
BA_ "GenSigSendType" SG_ 1605 ISP_EC_Lichtwert_vorne 3;
BA_ "GenSigStartValue" SG_ 1605 ISP_EC_Lichtwert_vorne 62;
BA_ "Fehlerwert" SG_ 1605 ISP_EC_Lichtwert_vorne 63;
BA_ "GenSigSendType" SG_ 1605 ISP_Himmelsrichtung 3;
BA_ "GenSigStartValue" SG_ 1605 ISP_Himmelsrichtung 30;
BA_ "Fehlerwert" SG_ 1605 ISP_Himmelsrichtung 31;
BA_ "GenSigSendType" SG_ 1605 ISP_Kompass_aktiv 3;
BA_ "GenSigStartValue" SG_ 1605 ISP_Kompass_aktiv 1;
BA_ "GenSigSendType" SG_ 1605 ISP_Taste_betaetigt 3;
BA_ "GenSigSendType" SG_ 2589283684 FoD_Anz_Funktionsabschaltung 3;
BA_ "GenSigSwitchedByIgnition" SG_ 2589283684 FoD_Anz_Funktionsabschaltung 0;
BA_ "GenSigSendType" SG_ 2589283684 FoD_Transmission_Info 3;
BA_ "GenSigSwitchedByIgnition" SG_ 2589283684 FoD_Transmission_Info 0;
BA_ "GenSigSendType" SG_ 2549875470 FoD_BCM1_Req_Data 3;
BA_ "GenSigFuncType" SG_ 2549875470 FoD_BCM1_Req_Data 9;
BA_ "GenSigSwitchedByIgnition" SG_ 2549875470 FoD_BCM1_Req_Data 0;
BA_ "GenSigSendType" SG_ 2550006542 FoD_BCM1_Resp_Data 3;
BA_ "GenSigFuncType" SG_ 2550006542 FoD_BCM1_Resp_Data 9;
BA_ "GenSigSwitchedByIgnition" SG_ 2550006542 FoD_BCM1_Resp_Data 0;
BA_ "GenSigSendType" SG_ 1523 Diag_Frontscheibe 0;
BA_ "GenSigSwitchedByIgnition" SG_ 1523 Diag_Frontscheibe 0;
BA_ "GenSigSendType" SG_ 1523 FSH_LED 0;
BA_ "GenSigSwitchedByIgnition" SG_ 1523 FSH_LED 0;
BA_ "GenSigSendType" SG_ 1523 FSW_Lokalaktiv 0;
BA_ "GenSigSwitchedByIgnition" SG_ 1523 FSW_Lokalaktiv 0;
BA_ "GenSigSendType" SG_ 1523 HW_SW_Frontscheibe 0;
BA_ "GenSigSwitchedByIgnition" SG_ 1523 HW_SW_Frontscheibe 0;
BA_ "GenSigSendType" SG_ 1523 I_Heiz_Frontscheibe 0;
BA_ "GenSigStartValue" SG_ 1523 I_Heiz_Frontscheibe 254;
BA_ "GenSigSwitchedByIgnition" SG_ 1523 I_Heiz_Frontscheibe 0;
BA_ "GenSigSendType" SG_ 1523 P_Heiz_Frontscheibe 0;
BA_ "GenSigStartValue" SG_ 1523 P_Heiz_Frontscheibe 254;
BA_ "GenSigSwitchedByIgnition" SG_ 1523 P_Heiz_Frontscheibe 0;
BA_ "Fehlerwert" SG_ 1523 P_Heiz_Frontscheibe 255;
BA_ "GenSigSendType" SG_ 1523 R_grenz_max 0;
BA_ "GenSigStartValue" SG_ 1523 R_grenz_max 254;
BA_ "GenSigSwitchedByIgnition" SG_ 1523 R_grenz_max 0;
BA_ "GenSigSendType" SG_ 1523 R_grenz_min 0;
BA_ "GenSigStartValue" SG_ 1523 R_grenz_min 254;
BA_ "GenSigSwitchedByIgnition" SG_ 1523 R_grenz_min 0;
BA_ "GenSigSendType" SG_ 1523 R_ist 0;
BA_ "GenSigStartValue" SG_ 1523 R_ist 254;
BA_ "GenSigSwitchedByIgnition" SG_ 1523 R_ist 0;
BA_ "GenSigSendType" SG_ 173 GE_Fahrstufe 3;
BA_ "GenSigStartValue" SG_ 173 GE_Fahrstufe 1;
BA_ "GenSigSwitchedByIgnition" SG_ 173 GE_Fahrstufe 0;
BA_ "Fehlerwert" SG_ 173 GE_Fahrstufe 15;
BA_ "GenSigSendType" SG_ 173 GE_Freig_MMom_Vorhalt 0;
BA_ "GenSigSwitchedByIgnition" SG_ 173 GE_Freig_MMom_Vorhalt 0;
BA_ "GenSigSendType" SG_ 173 GE_MMom_Soll_02 0;
BA_ "GenSigStartValue" SG_ 173 GE_MMom_Soll_02 1022;
BA_ "GenSigSwitchedByIgnition" SG_ 173 GE_MMom_Soll_02 0;
BA_ "Fehlerwert" SG_ 173 GE_MMom_Soll_02 1023;
BA_ "GenSigSendType" SG_ 173 GE_MMom_Status 0;
BA_ "GenSigSwitchedByIgnition" SG_ 173 GE_MMom_Status 0;
BA_ "GenSigSendType" SG_ 173 GE_MMom_Status_02 0;
BA_ "GenSigSwitchedByIgnition" SG_ 173 GE_MMom_Status_02 0;
BA_ "GenSigSendType" SG_ 173 GE_MMom_Vorhalt_02 0;
BA_ "GenSigStartValue" SG_ 173 GE_MMom_Vorhalt_02 1022;
BA_ "GenSigSwitchedByIgnition" SG_ 173 GE_MMom_Vorhalt_02 0;
BA_ "Fehlerwert" SG_ 173 GE_MMom_Vorhalt_02 1023;
BA_ "GenSigSendType" SG_ 173 GE_reserv_Fahrstufe 0;
BA_ "GenSigSwitchedByIgnition" SG_ 173 GE_reserv_Fahrstufe 0;
BA_ "GenSigSendType" SG_ 173 GE_Schaltablauf 0;
BA_ "GenSigSwitchedByIgnition" SG_ 173 GE_Schaltablauf 0;
BA_ "GenSigSendType" SG_ 173 GE_Status_Kraftschluss 0;
BA_ "GenSigSwitchedByIgnition" SG_ 173 GE_Status_Kraftschluss 0;
BA_ "GenSigSendType" SG_ 173 GE_Uefkt 0;
BA_ "GenSigSwitchedByIgnition" SG_ 173 GE_Uefkt 0;
BA_ "Fehlerwert" SG_ 173 GE_Uefkt 1023;
BA_ "GenSigSendType" SG_ 173 GE_Uefkt_unplausibel 0;
BA_ "GenSigSwitchedByIgnition" SG_ 173 GE_Uefkt_unplausibel 0;
BA_ "GenSigSendType" SG_ 173 GE_Verbot_Ausblendung 0;
BA_ "GenSigSwitchedByIgnition" SG_ 173 GE_Verbot_Ausblendung 0;
BA_ "GenSigSendType" SG_ 173 GE_Zielgang 0;
BA_ "GenSigSwitchedByIgnition" SG_ 173 GE_Zielgang 0;
BA_ "Fehlerwert" SG_ 173 GE_Zielgang 15;
BA_ "GenSigSendType" SG_ 173 Getriebe_11_BZ 0;
BA_ "GenSigFuncType" SG_ 173 Getriebe_11_BZ 1;
BA_ "GenSigSwitchedByIgnition" SG_ 173 Getriebe_11_BZ 0;
BA_ "GenSigSendType" SG_ 173 Getriebe_11_CRC 0;
BA_ "GenSigFuncType" SG_ 173 Getriebe_11_CRC 2;
BA_ "GenSigSwitchedByIgnition" SG_ 173 Getriebe_11_CRC 0;
BA_ "GenSigSendType" SG_ 177 GE_Anschleppstart_Freigabe 0;
BA_ "GenSigSwitchedByIgnition" SG_ 177 GE_Anschleppstart_Freigabe 0;
BA_ "GenSigSendType" SG_ 177 GE_Eingangsdrehz_Praed 0;
BA_ "GenSigStartValue" SG_ 177 GE_Eingangsdrehz_Praed 16382;
BA_ "GenSigSwitchedByIgnition" SG_ 177 GE_Eingangsdrehz_Praed 0;
BA_ "Fehlerwert" SG_ 177 GE_Eingangsdrehz_Praed 16383;
BA_ "GenSigSendType" SG_ 177 GE_Fahrprogramm 0;
BA_ "GenSigSwitchedByIgnition" SG_ 177 GE_Fahrprogramm 0;
BA_ "GenSigSendType" SG_ 177 GE_Freilauf_Status 3;
BA_ "GenSigSwitchedByIgnition" SG_ 177 GE_Freilauf_Status 0;
BA_ "Fehlerwert" SG_ 177 GE_Freilauf_Status 7;
BA_ "GenSigSendType" SG_ 177 GE_Getriebestatus_02 0;
BA_ "GenSigSwitchedByIgnition" SG_ 177 GE_Getriebestatus_02 0;
BA_ "GenSigSendType" SG_ 177 GE_Grundeinstellung 0;
BA_ "GenSigSwitchedByIgnition" SG_ 177 GE_Grundeinstellung 0;
BA_ "GenSigSendType" SG_ 177 GE_KomFehler_ESP 0;
BA_ "GenSigSwitchedByIgnition" SG_ 177 GE_KomFehler_ESP 0;
BA_ "Fehlerwert" SG_ 177 GE_KomFehler_ESP 1;
BA_ "GenSigSendType" SG_ 177 GE_Rollrichtung_falsch 0;
BA_ "GenSigSwitchedByIgnition" SG_ 177 GE_Rollrichtung_falsch 0;
BA_ "GenSigSendType" SG_ 177 GE_Strombedarf_erh 0;
BA_ "GenSigSwitchedByIgnition" SG_ 177 GE_Strombedarf_erh 0;
BA_ "GenSigSendType" SG_ 177 GE_TippZustand 0;
BA_ "GenSigSwitchedByIgnition" SG_ 177 GE_TippZustand 0;
BA_ "GenSigSendType" SG_ 177 GE_Uefkt_Praed 0;
BA_ "GenSigSwitchedByIgnition" SG_ 177 GE_Uefkt_Praed 0;
BA_ "Fehlerwert" SG_ 177 GE_Uefkt_Praed 16383;
BA_ "GenSigSendType" SG_ 177 Getriebe_17_BZ 0;
BA_ "GenSigFuncType" SG_ 177 Getriebe_17_BZ 1;
BA_ "GenSigSwitchedByIgnition" SG_ 177 Getriebe_17_BZ 0;
BA_ "GenSigSendType" SG_ 177 Getriebe_17_CRC 0;
BA_ "GenSigFuncType" SG_ 177 Getriebe_17_CRC 2;
BA_ "GenSigSwitchedByIgnition" SG_ 177 Getriebe_17_CRC 0;
BA_ "GenSigSendType" SG_ 310 HAL_01_BZ 0;
BA_ "GenSigFuncType" SG_ 310 HAL_01_BZ 1;
BA_ "GenSigSwitchedByIgnition" SG_ 310 HAL_01_BZ 0;
BA_ "GenSigSendType" SG_ 310 HAL_01_CRC 0;
BA_ "GenSigFuncType" SG_ 310 HAL_01_CRC 2;
BA_ "GenSigSwitchedByIgnition" SG_ 310 HAL_01_CRC 0;
BA_ "GenSigSendType" SG_ 310 HAL_Charisma_FahrPr 0;
BA_ "GenSigSwitchedByIgnition" SG_ 310 HAL_Charisma_FahrPr 0;
BA_ "GenSigSendType" SG_ 310 HAL_Charisma_Status 0;
BA_ "GenSigSwitchedByIgnition" SG_ 310 HAL_Charisma_Status 0;
BA_ "GenSigSendType" SG_ 310 HAL_EFP_FahrPr 0;
BA_ "GenSigSwitchedByIgnition" SG_ 310 HAL_EFP_FahrPr 0;
BA_ "GenSigSendType" SG_ 310 HAL_Fahrerwunschwinkel_Soll 0;
BA_ "GenSigStartValue" SG_ 310 HAL_Fahrerwunschwinkel_Soll 1022;
BA_ "GenSigSwitchedByIgnition" SG_ 310 HAL_Fahrerwunschwinkel_Soll 0;
BA_ "Fehlerwert" SG_ 310 HAL_Fahrerwunschwinkel_Soll 1023;
BA_ "GenSigSendType" SG_ 310 HAL_max_Gradient 0;
BA_ "GenSigStartValue" SG_ 310 HAL_max_Gradient 126;
BA_ "GenSigSwitchedByIgnition" SG_ 310 HAL_max_Gradient 0;
BA_ "Fehlerwert" SG_ 310 HAL_max_Gradient 127;
BA_ "GenSigSendType" SG_ 310 HAL_QBit_Radwinkel 0;
BA_ "GenSigSwitchedByIgnition" SG_ 310 HAL_QBit_Radwinkel 0;
BA_ "GenSigSendType" SG_ 310 HAL_Radwinkel 0;
BA_ "GenSigStartValue" SG_ 310 HAL_Radwinkel 1022;
BA_ "GenSigSwitchedByIgnition" SG_ 310 HAL_Radwinkel 0;
BA_ "Fehlerwert" SG_ 310 HAL_Radwinkel 1023;
BA_ "GenSigSendType" SG_ 310 HAL_Status 0;
BA_ "GenSigSwitchedByIgnition" SG_ 310 HAL_Status 0;
BA_ "GenSigSendType" SG_ 310 HAL_Status_2 0;
BA_ "GenSigSwitchedByIgnition" SG_ 310 HAL_Status_2 0;
BA_ "GenSigSendType" SG_ 310 HAL_VZ_Fahrerwunschwinkel_Soll 0;
BA_ "GenSigSwitchedByIgnition" SG_ 310 HAL_VZ_Fahrerwunschwinkel_Soll 0;
BA_ "GenSigSendType" SG_ 310 HAL_VZ_Radwinkel 0;
BA_ "GenSigSwitchedByIgnition" SG_ 310 HAL_VZ_Radwinkel 0;
BA_ "GenSigSendType" SG_ 310 HAL_Warnungen 0;
BA_ "GenSigSwitchedByIgnition" SG_ 310 HAL_Warnungen 0;
BA_ "GenSigSendType" SG_ 310 HAL_Winkelbegrenzung 0;
BA_ "GenSigSwitchedByIgnition" SG_ 310 HAL_Winkelbegrenzung 0;
BA_ "GenSigSendType" SG_ 676 HAL_02_BZ 0;
BA_ "GenSigFuncType" SG_ 676 HAL_02_BZ 1;
BA_ "GenSigSwitchedByIgnition" SG_ 676 HAL_02_BZ 0;
BA_ "GenSigSendType" SG_ 676 HAL_02_CRC 0;
BA_ "GenSigFuncType" SG_ 676 HAL_02_CRC 2;
BA_ "GenSigSwitchedByIgnition" SG_ 676 HAL_02_CRC 0;
BA_ "GenSigSendType" SG_ 676 HAL_ARA_Status 0;
BA_ "GenSigSwitchedByIgnition" SG_ 676 HAL_ARA_Status 0;
BA_ "GenSigSendType" SG_ 676 HAL_IL_Status 0;
BA_ "GenSigStartValue" SG_ 676 HAL_IL_Status 1;
BA_ "GenSigSwitchedByIgnition" SG_ 676 HAL_IL_Status 0;
BA_ "GenSigSendType" SG_ 676 HAL_PLA_Status 0;
BA_ "GenSigSwitchedByIgnition" SG_ 676 HAL_PLA_Status 0;
BA_ "GenSigSendType" SG_ 676 HAL_PWR_Abbruch 0;
BA_ "GenSigSwitchedByIgnition" SG_ 676 HAL_PWR_Abbruch 0;
BA_ "GenSigSendType" SG_ 676 HAL_PWR_Fehler 0;
BA_ "GenSigSwitchedByIgnition" SG_ 676 HAL_PWR_Fehler 0;
BA_ "GenSigSendType" SG_ 676 HAL_Temperatur 0;
BA_ "GenSigStartValue" SG_ 676 HAL_Temperatur 254;
BA_ "GenSigSwitchedByIgnition" SG_ 676 HAL_Temperatur 0;
BA_ "Fehlerwert" SG_ 676 HAL_Temperatur 255;
BA_ "GenSigSendType" SG_ 1410 HD_Bewegung_auf 0;
BA_ "GenSigSwitchedByIgnition" SG_ 1410 HD_Bewegung_auf 0;
BA_ "GenSigSendType" SG_ 1410 HD_Bewegung_zu 0;
BA_ "GenSigSwitchedByIgnition" SG_ 1410 HD_Bewegung_zu 0;
BA_ "GenSigSendType" SG_ 1410 HD_Endstellung_oben 0;
BA_ "GenSigSwitchedByIgnition" SG_ 1410 HD_Endstellung_oben 0;
BA_ "GenSigSendType" SG_ 1410 HD_Endstellung_unten 0;
BA_ "GenSigSwitchedByIgnition" SG_ 1410 HD_Endstellung_unten 0;
BA_ "GenSigSendType" SG_ 1410 HD_Innentaster_betaetigt 0;
BA_ "GenSigSwitchedByIgnition" SG_ 1410 HD_Innentaster_betaetigt 0;
BA_ "GenSigSendType" SG_ 1410 HD_Position 0;
BA_ "GenSigSwitchedByIgnition" SG_ 1410 HD_Position 0;
BA_ "GenSigSendType" SG_ 1410 HD_Rueckmeld_prog 0;
BA_ "GenSigSwitchedByIgnition" SG_ 1410 HD_Rueckmeld_prog 0;
BA_ "GenSigSendType" SG_ 1410 HD_Taster_defekt 0;
BA_ "GenSigSwitchedByIgnition" SG_ 1410 HD_Taster_defekt 0;
BA_ "GenSigSendType" SG_ 1410 HD_UeKB_erkannt 0;
BA_ "GenSigSwitchedByIgnition" SG_ 1410 HD_UeKB_erkannt 0;
BA_ "GenSigSendType" SG_ 1410 HD_Verr_Taster_betaetigt_inv 0;
BA_ "GenSigSwitchedByIgnition" SG_ 1410 HD_Verr_Taster_betaetigt_inv 0;
BA_ "GenSigSendType" SG_ 1410 HD_Verriegelungstaster_betaetigt 0;
BA_ "GenSigSwitchedByIgnition" SG_ 1410 HD_Verriegelungstaster_betaetigt 0;
BA_ "GenSigSendType" SG_ 1410 HD_ZZH_Schalter_S3 3;
BA_ "GenSigSwitchedByIgnition" SG_ 1410 HD_ZZH_Schalter_S3 0;
BA_ "GenSigSendType" SG_ 1416 BCM1_TCH_HLR_Anf 3;
BA_ "GenSigSwitchedByIgnition" SG_ 1416 BCM1_TCH_HLR_Anf 0;
BA_ "GenSigSendType" SG_ 1416 FSH_LED 3;
BA_ "GenSigSwitchedByIgnition" SG_ 1416 FSH_LED 0;
BA_ "GenSigSendType" SG_ 1416 HLR_SIH_Freigabe_Fond 3;
BA_ "GenSigSwitchedByIgnition" SG_ 1416 HLR_SIH_Freigabe_Fond 0;
BA_ "GenSigSendType" SG_ 1416 HSH_LED 3;
BA_ "GenSigSwitchedByIgnition" SG_ 1416 HSH_LED 0;
BA_ "GenSigSendType" SG_ 1416 KRH_Stufe_LED_li 3;
BA_ "GenSigSwitchedByIgnition" SG_ 1416 KRH_Stufe_LED_li 0;
BA_ "GenSigSendType" SG_ 1416 KRH_Stufe_LED_re 3;
BA_ "GenSigSwitchedByIgnition" SG_ 1416 KRH_Stufe_LED_re 0;
BA_ "GenSigSendType" SG_ 1416 SIH_Stufe_LED_HL 3;
BA_ "GenSigSwitchedByIgnition" SG_ 1416 SIH_Stufe_LED_HL 0;
BA_ "GenSigSendType" SG_ 1416 SIH_Stufe_LED_HR 3;
BA_ "GenSigSwitchedByIgnition" SG_ 1416 SIH_Stufe_LED_HR 0;
BA_ "GenSigSendType" SG_ 1416 SIH_Stufe_LED_li 3;
BA_ "GenSigSwitchedByIgnition" SG_ 1416 SIH_Stufe_LED_li 0;
BA_ "GenSigSendType" SG_ 1416 SIH_Stufe_LED_re 3;
BA_ "GenSigSwitchedByIgnition" SG_ 1416 SIH_Stufe_LED_re 0;
BA_ "GenSigSendType" SG_ 1416 SIL_Stufe_LED_HL 3;
BA_ "GenSigSwitchedByIgnition" SG_ 1416 SIL_Stufe_LED_HL 0;
BA_ "GenSigSendType" SG_ 1416 SIL_Stufe_LED_HR 3;
BA_ "GenSigSwitchedByIgnition" SG_ 1416 SIL_Stufe_LED_HR 0;
BA_ "GenSigSendType" SG_ 1416 SIL_Stufe_LED_li 3;
BA_ "GenSigSwitchedByIgnition" SG_ 1416 SIL_Stufe_LED_li 0;
BA_ "GenSigSendType" SG_ 1416 SIL_Stufe_LED_re 3;
BA_ "GenSigSwitchedByIgnition" SG_ 1416 SIL_Stufe_LED_re 0;
BA_ "GenSigSendType" SG_ 1016 HLR_FlHz_Freigabe_HL 3;
BA_ "GenSigSwitchedByIgnition" SG_ 1016 HLR_FlHz_Freigabe_HL 0;
BA_ "GenSigSendType" SG_ 1016 HLR_FlHz_Freigabe_HR 3;
BA_ "GenSigSwitchedByIgnition" SG_ 1016 HLR_FlHz_Freigabe_HR 0;
BA_ "GenSigSendType" SG_ 1016 HLR_FlHz_Freigabe_Ruhesitz 3;
BA_ "GenSigSwitchedByIgnition" SG_ 1016 HLR_FlHz_Freigabe_Ruhesitz 0;
BA_ "GenSigSendType" SG_ 1016 HLR_FlHz_Freigabe_VL 3;
BA_ "GenSigSwitchedByIgnition" SG_ 1016 HLR_FlHz_Freigabe_VL 0;
BA_ "GenSigSendType" SG_ 1016 HLR_FlHz_Freigabe_VR 3;
BA_ "GenSigSwitchedByIgnition" SG_ 1016 HLR_FlHz_Freigabe_VR 0;
BA_ "GenSigSendType" SG_ 1016 HLR_FSH_Freigabe 3;
BA_ "GenSigSwitchedByIgnition" SG_ 1016 HLR_FSH_Freigabe 0;
BA_ "Fehlerwert" SG_ 1016 HLR_FSH_Freigabe 63;
BA_ "GenSigSendType" SG_ 1016 HLR_HSH_Freigabe 3;
BA_ "GenSigSwitchedByIgnition" SG_ 1016 HLR_HSH_Freigabe 0;
BA_ "GenSigSendType" SG_ 1016 HLR_KRH_Freigabe_VL 3;
BA_ "GenSigSwitchedByIgnition" SG_ 1016 HLR_KRH_Freigabe_VL 0;
BA_ "GenSigSendType" SG_ 1016 HLR_KRH_Freigabe_VR 3;
BA_ "GenSigSwitchedByIgnition" SG_ 1016 HLR_KRH_Freigabe_VR 0;
BA_ "GenSigSendType" SG_ 1016 HLR_LRH_Freigabe 3;
BA_ "GenSigSwitchedByIgnition" SG_ 1016 HLR_LRH_Freigabe 0;
BA_ "GenSigSendType" SG_ 1016 HLR_PTC_Freigabe 3;
BA_ "GenSigStartValue" SG_ 1016 HLR_PTC_Freigabe 3;
BA_ "GenSigSwitchedByIgnition" SG_ 1016 HLR_PTC_Freigabe 0;
BA_ "GenSigSendType" SG_ 1016 HLR_PTC_linear_Freigabe 3;
BA_ "GenSigSwitchedByIgnition" SG_ 1016 HLR_PTC_linear_Freigabe 0;
BA_ "Fehlerwert" SG_ 1016 HLR_PTC_linear_Freigabe 63;
BA_ "GenSigSendType" SG_ 1016 HLR_SIH_Freigabe_Fond 3;
BA_ "GenSigSwitchedByIgnition" SG_ 1016 HLR_SIH_Freigabe_Fond 0;
BA_ "GenSigSendType" SG_ 1016 HLR_SIH_Freigabe_HL 3;
BA_ "GenSigSwitchedByIgnition" SG_ 1016 HLR_SIH_Freigabe_HL 0;
BA_ "GenSigSendType" SG_ 1016 HLR_SIH_Freigabe_HR 3;
BA_ "GenSigSwitchedByIgnition" SG_ 1016 HLR_SIH_Freigabe_HR 0;
BA_ "GenSigSendType" SG_ 1016 HLR_SIH_Freigabe_VL 3;
BA_ "GenSigSwitchedByIgnition" SG_ 1016 HLR_SIH_Freigabe_VL 0;
BA_ "GenSigSendType" SG_ 1016 HLR_SIH_Freigabe_VR 3;
BA_ "GenSigSwitchedByIgnition" SG_ 1016 HLR_SIH_Freigabe_VR 0;
BA_ "GenSigSendType" SG_ 1016 HLR_SIL_Freigabe_HL 3;
BA_ "GenSigSwitchedByIgnition" SG_ 1016 HLR_SIL_Freigabe_HL 0;
BA_ "GenSigSendType" SG_ 1016 HLR_SIL_Freigabe_HR 3;
BA_ "GenSigSwitchedByIgnition" SG_ 1016 HLR_SIL_Freigabe_HR 0;
BA_ "GenSigSendType" SG_ 1016 HLR_SIL_Freigabe_VL 3;
BA_ "GenSigSwitchedByIgnition" SG_ 1016 HLR_SIL_Freigabe_VL 0;
BA_ "GenSigSendType" SG_ 1016 HLR_SIL_Freigabe_VR 3;
BA_ "GenSigSwitchedByIgnition" SG_ 1016 HLR_SIL_Freigabe_VR 0;
BA_ "GenSigSendType" SG_ 1016 HLR_Sp_Heizung_Freigabe_BT 3;
BA_ "GenSigSwitchedByIgnition" SG_ 1016 HLR_Sp_Heizung_Freigabe_BT 0;
BA_ "GenSigSendType" SG_ 1016 HLR_Sp_Heizung_Freigabe_FT 3;
BA_ "GenSigSwitchedByIgnition" SG_ 1016 HLR_Sp_Heizung_Freigabe_FT 0;
BA_ "GenSigSendType" SG_ 1016 HLR_TCH_Freigabe 3;
BA_ "GenSigSwitchedByIgnition" SG_ 1016 HLR_TCH_Freigabe 0;
BA_ "GenSigSendType" SG_ 1283 HV_Bordnetz_aktiv 3;
BA_ "GenSigSwitchedByIgnition" SG_ 1283 HV_Bordnetz_aktiv 0;
BA_ "GenSigSendType" SG_ 1283 HV_Bordnetz_Fehler 3;
BA_ "GenSigSwitchedByIgnition" SG_ 1283 HV_Bordnetz_Fehler 0;
BA_ "Fehlerwert" SG_ 1283 HV_Bordnetz_Fehler 1;
BA_ "GenSigSendType" SG_ 1283 HVK_01_BZ 0;
BA_ "GenSigFuncType" SG_ 1283 HVK_01_BZ 1;
BA_ "GenSigSwitchedByIgnition" SG_ 1283 HVK_01_BZ 0;
BA_ "GenSigSendType" SG_ 1283 HVK_01_CRC 0;
BA_ "GenSigFuncType" SG_ 1283 HVK_01_CRC 2;
BA_ "GenSigSwitchedByIgnition" SG_ 1283 HVK_01_CRC 0;
BA_ "GenSigSendType" SG_ 1283 HVK_AIAD_Sollmodus_2 3;
BA_ "GenSigSwitchedByIgnition" SG_ 1283 HVK_AIAD_Sollmodus_2 0;
BA_ "GenSigSendType" SG_ 1283 HVK_AktiveEntladung_Anf 3;
BA_ "GenSigSwitchedByIgnition" SG_ 1283 HVK_AktiveEntladung_Anf 0;
BA_ "GenSigSendType" SG_ 1283 HVK_BMS_Sollmodus 3;
BA_ "GenSigStartValue" SG_ 1283 HVK_BMS_Sollmodus 7;
BA_ "GenSigSwitchedByIgnition" SG_ 1283 HVK_BMS_Sollmodus 0;
BA_ "GenSigSendType" SG_ 1283 HVK_DCDC_EKK_Sollmodus 0;
BA_ "GenSigStartValue" SG_ 1283 HVK_DCDC_EKK_Sollmodus 3;
BA_ "GenSigSwitchedByIgnition" SG_ 1283 HVK_DCDC_EKK_Sollmodus 0;
BA_ "GenSigSendType" SG_ 1283 HVK_DCDC_Sollmodus 3;
BA_ "GenSigStartValue" SG_ 1283 HVK_DCDC_Sollmodus 7;
BA_ "GenSigSwitchedByIgnition" SG_ 1283 HVK_DCDC_Sollmodus 0;
BA_ "GenSigSendType" SG_ 1283 HVK_EKK_Sollmodus 3;
BA_ "GenSigStartValue" SG_ 1283 HVK_EKK_Sollmodus 7;
BA_ "GenSigSwitchedByIgnition" SG_ 1283 HVK_EKK_Sollmodus 0;
BA_ "GenSigSendType" SG_ 1283 HVK_Gesamtst_Spgfreiheit 0;
BA_ "GenSigSwitchedByIgnition" SG_ 1283 HVK_Gesamtst_Spgfreiheit 0;
BA_ "Fehlerwert" SG_ 1283 HVK_Gesamtst_Spgfreiheit 3;
BA_ "GenSigSendType" SG_ 1283 HVK_HV_Netz_Warnungen 3;
BA_ "GenSigSwitchedByIgnition" SG_ 1283 HVK_HV_Netz_Warnungen 0;
BA_ "GenSigSendType" SG_ 1283 HVK_HVLM_Sollmodus 3;
BA_ "GenSigStartValue" SG_ 1283 HVK_HVLM_Sollmodus 7;
BA_ "GenSigSwitchedByIgnition" SG_ 1283 HVK_HVLM_Sollmodus 0;
BA_ "GenSigSendType" SG_ 1283 HVK_HVPTC_Sollmodus 3;
BA_ "GenSigStartValue" SG_ 1283 HVK_HVPTC_Sollmodus 7;
BA_ "GenSigSwitchedByIgnition" SG_ 1283 HVK_HVPTC_Sollmodus 0;
BA_ "GenSigSendType" SG_ 1283 HVK_Iso_Fehlerstatus 0;
BA_ "GenSigSwitchedByIgnition" SG_ 1283 HVK_Iso_Fehlerstatus 0;
BA_ "Fehlerwert" SG_ 1283 HVK_Iso_Fehlerstatus 1;
BA_ "GenSigSendType" SG_ 1283 HVK_Iso_Messung_Start 3;
BA_ "GenSigSwitchedByIgnition" SG_ 1283 HVK_Iso_Messung_Start 0;
BA_ "GenSigSendType" SG_ 1283 HVK_Istmodus_Anf 3;
BA_ "GenSigSwitchedByIgnition" SG_ 1283 HVK_Istmodus_Anf 0;
BA_ "GenSigSendType" SG_ 1283 HVK_MO_EmSollzustand 3;
BA_ "GenSigStartValue" SG_ 1283 HVK_MO_EmSollzustand 255;
BA_ "GenSigSwitchedByIgnition" SG_ 1283 HVK_MO_EmSollzustand 0;
BA_ "GenSigSendType" SG_ 1283 HVK_TN1_Sollmodus 3;
BA_ "GenSigStartValue" SG_ 1283 HVK_TN1_Sollmodus 3;
BA_ "GenSigSwitchedByIgnition" SG_ 1283 HVK_TN1_Sollmodus 0;
BA_REL_ "GenSigTimeoutTime" BU_SG_REL_ BCM1 SG_ 259 ESP_VL_FR 500;
BA_REL_ "GenSigTimeoutTime" BU_SG_REL_ BCM1 SG_ 259 ESP_VR_FR 500;
BA_REL_ "GenSigTimeoutTime" BU_SG_REL_ BCM1 SG_ 259 ESP_HL_FR 500;
BA_REL_ "GenSigTimeoutTime" BU_SG_REL_ BCM1 SG_ 259 ESP_HR_FR 500;
BA_REL_ "GenSigTimeoutTime" BU_SG_REL_ BCM1 SG_ 259 ESP_VL_Radgeschw 500;
BA_REL_ "GenSigTimeoutTime" BU_SG_REL_ BCM1 SG_ 259 ESP_VR_Radgeschw 500;
BA_REL_ "GenSigTimeoutTime" BU_SG_REL_ BCM1 SG_ 259 ESP_HL_Radgeschw 500;
BA_REL_ "GenSigTimeoutTime" BU_SG_REL_ BCM1 SG_ 259 ESP_HR_Radgeschw 500;
BA_REL_ "GenSigTimeoutTime" BU_SG_REL_ BCM1 SG_ 914 ESP_Codierung_ADS 800;
BA_REL_ "GenSigTimeoutTime" BU_SG_REL_ BCM1 SG_ 914 ESP_Rollenmodus_Deaktivieren 800;
BA_REL_ "GenSigTimeoutTime" BU_SG_REL_ BCM1 SG_ 278 ESP_10_CRC 500;
BA_REL_ "GenSigTimeoutTime" BU_SG_REL_ BCM1 SG_ 278 ESP_10_BZ 500;
BA_REL_ "GenSigTimeoutTime" BU_SG_REL_ BCM1 SG_ 278 ESP_QBit_Wegimpuls_VL 500;
BA_REL_ "GenSigTimeoutTime" BU_SG_REL_ BCM1 SG_ 278 ESP_QBit_Wegimpuls_VR 500;
BA_REL_ "GenSigTimeoutTime" BU_SG_REL_ BCM1 SG_ 278 ESP_QBit_Wegimpuls_HL 500;
BA_REL_ "GenSigTimeoutTime" BU_SG_REL_ BCM1 SG_ 278 ESP_QBit_Wegimpuls_HR 500;
BA_REL_ "GenSigTimeoutTime" BU_SG_REL_ BCM1 SG_ 278 ESP_Wegimpuls_VL 500;
BA_REL_ "GenSigTimeoutTime" BU_SG_REL_ BCM1 SG_ 278 ESP_Wegimpuls_VR 500;
BA_REL_ "GenSigTimeoutTime" BU_SG_REL_ BCM1 SG_ 278 ESP_Wegimpuls_HL 500;
BA_REL_ "GenSigTimeoutTime" BU_SG_REL_ BCM1 SG_ 278 ESP_Wegimpuls_HR 500;
BA_REL_ "GenSigTimeoutTime" BU_SG_REL_ BCM1 SG_ 278 ESP_VL_Fahrtrichtung 500;
BA_REL_ "GenSigTimeoutTime" BU_SG_REL_ BCM1 SG_ 278 ESP_VR_Fahrtrichtung 500;
BA_REL_ "GenSigTimeoutTime" BU_SG_REL_ BCM1 SG_ 278 ESP_HL_Fahrtrichtung 500;
BA_REL_ "GenSigTimeoutTime" BU_SG_REL_ BCM1 SG_ 278 ESP_HR_Fahrtrichtung 500;
BA_REL_ "GenSigTimeoutTime" BU_SG_REL_ BCM1 SG_ 418 HMS_Konsistenz_IPA 2000;
BA_REL_ "GenSigTimeoutTime" BU_SG_REL_ BCM1 SG_ 418 VZM_Status 2000;
BA_REL_ "GenSigTimeoutTime" BU_SG_REL_ BCM1 SG_ 418 HMS_Systemstatus 2000;
BA_REL_ "GenSigTimeoutTime" BU_SG_REL_ BCM1 SG_ 418 HMS_Stillstand 2000;
BA_REL_ "GenSigTimeoutTime" BU_SG_REL_ BCM1 SG_ 418 HMS_aktives_System 2000;
BA_REL_ "GenSigTimeoutTime" BU_SG_REL_ BCM1 SG_ 418 HMS_Fehlerstatus 2000;
BA_REL_ "GenSigTimeoutTime" BU_SG_REL_ BCM1 SG_ 253 ESP_21_CRC 500;
BA_REL_ "GenSigTimeoutTime" BU_SG_REL_ BCM1 SG_ 253 ESP_21_BZ 500;
BA_REL_ "GenSigTimeoutTime" BU_SG_REL_ BCM1 SG_ 253 BR_Eingriffsmoment 500;
BA_REL_ "GenSigTimeoutTime" BU_SG_REL_ BCM1 SG_ 253 ESP_Diagnose 500;
BA_REL_ "GenSigTimeoutTime" BU_SG_REL_ BCM1 SG_ 253 ESC_v_Signal_Qualifier_High_Low 500;
BA_REL_ "GenSigTimeoutTime" BU_SG_REL_ BCM1 SG_ 253 ESP_Vorsteuerung 500;
BA_REL_ "GenSigTimeoutTime" BU_SG_REL_ BCM1 SG_ 253 OBD_Schlechtweg 500;
BA_REL_ "GenSigTimeoutTime" BU_SG_REL_ BCM1 SG_ 253 OBD_QBit_Schlechtweg 500;
BA_REL_ "GenSigTimeoutTime" BU_SG_REL_ BCM1 SG_ 253 ESP_v_Signal 500;
BA_REL_ "GenSigTimeoutTime" BU_SG_REL_ BCM1 SG_ 253 ASR_Tastung_passiv 500;
BA_REL_ "GenSigTimeoutTime" BU_SG_REL_ BCM1 SG_ 253 ESP_Tastung_passiv 500;
BA_REL_ "GenSigTimeoutTime" BU_SG_REL_ BCM1 SG_ 253 ESP_Systemstatus 500;
BA_REL_ "GenSigTimeoutTime" BU_SG_REL_ BCM1 SG_ 253 ASR_Schalteingriff 500;
BA_REL_ "GenSigTimeoutTime" BU_SG_REL_ BCM1 SG_ 253 ESP_QBit_v_Signal 500;
BA_REL_ "GenSigTimeoutTime" BU_SG_REL_ BCM1 SG_ 253 ABS_Bremsung 500;
BA_REL_ "GenSigTimeoutTime" BU_SG_REL_ BCM1 SG_ 253 ASR_Anf 500;
BA_REL_ "GenSigTimeoutTime" BU_SG_REL_ BCM1 SG_ 253 MSR_Anf 500;
BA_REL_ "GenSigTimeoutTime" BU_SG_REL_ BCM1 SG_ 253 EBV_Eingriff 500;
BA_REL_ "GenSigTimeoutTime" BU_SG_REL_ BCM1 SG_ 253 EDS_Eingriff 500;
BA_REL_ "GenSigTimeoutTime" BU_SG_REL_ BCM1 SG_ 253 ESP_Eingriff 500;
BA_REL_ "GenSigTimeoutTime" BU_SG_REL_ BCM1 SG_ 253 ESP_ASP 500;
BA_REL_ "GenSigTimeoutTime" BU_SG_REL_ BCM1 SG_ 508 ESP_Stillstandsflag 1000;
BA_REL_ "GenSigTimeoutTime" BU_SG_REL_ BCM1 SG_ 508 ESP_AVH_LED 1000;
BA_REL_ "GenSigTimeoutTime" BU_SG_REL_ BCM1 SG_ 508 ESP_HDC_LED 1000;
BA_REL_ "GenSigTimeoutTime" BU_SG_REL_ BCM1 SG_ 508 ESP_Off_LED 1000;
BA_REL_ "GenSigTimeoutTime" BU_SG_REL_ BCM1 SG_ 427 ESC_AHW_aktiv 2000;
BA_REL_ "GenSigTimeoutTime" BU_SG_REL_ BCM1 SG_ 427 ESC_AHW_nicht_verfuegbar 2000;
BA_REL_ "GenSigTimeoutTime" BU_SG_REL_ BCM1 SG_ 427 ESC_Verz_Reg_aktiv 2000;
BA_REL_ "GenSigTimeoutTime" BU_SG_REL_ BCM1 SG_ 427 ESC_Verz_Reg_nicht_verfuegbar 2000;
BA_REL_ "GenSigTimeoutTime" BU_SG_REL_ BCM1 SG_ 427 ESC_Verz_Reg_TB_nicht_verfuegbar 2000;
BA_REL_ "GenSigTimeoutTime" BU_SG_REL_ BCM1 SG_ 427 ESC_Verz_Reg_ZB_nicht_verfuegbar 2000;
BA_REL_ "GenSigTimeoutTime" BU_SG_REL_ BCM1 SG_ 427 ESC_Konsistenz_ARA 2000;
BA_REL_ "GenSigTimeoutTime" BU_SG_REL_ BCM1 SG_ 427 ESC_Konsistenz_IPA 2000;
BA_REL_ "GenSigTimeoutTime" BU_SG_REL_ BCM1 SG_ 427 ESC_Fahrer_Bremsdruck_bestimmend 2000;
BA_REL_ "GenSigTimeoutTime" BU_SG_REL_ BCM1 SG_ 427 ESC_Verz_ASIL_Verfuegbarkeit 2000;
BA_REL_ "GenSigTimeoutTime" BU_SG_REL_ BCM1 SG_ 264 FA_Hoehenwerte_kalibriert 500;
BA_REL_ "GenSigTimeoutTime" BU_SG_REL_ BCM1 SG_ 264 FA_Hoehenwert_VL_00 500;
BA_REL_ "GenSigTimeoutTime" BU_SG_REL_ BCM1 SG_ 264 FA_Hoehenwert_HL_00 500;
BA_REL_ "GenSigTimeoutTime" BU_SG_REL_ BCM1 SG_ 429 NR_Reglerstatus 5000;
BA_REL_ "GenSigTimeoutTime" BU_SG_REL_ BCM1 SG_ 429 NR_LED_SGN 5000;
BA_REL_ "GenSigTimeoutTime" BU_SG_REL_ BCM1 SG_ 429 NR_LED_TN 5000;
BA_REL_ "GenSigTimeoutTime" BU_SG_REL_ BCM1 SG_ 429 NR_LED_BN 5000;
BA_REL_ "GenSigTimeoutTime" BU_SG_REL_ BCM1 SG_ 429 NR_LED_HN 5000;
BA_REL_ "GenSigTimeoutTime" BU_SG_REL_ BCM1 SG_ 1605 FLA_aktiv 5000;
BA_REL_ "GenSigTimeoutTime" BU_SG_REL_ BCM1 SG_ 1605 FLA_ISP_defekt 5000;
BA_REL_ "GenSigTimeoutTime" BU_SG_REL_ BCM1 SG_ 1605 FLA_Sensor_blockiert 5000;
BA_REL_ "GenSigTimeoutTime" BU_SG_REL_ BCM1 SG_ 1605 FLA_Fernlicht_PWM 5000;
BA_REL_ "GenSigTimeoutTime" BU_SG_REL_ BCM1 SG_ 1605 FLA_Aufblenden 5000;
BA_REL_ "GenSigTimeoutTime" BU_SG_REL_ BCM1 SG_ 2589283684 FoD_Transmission_Info 5000;
BA_REL_ "GenSigTimeoutTime" BU_SG_REL_ BCM1 SG_ 1523 I_Heiz_Frontscheibe 2000;
BA_REL_ "GenSigTimeoutTime" BU_SG_REL_ BCM1 SG_ 173 GE_Fahrstufe 1000;
BA_REL_ "GenSigTimeoutTime" BU_SG_REL_ BCM1 SG_ 173 GE_Zielgang 1000;
BA_REL_ "GenSigTimeoutTime" BU_SG_REL_ BCM1 SG_ 177 GE_Freilauf_Status 5000;
BA_REL_ "GenSigTimeoutTime" BU_SG_REL_ BCM1 SG_ 310 HAL_01_CRC 500;
BA_REL_ "GenSigTimeoutTime" BU_SG_REL_ BCM1 SG_ 310 HAL_01_BZ 500;
BA_REL_ "GenSigTimeoutTime" BU_SG_REL_ BCM1 SG_ 310 HAL_Status 500;
BA_REL_ "GenSigTimeoutTime" BU_SG_REL_ BCM1 SG_ 310 HAL_VZ_Radwinkel 500;
BA_REL_ "GenSigTimeoutTime" BU_SG_REL_ BCM1 SG_ 310 HAL_QBit_Radwinkel 500;
BA_REL_ "GenSigTimeoutTime" BU_SG_REL_ BCM1 SG_ 310 HAL_Radwinkel 500;
BA_REL_ "GenSigTimeoutTime" BU_SG_REL_ BCM1 SG_ 310 HAL_VZ_Fahrerwunschwinkel_Soll 500;
BA_REL_ "GenSigTimeoutTime" BU_SG_REL_ BCM1 SG_ 310 HAL_Fahrerwunschwinkel_Soll 500;
BA_REL_ "GenSigTimeoutTime" BU_SG_REL_ BCM1 SG_ 310 HAL_max_Gradient 500;
BA_REL_ "GenSigTimeoutTime" BU_SG_REL_ BCM1 SG_ 676 HAL_02_CRC 500;
BA_REL_ "GenSigTimeoutTime" BU_SG_REL_ BCM1 SG_ 676 HAL_02_BZ 500;
BA_REL_ "GenSigTimeoutTime" BU_SG_REL_ BCM1 SG_ 676 HAL_ARA_Status 500;
BA_REL_ "GenSigTimeoutTime" BU_SG_REL_ BCM1 SG_ 676 HAL_PLA_Status 500;
BA_REL_ "GenSigTimeoutTime" BU_SG_REL_ BCM1 SG_ 676 HAL_PWR_Abbruch 500;
BA_REL_ "GenSigTimeoutTime" BU_SG_REL_ BCM1 SG_ 676 HAL_PWR_Fehler 500;
BA_REL_ "GenSigTimeoutTime" BU_SG_REL_ BCM1 SG_ 1410 HD_Endstellung_oben 2000;
BA_REL_ "GenSigTimeoutTime" BU_SG_REL_ BCM1 SG_ 1410 HD_Endstellung_unten 2000;
BA_REL_ "GenSigTimeoutTime" BU_SG_REL_ BCM1 SG_ 1410 HD_Bewegung_zu 2000;
BA_REL_ "GenSigTimeoutTime" BU_SG_REL_ BCM1 SG_ 1410 HD_Position 2000;
BA_REL_ "GenSigTimeoutTime" BU_SG_REL_ BCM1 SG_ 1016 HLR_FlHz_Freigabe_Ruhesitz 5000;
BA_REL_ "GenSigTimeoutTime" BU_SG_REL_ BCM1 SG_ 1016 HLR_FlHz_Freigabe_VR 5000;
BA_REL_ "GenSigTimeoutTime" BU_SG_REL_ BCM1 SG_ 1016 HLR_FlHz_Freigabe_VL 5000;
BA_REL_ "GenSigTimeoutTime" BU_SG_REL_ BCM1 SG_ 1016 HLR_FlHz_Freigabe_HR 5000;
BA_REL_ "GenSigTimeoutTime" BU_SG_REL_ BCM1 SG_ 1016 HLR_FlHz_Freigabe_HL 5000;
BA_REL_ "GenSigTimeoutTime" BU_SG_REL_ BCM1 SG_ 1016 HLR_TCH_Freigabe 5000;
BA_REL_ "GenSigTimeoutTime" BU_SG_REL_ BCM1 SG_ 1016 HLR_SIH_Freigabe_Fond 5000;
BA_REL_ "GenSigTimeoutTime" BU_SG_REL_ BCM1 SG_ 1016 HLR_KRH_Freigabe_VL 5000;
BA_REL_ "GenSigTimeoutTime" BU_SG_REL_ BCM1 SG_ 1016 HLR_KRH_Freigabe_VR 5000;
BA_REL_ "GenSigTimeoutTime" BU_SG_REL_ BCM1 SG_ 1016 HLR_SIH_Freigabe_VL 5000;
BA_REL_ "GenSigTimeoutTime" BU_SG_REL_ BCM1 SG_ 1016 HLR_SIH_Freigabe_VR 5000;
BA_REL_ "GenSigTimeoutTime" BU_SG_REL_ BCM1 SG_ 1016 HLR_SIH_Freigabe_HL 5000;
BA_REL_ "GenSigTimeoutTime" BU_SG_REL_ BCM1 SG_ 1016 HLR_SIH_Freigabe_HR 5000;
BA_REL_ "GenSigTimeoutTime" BU_SG_REL_ BCM1 SG_ 1016 HLR_SIL_Freigabe_VL 5000;
BA_REL_ "GenSigTimeoutTime" BU_SG_REL_ BCM1 SG_ 1016 HLR_SIL_Freigabe_VR 5000;
BA_REL_ "GenSigTimeoutTime" BU_SG_REL_ BCM1 SG_ 1016 HLR_SIL_Freigabe_HL 5000;
BA_REL_ "GenSigTimeoutTime" BU_SG_REL_ BCM1 SG_ 1016 HLR_SIL_Freigabe_HR 5000;
BA_REL_ "GenSigTimeoutTime" BU_SG_REL_ BCM1 SG_ 1016 HLR_FSH_Freigabe 5000;
BA_REL_ "GenSigTimeoutTime" BU_SG_REL_ BCM1 SG_ 1016 HLR_PTC_linear_Freigabe 5000;
BA_REL_ "GenSigTimeoutTime" BU_SG_REL_ BCM1 SG_ 1016 HLR_PTC_Freigabe 5000;
BA_REL_ "GenSigTimeoutTime" BU_SG_REL_ BCM1 SG_ 1283 HVK_HVPTC_Sollmodus 1000;
BA_REL_ "GenSigTimeoutTime" BU_SG_REL_ Gateway SG_ 1416 SIH_Stufe_LED_li 5000;
BA_REL_ "GenSigTimeoutTime" BU_SG_REL_ Gateway SG_ 1416 SIH_Stufe_LED_re 5000;
BA_REL_ "GenSigTimeoutTime" BU_SG_REL_ Gateway SG_ 1416 SIL_Stufe_LED_li 5000;
BA_REL_ "GenSigTimeoutTime" BU_SG_REL_ Gateway SG_ 1416 SIL_Stufe_LED_re 5000;
BA_REL_ "GenSigTimeoutTime" BU_SG_REL_ Gateway SG_ 1416 KRH_Stufe_LED_li 5000;
BA_REL_ "GenSigTimeoutTime" BU_SG_REL_ Gateway SG_ 1416 KRH_Stufe_LED_re 5000;
BA_REL_ "GenSigTimeoutTime" BU_SG_REL_ Gateway SG_ 1416 BCM1_TCH_HLR_Anf 5000;
BA_REL_ "GenSigTimeoutTime" BU_SG_REL_ Gateway SG_ 1416 SIL_Stufe_LED_HL 5000;
BA_REL_ "GenSigTimeoutTime" BU_SG_REL_ Gateway SG_ 1416 SIL_Stufe_LED_HR 5000;
BA_REL_ "GenSigTimeoutTime" BU_SG_REL_ Gateway SG_ 1416 SIH_Stufe_LED_HL 5000;
BA_REL_ "GenSigTimeoutTime" BU_SG_REL_ Gateway SG_ 1416 SIH_Stufe_LED_HR 5000;
BA_REL_ "GenSigTimeoutTime" BU_SG_REL_ Gateway_PAG SG_ 1416 SIH_Stufe_LED_li 5000;
BA_REL_ "GenSigTimeoutTime" BU_SG_REL_ Gateway_PAG SG_ 1416 SIH_Stufe_LED_re 5000;
BA_REL_ "GenSigTimeoutTime" BU_SG_REL_ Gateway_PAG SG_ 1416 SIL_Stufe_LED_li 5000;
BA_REL_ "GenSigTimeoutTime" BU_SG_REL_ Gateway_PAG SG_ 1416 SIL_Stufe_LED_re 5000;
BA_REL_ "GenSigTimeoutTime" BU_SG_REL_ Gateway_PAG SG_ 1416 KRH_Stufe_LED_li 5000;
BA_REL_ "GenSigTimeoutTime" BU_SG_REL_ Gateway_PAG SG_ 1416 KRH_Stufe_LED_re 5000;
BA_REL_ "GenSigTimeoutTime" BU_SG_REL_ Gateway_PAG SG_ 1416 BCM1_TCH_HLR_Anf 5000;
BA_REL_ "GenSigTimeoutTime" BU_SG_REL_ Gateway_PAG SG_ 1416 SIL_Stufe_LED_HL 5000;
BA_REL_ "GenSigTimeoutTime" BU_SG_REL_ Gateway_PAG SG_ 1416 SIL_Stufe_LED_HR 5000;
BA_REL_ "GenSigTimeoutTime" BU_SG_REL_ Gateway_PAG SG_ 1416 SIH_Stufe_LED_HL 5000;
BA_REL_ "GenSigTimeoutTime" BU_SG_REL_ Gateway_PAG SG_ 1416 SIH_Stufe_LED_HR 5000;
BA_REL_ "GenSigTimeoutTime" BU_SG_REL_ Klima_MSB SG_ 914 ESP_Rollenmodus_Deaktivieren 800;
BA_REL_ "GenSigTimeoutTime" BU_SG_REL_ Klima_MSB SG_ 253 ESP_v_Signal 500;
BA_REL_ "GenSigTimeoutTime" BU_SG_REL_ Klima_MSB SG_ 253 ESP_QBit_v_Signal 500;
BA_REL_ "GenSigTimeoutTime" BU_SG_REL_ Klima_MSB SG_ 1523 P_Heiz_Frontscheibe 2000;
BA_REL_ "GenSigTimeoutTime" BU_SG_REL_ Klima_MSB SG_ 177 GE_Freilauf_Status 5000;
BA_REL_ "GenSigTimeoutTime" BU_SG_REL_ Klima_MSB SG_ 1410 HD_Bewegung_zu 2000;
BA_REL_ "GenSigTimeoutTime" BU_SG_REL_ Klima_MSB SG_ 1410 HD_Position 2000;
BA_REL_ "GenSigTimeoutTime" BU_SG_REL_ Klima_MSB SG_ 1416 SIH_Stufe_LED_li 5000;
BA_REL_ "GenSigTimeoutTime" BU_SG_REL_ Klima_MSB SG_ 1416 SIH_Stufe_LED_re 5000;
BA_REL_ "GenSigTimeoutTime" BU_SG_REL_ Klima_MSB SG_ 1416 SIL_Stufe_LED_li 5000;
BA_REL_ "GenSigTimeoutTime" BU_SG_REL_ Klima_MSB SG_ 1416 SIL_Stufe_LED_re 5000;
BA_REL_ "GenSigTimeoutTime" BU_SG_REL_ Klima_MSB SG_ 1416 KRH_Stufe_LED_li 5000;
BA_REL_ "GenSigTimeoutTime" BU_SG_REL_ Klima_MSB SG_ 1416 KRH_Stufe_LED_re 5000;
BA_REL_ "GenSigTimeoutTime" BU_SG_REL_ Klima_MSB SG_ 1416 SIL_Stufe_LED_HL 5000;
BA_REL_ "GenSigTimeoutTime" BU_SG_REL_ Klima_MSB SG_ 1416 SIL_Stufe_LED_HR 5000;
BA_REL_ "GenSigTimeoutTime" BU_SG_REL_ Klima_MSB SG_ 1416 SIH_Stufe_LED_HL 5000;
BA_REL_ "GenSigTimeoutTime" BU_SG_REL_ Klima_MSB SG_ 1416 SIH_Stufe_LED_HR 5000;
BA_REL_ "GenSigTimeoutTime" BU_SG_REL_ Klima_MSB SG_ 1016 HLR_FlHz_Freigabe_VR 5000;
BA_REL_ "GenSigTimeoutTime" BU_SG_REL_ Klima_MSB SG_ 1016 HLR_FlHz_Freigabe_VL 5000;
BA_REL_ "GenSigTimeoutTime" BU_SG_REL_ Klima_MSB SG_ 1016 HLR_FlHz_Freigabe_HR 5000;
BA_REL_ "GenSigTimeoutTime" BU_SG_REL_ Klima_MSB SG_ 1016 HLR_FlHz_Freigabe_HL 5000;
BA_REL_ "GenSigTimeoutTime" BU_SG_REL_ Klima_MSB SG_ 1016 HLR_SIH_Freigabe_VL 5000;
BA_REL_ "GenSigTimeoutTime" BU_SG_REL_ Klima_MSB SG_ 1016 HLR_SIH_Freigabe_VR 5000;
BA_REL_ "GenSigTimeoutTime" BU_SG_REL_ Klima_MSB SG_ 1016 HLR_SIH_Freigabe_HL 5000;
BA_REL_ "GenSigTimeoutTime" BU_SG_REL_ Klima_MSB SG_ 1016 HLR_SIH_Freigabe_HR 5000;
BA_REL_ "GenSigTimeoutTime" BU_SG_REL_ Klima_MSB SG_ 1016 HLR_SIL_Freigabe_VL 5000;
BA_REL_ "GenSigTimeoutTime" BU_SG_REL_ Klima_MSB SG_ 1016 HLR_SIL_Freigabe_VR 5000;
BA_REL_ "GenSigTimeoutTime" BU_SG_REL_ Klima_MSB SG_ 1016 HLR_SIL_Freigabe_HL 5000;
BA_REL_ "GenSigTimeoutTime" BU_SG_REL_ Klima_MSB SG_ 1016 HLR_SIL_Freigabe_HR 5000;
BA_REL_ "GenSigTimeoutTime" BU_SG_REL_ Klima_MSB SG_ 1016 HLR_FSH_Freigabe 5000;
BA_REL_ "GenSigTimeoutTime" BU_SG_REL_ Klima_MSB SG_ 1016 HLR_PTC_linear_Freigabe 5000;
BA_REL_ "GenSigTimeoutTime" BU_SG_REL_ Klima_MSB SG_ 1283 HVK_HVPTC_Sollmodus 1000;
BA_REL_ "GenSigTimeoutTime" BU_SG_REL_ Lift_VA SG_ 253 ESP_v_Signal 500;
BA_REL_ "GenSigTimeoutTime" BU_SG_REL_ Lift_VA SG_ 264 FA_Hoehenwerte_kalibriert 500;
BA_REL_ "GenSigTimeoutTime" BU_SG_REL_ Lift_VA SG_ 264 FA_Hoehenwert_VL_00 500;
BA_REL_ "GenSigTimeoutTime" BU_SG_REL_ Lift_VA SG_ 264 FA_Hoehenwert_VR_00 500;
BA_REL_ "GenSigTimeoutTime" BU_SG_REL_ Lift_VA SG_ 264 FA_Hoehenwert_HL_00 500;
BA_REL_ "GenSigTimeoutTime" BU_SG_REL_ Lift_VA SG_ 264 FA_Hoehenwert_HR_00 500;
BA_REL_ "GenSigTimeoutTime" BU_SG_REL_ Lift_VA SG_ 173 GE_Fahrstufe 1000;
BA_REL_ "GenSigTimeoutTime" BU_SG_REL_ VAS_L SG_ 253 ESP_v_Signal 500;
BA_REL_ "GenSigTimeoutTime" BU_SG_REL_ VAS_L SG_ 253 ESP_QBit_v_Signal 500;
BA_REL_ "GenSigTimeoutTime" BU_SG_REL_ VAS_L SG_ 1470 ESP_Gierrate_Offset_2 3200;
BA_REL_ "GenSigTimeoutTime" BU_SG_REL_ VAS_L SG_ 264 FA_Hoehenwerte_kalibriert 500;
BA_REL_ "GenSigTimeoutTime" BU_SG_REL_ VAS_L SG_ 264 FA_Hoehenwert_VL_00 500;
BA_REL_ "GenSigTimeoutTime" BU_SG_REL_ VAS_L SG_ 264 FA_Hoehenwert_VR_00 500;
BA_REL_ "GenSigTimeoutTime" BU_SG_REL_ VAS_L SG_ 264 FA_Hoehenwert_HL_00 500;
BA_REL_ "GenSigTimeoutTime" BU_SG_REL_ VAS_L SG_ 264 FA_Hoehenwert_HR_00 500;
BA_REL_ "GenSigTimeoutTime" BU_SG_REL_ VAS_L SG_ 852 FB_Kopf_erkannt 800;
BA_REL_ "GenSigTimeoutTime" BU_SG_REL_ VAS_L SG_ 2527679660 FB_NichtVerfuegbar 3200;
BA_REL_ "GenSigTimeoutTime" BU_SG_REL_ VAS_L SG_ 853 FB_Kopfrotation_Roll_Guete 800;
BA_REL_ "GenSigTimeoutTime" BU_SG_REL_ VAS_L SG_ 853 FB_Kopfrotation_Roll 800;
BA_REL_ "GenSigTimeoutTime" BU_SG_REL_ VAS_L SG_ 853 FB_Kopfrotation_Nick 800;
BA_REL_ "GenSigTimeoutTime" BU_SG_REL_ VAS_L SG_ 853 FB_Kopfrotation_Nick_Guete 800;
BA_REL_ "GenSigTimeoutTime" BU_SG_REL_ VAS_L SG_ 854 FB_Kopfrotation_Gier_Guete 800;
BA_REL_ "GenSigTimeoutTime" BU_SG_REL_ VAS_L SG_ 854 FB_Kopfposition_Z_Guete 800;
BA_REL_ "GenSigTimeoutTime" BU_SG_REL_ VAS_L SG_ 854 FB_Kopfposition_Y_Guete 800;
BA_REL_ "GenSigTimeoutTime" BU_SG_REL_ VAS_L SG_ 854 FB_Kopfposition_X_Guete 800;
BA_REL_ "GenSigTimeoutTime" BU_SG_REL_ VAS_L SG_ 854 FB_Kopfrotation_Gier 800;
BA_REL_ "GenSigTimeoutTime" BU_SG_REL_ VAS_L SG_ 854 FB_Kopfposition_Z 800;
BA_REL_ "GenSigTimeoutTime" BU_SG_REL_ VAS_L SG_ 854 FB_Kopfposition_Y 800;
BA_REL_ "GenSigTimeoutTime" BU_SG_REL_ VAS_L SG_ 854 FB_Kopfposition_X 800;
BA_REL_ "GenSigTimeoutTime" BU_SG_REL_ VAS_R SG_ 253 ESP_v_Signal 500;
BA_REL_ "GenSigTimeoutTime" BU_SG_REL_ VAS_R SG_ 253 ESP_QBit_v_Signal 500;
BA_REL_ "GenSigTimeoutTime" BU_SG_REL_ VAS_R SG_ 1470 ESP_Gierrate_Offset_2 3200;
BA_REL_ "GenSigTimeoutTime" BU_SG_REL_ VAS_R SG_ 264 FA_Hoehenwerte_kalibriert 500;
BA_REL_ "GenSigTimeoutTime" BU_SG_REL_ VAS_R SG_ 264 FA_Hoehenwert_VL_00 500;
BA_REL_ "GenSigTimeoutTime" BU_SG_REL_ VAS_R SG_ 264 FA_Hoehenwert_VR_00 500;
BA_REL_ "GenSigTimeoutTime" BU_SG_REL_ VAS_R SG_ 264 FA_Hoehenwert_HL_00 500;
BA_REL_ "GenSigTimeoutTime" BU_SG_REL_ VAS_R SG_ 264 FA_Hoehenwert_HR_00 500;
BA_REL_ "GenSigTimeoutTime" BU_SG_REL_ VAS_R SG_ 852 FB_Kopf_erkannt 800;
BA_REL_ "GenSigTimeoutTime" BU_SG_REL_ VAS_R SG_ 2527679660 FB_NichtVerfuegbar 3200;
BA_REL_ "GenSigTimeoutTime" BU_SG_REL_ VAS_R SG_ 853 FB_Kopfrotation_Roll_Guete 800;
BA_REL_ "GenSigTimeoutTime" BU_SG_REL_ VAS_R SG_ 853 FB_Kopfrotation_Roll 800;
BA_REL_ "GenSigTimeoutTime" BU_SG_REL_ VAS_R SG_ 853 FB_Kopfrotation_Nick 800;
BA_REL_ "GenSigTimeoutTime" BU_SG_REL_ VAS_R SG_ 853 FB_Kopfrotation_Nick_Guete 800;
BA_REL_ "GenSigTimeoutTime" BU_SG_REL_ VAS_R SG_ 854 FB_Kopfrotation_Gier_Guete 800;
BA_REL_ "GenSigTimeoutTime" BU_SG_REL_ VAS_R SG_ 854 FB_Kopfposition_Z_Guete 800;
BA_REL_ "GenSigTimeoutTime" BU_SG_REL_ VAS_R SG_ 854 FB_Kopfposition_Y_Guete 800;
BA_REL_ "GenSigTimeoutTime" BU_SG_REL_ VAS_R SG_ 854 FB_Kopfposition_X_Guete 800;
BA_REL_ "GenSigTimeoutTime" BU_SG_REL_ VAS_R SG_ 854 FB_Kopfrotation_Gier 800;
BA_REL_ "GenSigTimeoutTime" BU_SG_REL_ VAS_R SG_ 854 FB_Kopfposition_Z 800;
BA_REL_ "GenSigTimeoutTime" BU_SG_REL_ VAS_R SG_ 854 FB_Kopfposition_Y 800;
BA_REL_ "GenSigTimeoutTime" BU_SG_REL_ VAS_R SG_ 854 FB_Kopfposition_X 800;
VAL_ 259 ESP_VL_FR 0 "Vorwaerts" 1 "Rueckwaerts" ;
VAL_ 259 ESP_VR_FR 0 "Vorwaerts" 1 "Rueckwaerts" ;
VAL_ 259 ESP_HL_FR 0 "Vorwaerts" 1 "Rueckwaerts" ;
VAL_ 259 ESP_HR_FR 0 "Vorwaerts" 1 "Rueckwaerts" ;
VAL_ 259 ESP_VL_Radgeschw 4093 "Unterspannung" 4094 "Init" 4095 "Fehler" ;
VAL_ 259 ESP_VR_Radgeschw 4093 "Unterspannung" 4094 "Init" 4095 "Fehler" ;
VAL_ 259 ESP_HL_Radgeschw 4093 "Unterspannung" 4094 "Init" 4095 "Fehler" ;
VAL_ 259 ESP_HR_Radgeschw 4093 "Unterspannung" 4094 "Init" 4095 "Fehler" ;
VAL_ 914 ESP_Allrad_Antrieb 0 "Front" 1 "Allrad" ;
VAL_ 914 ESP_Codierung_ADS 0 "Init" 1 "ESP_nicht_ADS_codiert" 2 "ADS_codiert" 3 "tbd" ;
VAL_ 914 ESP_RTA_HL 254 "Abgleich_nocht_nicht_genuegend_konvergent" 255 "Fehler" ;
VAL_ 914 ESP_RTA_HR 254 "Abgleich_nocht_nicht_genuegend_konvergent" 255 "Fehler" ;
VAL_ 914 ESP_RTA_VR 254 "Abgleich_nocht_nicht_genuegend_konvergent" 255 "Fehler" ;
VAL_ 914 OBD_Fehler_Radsensor_HL 0 "kein Fehler / Init / nicht verbaut" 1 "KS- (Kurzschluss nach minus)" 2 "KS+ (Kurzschluss nach plus)" 3 "OC (Leitungsunterbrechung)" 4 "OOR+ (Signal zu gross)" 5 "OOR- (Signal zu klein)" 6 "RC+ (Signal unplausibel zu gross)" 7 "RC- (Signal unplausibel zu klein)" 8 "KS+/OC (Kurzschluss nach plus/Unterbrechung)" 9 "KS-/OC  (Kurzschluss nach minus/Unterbrechung)" 10 "KS-/KS+  (Kurzschluss nach minus/plus)" 11 "KS-/KS+/OC (Kurzschluss nach minus/plus/Unterbrechung)" 12 "frei" 13 "frei" 14 "frei" 15 "frei" ;
VAL_ 914 OBD_Fehler_Radsensor_HR 0 "kein Fehler / Init / nicht verbaut" 1 "KS- (Kurzschluss nach minus)" 2 "KS+ (Kurzschluss nach plus)" 3 "OC (Leitungsunterbrechung)" 4 "OOR+ (Signal zu gross)" 5 "OOR- (Signal zu klein)" 6 "RC+ (Signal unplausibel zu gross)" 7 "RC- (Signal unplausibel zu klein)" 8 "KS+/OC (Kurzschluss nach plus/Unterbrechung)" 9 "KS-/OC  (Kurzschluss nach minus/Unterbrechung)" 10 "KS-/KS+  (Kurzschluss nach minus/plus)" 11 "KS-/KS+/OC (Kurzschluss nach minus/plus/Unterbrechung)" 12 "frei" 13 "frei" 14 "frei" 15 "frei" ;
VAL_ 914 OBD_Fehler_Radsensor_VL 0 "kein Fehler / Init / nicht verbaut" 1 "KS- (Kurzschluss nach minus)" 2 "KS+ (Kurzschluss nach plus)" 3 "OC (Leitungsunterbrechung)" 4 "OOR+ (Signal zu gross)" 5 "OOR- (Signal zu klein)" 6 "RC+ (Signal unplausibel zu gross)" 7 "RC- (Signal unplausibel zu klein)" 8 "KS+/OC (Kurzschluss nach plus/Unterbrechung)" 9 "KS-/OC  (Kurzschluss nach minus/Unterbrechung)" 10 "KS-/KS+  (Kurzschluss nach minus/plus)" 11 "KS-/KS+/OC (Kurzschluss nach minus/plus/Unterbrechung)" 12 "frei" 13 "frei" 14 "frei" 15 "frei" ;
VAL_ 914 OBD_Fehler_Radsensor_VR 0 "kein Fehler / Init / nicht verbaut" 1 "KS- (Kurzschluss nach minus)" 2 "KS+ (Kurzschluss nach plus)" 3 "OC (Leitungsunterbrechung)" 4 "OOR+ (Signal zu gross)" 5 "OOR- (Signal zu klein)" 6 "RC+ (Signal unplausibel zu gross)" 7 "RC- (Signal unplausibel zu klein)" 8 "KS+/OC (Kurzschluss nach plus/Unterbrechung)" 9 "KS-/OC  (Kurzschluss nach minus/Unterbrechung)" 10 "KS-/KS+  (Kurzschluss nach minus/plus)" 11 "KS-/KS+/OC (Kurzschluss nach minus/plus/Unterbrechung)" 12 "frei" 13 "frei" 14 "frei" 15 "frei" ;
VAL_ 914 ESP_Qualifizierung_Antriebsart 0 "alte_Bedeutung_Bit_ESP_Allrad_Antrieb" 1 "neue_Bedeutung_Bit_ESP_Allrad_Antrieb" ;
VAL_ 914 ESP_Offroad_Modus 0 "kein_ESP_Offroadmodus" 1 "ESP_Offroadmodus" ;
VAL_ 914 ESP_MKB_ausloesbar 0 "Multikollisionsbremsung_nicht_freigeschaltet" 1 "Multikollisionsbremsung_freigeschaltet" ;
VAL_ 914 ESP_Stat_FallBack_eBKV 0 "Rueckfallebene_nicht_vorhanden" 1 "Rueckfallebene_vorhanden" ;
VAL_ 914 ESC_cAQP_Trigger 0 "AQP_Trigger_nicht_aktiv" 1 "AQP_Trigger_aktiv" ;
VAL_ 914 ESP_OBD_Status 0 "MIL_aus" 1 "MIL_ein" ;
VAL_ 914 ESP_Rollenmodus_Deaktivieren 0 "keine_Aenderung" 1 "Abbruch" ;
VAL_ 914 ESP_nachtr_Stopp_Anf 0 "nicht_angefordert" 1 "angefordert" ;
VAL_ 278 ESP_QBit_Wegimpuls_VL 0 "gueltiger_Wert" 1 "Ersatz_Init_oder_Fehlerwert" ;
VAL_ 278 ESP_QBit_Wegimpuls_VR 0 "gueltiger_Wert" 1 "Ersatz_Init_oder_Fehlerwert" ;
VAL_ 278 ESP_QBit_Wegimpuls_HL 0 "gueltiger_Wert" 1 "Ersatz_Init_oder_Fehlerwert" ;
VAL_ 278 ESP_QBit_Wegimpuls_HR 0 "gueltiger_Wert" 1 "Ersatz_Init_oder_Fehlerwert" ;
VAL_ 278 ESP_Wegimpuls_VL 1021 "Init" 1022 "Unterspannung" 1023 "Fehler" ;
VAL_ 278 ESP_Wegimpuls_VR 1021 "Init" 1022 "Unterspannung" 1023 "Fehler" ;
VAL_ 278 ESP_Wegimpuls_HL 1021 "Init" 1022 "Unterspannung" 1023 "Fehler" ;
VAL_ 278 ESP_Wegimpuls_HR 1021 "Init" 1022 "Unterspannung" 1023 "Fehler" ;
VAL_ 278 ESP_VL_Fahrtrichtung 0 "Vorwaerts" 1 "Rueckwaerts" 2 "Init" 3 "ungueltig_oder_nicht_verbaut" ;
VAL_ 278 ESP_VR_Fahrtrichtung 0 "Vorwaerts" 1 "Rueckwaerts" 2 "Init" 3 "ungueltig_oder_nicht_verbaut" ;
VAL_ 278 ESP_HL_Fahrtrichtung 0 "Vorwaerts" 1 "Rueckwaerts" 2 "Init" 3 "ungueltig_oder_nicht_verbaut" ;
VAL_ 278 ESP_HR_Fahrtrichtung 0 "Vorwaerts" 1 "Rueckwaerts" 2 "Init" 3 "ungueltig_oder_nicht_verbaut" ;
VAL_ 418 HMS_P_beibehalten_GE 0 "P_nicht_beibehalten" 1 "P_beibehalten" 2 "Init" 3 "Fehler" ;
VAL_ 418 HMS_Konsistenz_GE 0 "kein_Fehler_erkannt" 1 "Fehler_erkannt" ;
VAL_ 418 HMS_Konsistenz_IPA 0 "kein_Fehler_erkannt" 1 "Fehler_erkannt" ;
VAL_ 418 HMS_Konsistenz_STA 0 "kein_Fehler_erkannt" 1 "Fehler_erkannt" ;
VAL_ 418 HMS_Konsistenz_MO 0 "kein_Fehler_erkannt" 1 "Fehler_erkannt" ;
VAL_ 418 HMS_halten_nicht_verfuegbar 0 "verfuegbar" 1 "nicht_verfuegbar" ;
VAL_ 418 NL_PRIM_STP_01_Status 0 "Notlauf_inaktiv" 1 "Notlauf_bereit" 2 "Notlauf_aktiv" 3 "Notlauf_nicht_verfuegbar" 4 "Notlauf_aktivierbar" ;
VAL_ 418 VMM_Warnblinken 0 "Aus" 1 "An" ;
VAL_ 418 VZM_Status 0 "Initialisierung" 1 "Verfuegbar" 2 "Verfuegbar_mit_eingeschraenkter_Performance" 3 "Nicht_Verfuegbar" 4 "Fehler" ;
VAL_ 418 HMS_Notstopp_Status 0 "Off_Init" 1 "Inaktiv" 2 "Ready" 3 "Aktiv" 4 "Pending" 7 "nicht_Verfuegbar" ;
VAL_ 418 HMS_parken_nicht_verfuegbar 0 "verfuegbar" 1 "nicht_verfuegbar" ;
VAL_ 418 HMS_Anforderung_GE 0 "keine_Anforderung" 1 "P_einlegen" ;
VAL_ 418 HMS_Systemstatus 0 "keine_Funktion_aktiv" 1 "Halten_aktiv" 2 "Parken_angefordert" 3 "Parken_aktiv" 4 "Parken_beibehalten_aktiv" 5 "Anfahren_aktiv" 6 "Loeseanforderung_aktiv" 7 "Loeseanforderung_durch_Fahrer" 8 "Abrutschen_erkannt" 9 "Halten_Standby_aktiv" 10 "Anfahren_Standby_aktiv" 14 "Init" 15 "Fehler" ;
VAL_ 418 HMS_Stillstand 0 "kein_Stillstand" 1 "Stillstand_frueh" 2 "Stillstand" 6 "Init" 7 "Fehler" ;
VAL_ 418 HMS_aktives_System 0 "kein_System__Init_Fehler" 1 "Fahreranforderung_aktiv" 2 "HMS_intern_aktiv" 3 "ACC_aktiv" 4 "Autohold_aktiv" 5 "HHC_aktiv" 6 "HVLM_aktiv" 7 "Getriebe_aktiv" 8 "EBKV_aktiv" 9 "ParkAssist_aktiv" 10 "ARA_aktiv" 11 "HTO_aktiv" 12 "autonomous_Hold_aktiv" 13 "STA_aktiv" 14 "Motor_aktiv" 15 "EA_aktiv" 16 "VLK_aktiv" 17 "RHP_aktiv" 18 "ORU_aktiv" ;
VAL_ 418 HMS_Konsistenz_HVLM 0 "kein_Fehler_erkannt" 1 "Fehler_erkannt" ;
VAL_ 418 HMS_Konsistenz_ACC 0 "kein_Fehler_erkannt" 1 "Fehler_erkannt" ;
VAL_ 418 HMS_Fehlerstatus 0 "kein_Fehler" 1 "Halten_nicht_moeglich" 2 "Sonderbetriebsmodus_aktiv" 3 "Systemeinschraenkung" 4 "Systemstoerung" ;
VAL_ 418 ESP_Index_Haltemoment 0 "Bremsmoment" 1 "Antriebsmoment" ;
VAL_ 418 ESP_Haltemoment 1022 "Init" 1023 "Fehler" ;
VAL_ 253 BR_Eingriffsmoment 1022 "Init" 1023 "Fehler" ;
VAL_ 253 MSR_verfuegbar 0 "verfuegbar" 1 "nicht_verfuegbar" ;
VAL_ 253 ESP_Diagnose 0 "ESP_nicht_in_Diagnose" 1 "ESP_in_Diagnose" ;
VAL_ 253 ESC_v_Signal_Qualifier_High_Low 0 "Gueteschwelle_kleiner_1kmh" 1 "Gueteschwelle_kleiner_3kmh" 2 "Gueteschwelle_kleiner_5kmh" 3 "Gueteschwelle_kleiner_10kmh" 4 "Gueteschwelle_kleiner_20kmh" 5 "Gueteschwelle_groessergleich_20kmh" 6 "Init" 7 "Fehler" ;
VAL_ 253 ESP_Vorsteuerung 0 "keine_Vorsteuerung_aktiv" 1 "Vorsteuerung_aktiv" ;
VAL_ 253 OBD_Schlechtweg 0 "kein_Schlechtweg_erkannt" 1 "Schlechtweg_erkannt" ;
VAL_ 253 OBD_QBit_Schlechtweg 0 "gueltiger_Wert" 1 "Ersatz_Init_oder_Fehlerwert" ;
VAL_ 253 ESP_v_Signal 65533 "Unterspannung" 65534 "Init" 65535 "Fehler" ;
VAL_ 253 ASR_Tastung_passiv 0 "ASR_aktiviert" 1 "ASR_passiv_getastet_oder_Schwellen_geaendert" ;
VAL_ 253 ESP_Tastung_passiv 0 "ESP_aktiviert" 1 "ESP_passiv_getastet_oder_Schwellen_geaendert" ;
VAL_ 253 ESP_Systemstatus 0 "iO" 1 "Fehler" ;
VAL_ 253 ASR_Schalteingriff 0 "keine_Anforderung" 1 "ASR_Schaltkennfeld" 2 "Rueckschaltung" 3 "Schaltverbot" ;
VAL_ 253 ESP_QBit_v_Signal 0 "gueltiger_Wert" 1 "Ersatz_Init_oder_Fehlerwert" ;
VAL_ 253 ABS_Bremsung 0 "keine_ABS_Regelung" 1 "ABS_Regelung_aktiv" ;
VAL_ 253 ASR_Anf 0 "keine_Anforderung" 1 "ASR_Anforderung" ;
VAL_ 253 MSR_Anf 0 "keine Anfoderung" 1 "MSR-Anforderung" ;
VAL_ 253 EBV_Eingriff 0 "kein_EBV_Eingriff" 1 "EBV_Eingriff" ;
VAL_ 253 EDS_Eingriff 0 "kein_EDS_Eingriff" 1 "EDS_Eingriff" ;
VAL_ 253 ESP_Eingriff 0 "kein_ESP_Eingriff" 1 "ESP_Eingriff_aktiv" ;
VAL_ 253 ESP_ASP 0 "inaktiv" 1 "aktiv" ;
VAL_ 253 ESC_Neutralschaltung 0 "keine_Anforderung" 1 "Neutralschaltung_angefordert" ;
VAL_ 1470 ESP_Gierrate_Offset_2 2046 "Init" 2047 "Fehler" ;
VAL_ 1470 ESP_Lenkwinkel_Offset 510 "Init" 511 "Fehler" ;
VAL_ 1470 BR_QBit_Reifenumfang_sekundaer 0 "gueltiger_Wert" 1 "Ersatz_Init_oder_Fehlerwert" ;
VAL_ 1470 ESP_Status_Bremsentemp_Anz 0 "Init" 1 "kalt" 2 "warm" 3 "heiss" 4 "ueberhitzt" 5 "nass" 7 "Fehler" ;
VAL_ 1470 ESP_Querbeschleunigung_Offset 62 "Init" 63 "Fehler" ;
VAL_ 1470 ESP_Laengsbeschleunigung_Offset 254 "Init" 255 "Fehler" ;
VAL_ 508 ESP_Status_Bremsentemp_02 0 "nicht_erhoeht" 1 "Schwelle_1" 2 "Schwelle_2" ;
VAL_ 508 ESP_Aggregataktivitaet 0 "inaktiv" 1 "aktiv" ;
VAL_ 508 ESP_Stillstandsflag 0 "kein_Stillstand_erkannt" 1 "Stillstand_erkannt" ;
VAL_ 508 ESC_MBK_Meldungen 0 "kein_Text" 1 "MBK_Hinweis_aktiv" 2 "MBK_Eskalation1_aktiv" ;
VAL_ 508 ESP_EDS_Anzeige 0 "Keine_Anzeige_aktiv" 1 "EDS_nicht_aktiv" 2 "EDS_aktiv_an_VA" 3 "EDS_aktiv_an_HA" 4 "EDS_aktiv_an_VA_und_HA" 5 "EDS_Uebertemperatur" 6 "EDS_Fehler" ;
VAL_ 508 RLE_Anzeigen 0 "keine_Anzeige" 1 "Rad_lose_allgemein" 2 "Rad_VL_lose" 3 "Rad_VR_lose" 4 "Rad_HL_lose" 5 "Rad_HR_lose" 6 "RLE_Pruefphase" 7 "RLE_Systemstoerung" ;
VAL_ 508 ESP_Wiederstart_Anz_Std 0 "keine_Anzeige" 1 "Standard_Wiederstartgrund" ;
VAL_ 508 ESC_Anforderung_Airbrake 0 "keine_Anforderung" 1 "Anf_Bremsperformancestellung" ;
VAL_ 508 ESC_FBA_Meldungen 0 "kein_Text" 1 "FBA_Warnung_aktiv_MT" 2 "FBA_Warnung_aktiv_AT" ;
VAL_ 508 ESP_Rollover_Status_dyn 0 "Auspraegung1" 1 "Auspraegung2" 2 "Auspraegung3" 3 "Auspraegung4" ;
VAL_ 508 ESP_Rollover_Status_stat 0 "Auspraegung1" 1 "Auspraegung2" 2 "Auspraegung3" 3 "Auspraegung4" ;
VAL_ 508 ESP_AVH_LED 0 "LED_aus" 1 "LED_ein" 2 "LED_blinken" 3 "Funktion_gesperrt__LED_aus" 6 "Init" ;
VAL_ 508 ESP_HDC_LED 0 "LED_aus" 1 "LED_ein" 2 "LED_blinken" 3 "Funktion_gesperrt__LED_aus" 6 "Init" ;
VAL_ 508 ESP_Off_LED 0 "LED_aus" 1 "LED_ein" 2 "LED_blinken" 3 "Funktion_gesperrt__LED_aus" 6 "Init" ;
VAL_ 508 ESP_Notbremsanzeige 0 "keine_Notbremsung_erkannt" 1 "Notbremsung_erkannt" ;
VAL_ 508 ESC_Motorstartverzoegerung 0 "Startfreigabe" 1 "Anforderung_Startverzoegerung" ;
VAL_ 508 ESP_Offroad_Lampe 0 "Aus" 1 "Ein" ;
VAL_ 508 ESP_HDC_Textanzeigen 0 "kein_Text" 1 "HDC_ein" 2 "HDC_aus" 3 "HDC_nicht_verfuegbar_in_FahrPr" 4 "HDC_nicht_verfuegbar_Uebertemp" 5 "HDC_verfuegbar_keine_Uebertemp" 6 "HDC_nicht_verfuegbar_ACC_aktiv" 7 "HDC_nicht_verfuegbar_GRA_aktiv" 8 "HDC_nicht_verfuegbar_LIM_aktiv" 9 "HDC_nicht_verfuegbar_IPA_aktiv" 10 "HDC_nicht_verfuegbar_PLA_aktiv" 11 "HDC_nicht_verf_anderes_Syst_akt" 12 "HDC_nicht_verfuegbar_Fehler" 13 "GRA_Hebel_einschalten" 14 "Funk_nicht_verfuegbar_bei_HDC" 15 "Funk_verfuegbar_wenn_HDC_aktiv" 16 "Deaktivierung_ESP_Eingriff" 17 "HDC_nicht_verfuegbar_ABS_solo" 18 "HDC_nicht_verfuegbar_Gaspedal" ;
VAL_ 508 ESP_HOLD_verf 0 "nicht_verfuegbar" 1 "verfuegbar" ;
VAL_ 427 ESC_AHW_aktiv 0 "keine_Aktivitaet" 1 "Aktivitaet_durch_IPA" 2 "Aktivitaet_durch_ARA" 3 "Aktivitaet_durch_ACC" 4 "tbd" 5 "tbd" 6 "tbd" 7 "tbd" ;
VAL_ 427 ESC_AHW_nicht_verfuegbar 0 "verfuegbar" 1 "nicht_verfuegbar" ;
VAL_ 427 ESC_ANB_CM_aktiv 0 "keine_Aktivitaet" 1 "Aktivitaet_durch_AWV" ;
VAL_ 427 ESC_ANB_CM_nicht_verfuegbar 0 "verfuegbar" 1 "nicht_verfuegbar" ;
VAL_ 427 ESC_Warnruck_aktiv 0 "keine_Aktivitaet" 1 "Aktivitaet_durch_AWV" 2 "Aktivitaet_durch_vFGS" 3 "Aktivitaet_durch_RCTA" 4 "Aktivitaet_durch_FCWO" 5 "Aktivitaet_durch_FCWP" 6 "Aktivitaet_durch_EA" 7 "Aktivitaet_durch_PCF" 8 "Aktivitaet_durch_KAS" 9 "Aktivitaet_durch_AGW" ;
VAL_ 427 ESC_Warnruck_nicht_verfuegbar 0 "verfuegbar" 1 "nicht_verfuegbar" ;
VAL_ 427 ESC_Prefill_aktiv 0 "keine_Aktivitaet" 1 "Prefill_aktiv" ;
VAL_ 427 ESC_Prefill_nicht_verfuegbar 0 "verfuegbar" 1 "nicht_verfuegbar" ;
VAL_ 427 ESC_HBA_aktiv 0 "keine_Aktivitaet" 1 "HBA_aktiv" ;
VAL_ 427 ESC_HBA_nicht_verfuegbar 0 "verfuegbar" 1 "nicht_verfuegbar" ;
VAL_ 427 ESC_TSK_SRBM_Anf 0 "keine_Aktivitaet" 1 "Aktivitaet_durch_TSK" ;
VAL_ 427 ESC_TSK_SRBM_nicht_verfuegbar 0 "verfuegbar" 1 "nicht_verfuegbar" ;
VAL_ 427 ESC_Verz_Reg_aktiv 0 "keine_Aktivitaet" 1 "Aktivitaet_TB_durch_AWV" 2 "Aktivitaet_ZB_durch_AWV" 3 "Aktivitaet_durch_vFGS" 4 "Aktivitaet_durch_TSK" 5 "Aktivitaet_durch_RCTA" 6 "Aktivitaet_durch_PLA_IPA" 7 "Aktivitaet_durch_STA" 8 "Aktivitaet_durch_ARA" 9 "Aktivitaet_durch_MKB" 10 "Aktivitaet_durch_BFF" 11 "Aktivitaet_durch_FAS_VK" 12 "Aktivitaet_durch_PCF" 13 "Aktivitaet_durch_KAS" 14 "Aktivitaet_durch_BRS_intern" 15 "reserviert" ;
VAL_ 427 ESC_Verz_Reg_nicht_verfuegbar 0 "verfuegbar" 1 "nicht_verfuegbar" ;
VAL_ 427 ESC_Verz_Reg_TB_nicht_verfuegbar 0 "verfuegbar" 1 "nicht_verfuegbar" ;
VAL_ 427 ESC_Verz_Reg_ZB_nicht_verfuegbar 0 "verfuegbar" 1 "nicht_verfuegbar" ;
VAL_ 427 ESC_Bremslicht_unplausibel 0 "plausibel" 1 "unplausibel" ;
VAL_ 427 ESC_Konsistenz_ACC 0 "konsistent" 1 "nicht_konsistent" ;
VAL_ 427 ESC_Konsistenz_AWV 0 "konsistent" 1 "nicht_konsistent" ;
VAL_ 427 ESC_Konsistenz_ARA 0 "konsistent" 1 "nicht_konsistent" ;
VAL_ 427 ESC_Konsistenz_IPA 0 "konsistent" 1 "nicht_konsistent" ;
VAL_ 427 ESC_Konsistenz_FCW 0 "konsistent" 1 "nicht_konsistent" ;
VAL_ 427 ESC_Konsistenz_NV 0 "konsistent" 1 "nicht_konsistent" ;
VAL_ 427 ESC_Konsistenz_RCTA 0 "konsistent" 1 "nicht_konsistent" ;
VAL_ 427 ESC_Konsistenz_TSK 0 "konsistent" 1 "nicht_konsistent" ;
VAL_ 427 ESC_Konsistenz_vFGS 0 "konsistent" 1 "nicht_konsistent" ;
VAL_ 427 ESC_Konsistenz_STA 0 "konsistent" 1 "nicht_konsistent" ;
VAL_ 427 ESC_Fahrer_Bremsdruck_bestimmend 0 "Fahrer_nicht_Bremsdruck_bestimmend" 1 "Fahrer_Bremsdruck_bestimmend" ;
VAL_ 427 ESC_Konsistenz_EA 0 "konsistent" 1 "nicht_konsistent" ;
VAL_ 427 ESC_Konsistenz_BFF 0 "konsistent" 1 "nicht_konsistent" ;
VAL_ 427 ESC_Konsistenz_MKB 0 "konsistent" 1 "nicht_konsistent" ;
VAL_ 427 ESC_Verz_ASIL_Verfuegbarkeit 0 "Nicht_verfuegbar" 1 "Verfuegbar_ab_ASIL_QM" 2 "Verfuegbar_ab_ASIL_A" 3 "Verfuegbar_ab_ASIL_B" 4 "Verfuegbar_ab_ASIL_C" 5 "reserved" 6 "reserved" 7 "reserved" ;
VAL_ 427 ESC_Pumpenanlauf_aktiv 0 "inaktiv" 1 "aktiv" ;
VAL_ 427 ESC_Konsistenz_AGW 0 "konsistent" 1 "nicht_konsistent" ;
VAL_ 427 ESC_Konsistenz_KAS 0 "konsistent" 1 "nicht_konsistent" ;
VAL_ 427 ESC_Konsistenz_PCF 0 "konsistent" 1 "nicht_konsistent" ;
VAL_ 427 ESC_Konsistenz_FAS_VK 0 "konsistent" 1 "nicht_konsistent" ;
VAL_ 427 ESC_Verz_Begrenzung 0 "keine_Begrenzung" 1 "Begrenzung_aktiv" ;
VAL_ 427 ESC_Konsistenz_AWA 0 "konsistent" 1 "nicht_konsistent" ;
VAL_ 264 FA_Hoehenwerte_kalibriert 0 "kalibrierte_Hoehenwerte_in_mm" 1 "Rohwerte" ;
VAL_ 264 EFP_Anf_Bremsenkuehlung 0 "keine_Anforderung" 1 "SKE_oeffnen" 2 "SKE_oeffnen_Luefter_ansteuern" ;
VAL_ 264 FA_Hoehenwert_VL_00 254 "nicht initialisiert" 255 "Fehler" ;
VAL_ 264 FA_Hoehenwert_VR_00 254 "nicht initialisiert" 255 "Fehler" ;
VAL_ 264 FA_Hoehenwert_HL_00 254 "nicht initialisiert" 255 "Fehler" ;
VAL_ 264 FA_Hoehenwert_HR_00 254 "nicht initialisiert" 255 "Fehler" ;
VAL_ 264 FA_Fahrbahnunebenheit 254 "Init" 255 "Fehler" ;
VAL_ 264 EFP_Reibwert_dyn 62 "Init" 63 "Fehler" ;
VAL_ 429 NR_Reglerstatus 0 "nicht_definiert" 1 "Hochniveau_2" 2 "Hochniveau_1" 3 "Zwischenniveau" 4 "Normalniveau" 5 "Tiefniveau_1" 6 "Tiefniveau_2" 7 "Tiefniveau_3" 8 "Verladeniveau" 9 "Beladungsniveau" 10 "Heckabsenkung" ;
VAL_ 429 FA_Verstellung_in_Kuerze 0 "keine_Verstellung_erwartet" 1 "Verstellung_erwartet" ;
VAL_ 429 FA_Verstellung_aktiv 0 "keine_Verstellung" 1 "Verstellung_aktiv" ;
VAL_ 429 FA_Kompressor_laeuft_in_Kuerze 0 "kein_Kompressorlauf_erwartet" 1 "Kompressorlauf_steht_bevor" ;
VAL_ 429 FA_Kompressor_laeuft 0 "Kompressor_nicht_angesteuert" 1 "Kompressor_angesteuert" ;
VAL_ 429 NR_Anforderung_v_Begrenzung 0 "keine_Begrenzung_angefordert" 1 "Sicherheitsbegrenzung_1_aktiv" 2 "Sicherheitsbegrenzung_2_aktiv" 3 "Komfortbegrenzung_aktiv" ;
VAL_ 429 NR_LED_SGN 0 "LED_aus" 1 "LED_ein" ;
VAL_ 429 NR_LED_TN 0 "LED_aus" 1 "LED_ein" ;
VAL_ 429 NR_LED_BN 0 "LED_aus" 1 "LED_ein" ;
VAL_ 429 FA_Absenkung_Fahrzeug 0 "keine_Absenkung" 1 "Absenkung_Fahrzeug" ;
VAL_ 429 FA_Anhaengerstatus_intern 0 "Anhaenger_intern_nicht_erkannt" 1 "Anhaenger_intern_erkannt_manuell" 2 "Anhaenger_intern_erkannt_automatisch" 3 "Anhaenger_intern_erkannt_automatisch_manuelle_Deaktivierung_aktiv" 4 "Anhaenger_intern_erkannt_Failsafe" ;
VAL_ 429 FA_Anhebung_Fahrzeug 0 "keine_Anhebung" 1 "Anhebung_Fahrzeug" ;
VAL_ 429 FA_Druckspeicher_verfuegbar 0 "Druckspeicher_nicht_verfuegbar" 1 "Regelung_aus_Druckspeicher_moeglich" ;
VAL_ 429 FA_HAL_Abschaltung 0 "keine_Beeinflussung" 1 "Abschaltung_angefordert" ;
VAL_ 429 FA_ESP_Zuschaltung 0 "keine_ESP_Beeinflussung" 1 "ESP_Zwangszuschaltung_angefordert" ;
VAL_ 429 NR_LED_HN 0 "LED_aus" 1 "LED_ein" ;
VAL_ 429 FA_Zwischenniveau 0 "kein_Zwischenniveau" 1 "Zwischenniveau" ;
VAL_ 429 FA_Systemstatus 0 "nicht_funktionsfaehig" 1 "funktionsfaehig" ;
VAL_ 429 EFP_Soll_FahrPr_HAL 0 "nicht_gesteuert" 1 "Zwang_Programm_1" 2 "Zwang_Programm_2" 3 "Zwang_Programm_3" 4 "Zwang_Programm_4" 5 "Zwang_Programm_5" 6 "Zwang_Programm_6" 7 "Zwang_Programm_7" 8 "Zwang_Programm_8" 9 "Zwang_Programm_9" 10 "Zwang_Programm_10" 11 "Zwang_Programm_11" 12 "Zwang_Programm_12" 13 "Zwang_Programm_13" 14 "Zwang_Programm_14" 15 "Zwang_Programm_15" ;
VAL_ 429 NR_Kompressor_Strom_02 255 "Fehler" ;
VAL_ 429 NR_Kompressor_Temp_Zylinderkopf 254 "Init" 255 "Fehler" ;
VAL_ 429 FA_Signal_Drucksensor 254 "Init" 255 "Fehler" ;
VAL_ 852 FB_Kopf_erkannt 0 "nicht_erkannt" 1 "erkannt" ;
VAL_ 852 FB_Lidschluss_Dauer 255 "Init" ;
VAL_ 852 FB_Lidschliess_Dauer 255 "Init" ;
VAL_ 852 FB_Lidschlag_Frequenz 255 "Init" ;
VAL_ 852 FB_Lidschlag_Dauer 255 "Init" ;
VAL_ 852 FB_Lidoeffnungs_Dauer 255 "Init" ;
VAL_ 2527679660 FB_Kopfaktivitaet_A1 15 "Init" ;
VAL_ 2527679660 FB_Kopfaktivitaet_A2 15 "Init" ;
VAL_ 2527679660 FB_Blindheit 0 "nicht_erkannt" 1 "erkannt" ;
VAL_ 2527679660 FB_NichtVerfuegbar 0 "verfuegbar" 1 "nicht_verfuegbar" ;
VAL_ 2527679660 FB_Fahrerwechsel 0 "Fahrerwechsel_nicht_erkannt" 1 "Fahrerwechsel_erkannt" 3 "Init" ;
VAL_ 2527679660 FB_Fehler 0 "kein_Fehler" 1 "Fehler" ;
VAL_ 2527679660 FB_Muedigkeit_Index 255 "Init" ;
VAL_ 853 FB_Blickbereich 15 "Init" ;
VAL_ 853 FB_Kopfrotation_Roll 254 "Init" 255 "Fehler" ;
VAL_ 853 FB_Kopfrotation_Nick 254 "Init" 255 "Fehler" ;
VAL_ 854 FB_Kopfrotation_Gier 254 "Init" 255 "Fehler" ;
VAL_ 854 FB_Kopfposition_Z 254 "Init" 255 "Fehler" ;
VAL_ 854 FB_Kopfposition_Y 254 "Init" 255 "Fehler" ;
VAL_ 854 FB_Kopfposition_X 254 "Init" 255 "Fehler" ;
VAL_ 1605 FLA_aktiv 0 "inaktiv" 1 "aktiv" ;
VAL_ 1605 FLA_ISP_defekt 0 "iO" 1 "defekt" ;
VAL_ 1605 FLA_Sensor_blockiert 0 "Sensor in Ordnung" 1 "Sensor blockiert" ;
VAL_ 1605 FLA_Abblendursache 0 "nichts erkannt (Init-Wert)" 1 "enentgegenkommendes Fahrzeug (Scheinwerfer erkannt)" 2 "vorausfahrendes Fahrzeug (Heckleuchten erkannt)" 4 "Geschwindigkeitslimit unterschritten" 8 "Ort_oder_Infrastruktur_erkannt" 16 "Umgebungshelligkeit_generell_zu_hell" 32 "Nebel_oder_Sensor_blockiert" 64 "Übertemperatur Imager" 128 "Verzögerungsbedingung" 255 "Fehler" ;
VAL_ 1605 FLA_Fernlicht_PWM 127 "Fehler" ;
VAL_ 1605 ISP_EC_Lichtwert_vorne 62 "Init" 63 "Fehler" ;
VAL_ 1605 ISP_EC_Lichtwert_hinten 62 "Init" 63 "Fehler" ;
VAL_ 1605 ISP_Himmelsrichtung 30 "nicht verfuegbar bzw. Init" 31 "Fehler" ;
VAL_ 1605 ISP_Taste_betaetigt 0 "nicht_betaetigt" 1 "betaetigt" ;
VAL_ 1605 ISP_EC_aktiv 0 "inaktiv" 1 "aktiv" ;
VAL_ 1605 ISP_Kompass_aktiv 0 "inaktiv" 1 "aktiv" ;
VAL_ 1605 FLA_Aufblenden 0 "nicht_aufblenden" 1 "aufblenden" ;
VAL_ 1605 FLA_SAE_Mode 0 "Init" 1 "FLA_Icon_invertiert" ;
VAL_ 2589283684 FoD_Transmission_Info 0 "Initwert" 1 "start_transmission" 2 "finish_transmission" ;
VAL_ 2589283684 FoD_Anz_Funktionsabschaltung 0 "Init" 1 "Popup_aufschalten" ;
VAL_ 1523 P_Heiz_Frontscheibe 254 " Messwert nicht verfuegbar" 255 "Fehler" 255 "Fehler" ;
VAL_ 1523 I_Heiz_Frontscheibe 254 "Messwert nicht verfuegbar" 255 "Fehler" ;
VAL_ 1523 Diag_Frontscheibe 0 "Init" 1 "Unterer Grenzwert unterschritten" 2 "Oberer Grenzwert ueberschritten" 4 "zur Zeit nicht pruefbar" 8 "Unterbrechung" 16 "El. Fehler im Stromkreis" 32 "El. Fehler im Stromkreis" 128 "Defekt" ;
VAL_ 1523 R_grenz_min 254 "Messwert nicht verfuegbar" 255 "Fehler" ;
VAL_ 1523 R_grenz_max 254 "Messwert nicht verfuegbar" 255 "Fehler" ;
VAL_ 1523 R_ist 254 "Messwert nicht verfuegbar" 255 "Fehler" ;
VAL_ 1523 FSW_Lokalaktiv 0 "war_nicht_lokal_aktiv" 1 "war_lokal_aktiv" ;
VAL_ 1523 FSH_LED 0 "Aus" 1 "Ein" ;
VAL_ 173 GE_MMom_Soll_02 1022 "keine_Anforderung_Init" 1023 "Fehler" ;
VAL_ 173 GE_MMom_Vorhalt_02 1022 "Init" 1023 "Fehler" ;
VAL_ 173 GE_Uefkt 1023 "Fehler" ;
VAL_ 173 GE_Fahrstufe 0 "Zwischenstellung" 1 "Init" 5 "Position_P" 6 "Position_R" 7 "Position_N" 8 "Position_D" 9 "Position_S" 10 "Effizienz" 13 "Tipp_in_S" 14 "Tipp_in_D" 15 "Fehler" ;
VAL_ 173 GE_Schaltablauf 0 "keine_Schaltung" 1 "Momentenueberschneidung" 2 "Befuellphase" 3 "Drehzahlueberfuehrung" ;
VAL_ 173 GE_Uefkt_unplausibel 0 "Uefkt_plausibel" 1 "Uefkt_unplausibel" ;
VAL_ 173 GE_MMom_Status_02 0 "kein_Eingriff" 1 "abs_reduzierender_Eingriff_auf_Gesamt_Antrieb_nur_schneller_Pfad" 2 "abs_erhoehender_Eingriff_auf_Gesamt_Antrieb" 3 "relativer_Eingriff_auf_Gesamt_Antrieb" 4 "relativer_Eingriff_auf_E_Maschine" 5 "abs_red_Eingr_auf_Gesamt_Antrieb_nur_Luftpfad" 6 "abs_red_Eingr_auf_Gesamt_Antrieb_Luft-_und_schnellen_Pfad" 7 "abs_Eingriff_auf_Gesamtantrieb_erhoehend_und_reduzierend" ;
VAL_ 173 GE_Status_Kraftschluss 0 "offen_kein_Kraftschluss" 1 "offen_mit_Kraftschluss" 2 "schlupfend_geregelt" 3 "abgesichert_offen_kein_Kraftschl" 4 "geschlossen_mit_Mikroschlupf" 5 "geschlossen_mit_Ueberanpressung" 6 "sonstige_Fehler" 7 "fehlerhaft_geschlossen" ;
VAL_ 173 GE_MMom_Status 0 "keine Anforderung" 1 "reduzierender Getriebeeingriff" 2 "erhöhender Getriebeeingriff" 3 "Änderung mit Sprung" ;
VAL_ 173 GE_Freig_MMom_Vorhalt 0 "nicht_freigegeben" 1 "freigegeben" ;
VAL_ 173 GE_Verbot_Ausblendung 0 "kein_Verbot" 1 "Verbot" ;
VAL_ 173 GE_Zielgang 0 "Gang P/N (ausgekuppelt)" 1 "Gang 1" 2 "Gang 2" 3 "Gang 3" 4 "Gang 4" 5 "Gang 5" 6 "Gang 6" 7 "Gang 7" 8 "Gang R" 11 "Gang 8" 12 "Gang 9" 13 "Gang10" 14 "Istgang nicht definiert" 15 "Fehler" ;
VAL_ 177 GE_Fahrprogramm 0 "Init" 1 "nicht_belegt" 2 "Normal" 3 "Sport" 4 "Offroad" 5 "Efficiency" 6 "Sport_Plus" 7 "Sport_Response" 10 "Snow" 11 "Gravel" 12 "Mud_Ruts" 13 "Sand_Dune" ;
VAL_ 177 GE_TippZustand 0 "Init_Kein_Tipp" 1 "Tipp_permanent" 2 "Tipp_temporaer" ;
VAL_ 177 GE_Freilauf_Status 0 "Freilauf_inaktiv_aber_moeglich" 1 "Freilauf_aktiv" 2 "Freilauf_nicht_moegl_1Verhinderer" 3 "Freilauf_nicht_moegl_gr_1Verhinderer" 7 "Fehler" ;
VAL_ 177 GE_Grundeinstellung 0 "inaktiv" 1 "aktiv" ;
VAL_ 177 GE_Anschleppstart_Freigabe 0 "keine_Freigabe" 1 "Freigabe" ;
VAL_ 177 GE_Strombedarf_erh 0 "keine_Anforderung" 1 "erhoehte_Anforderung" ;
VAL_ 177 GE_Uefkt_Praed 16383 "Fehler" ;
VAL_ 177 GE_KomFehler_ESP 0 "kein_Fehler" 1 "Fehler" ;
VAL_ 177 GE_Rollrichtung_falsch 0 "richtige_Rollrichtung_o_Init" 1 "falsche_Rollrichtung" ;
VAL_ 177 GE_Getriebestatus_02 0 "inaktiv" 1 "Rennstartvorbereitung" 2 "Rennstart" 3 "Anfahrt" 4 "Anfahrt_Komfort" 5 "Anfahrt_Leerlaufregler" 6 "bereit_zur_Ueberanpressung" 7 "Low_Speed_Modus" 8 "eLaunch" ;
VAL_ 177 GE_Eingangsdrehz_Praed 16382 "Init" 16383 "Fehler" ;
VAL_ 310 HAL_Status 0 "Normalbetrieb" 1 "Lenkungsausfall" 2 "Derating_aktiv" 3 "Lenkung_manuell_deaktiviert" ;
VAL_ 310 HAL_VZ_Radwinkel 0 "positiv_Lenkeinschlag_links" 1 "negativ_Lenkeinschlag_rechts" ;
VAL_ 310 HAL_QBit_Radwinkel 0 "gueltiger_Wert" 1 "Ersatz_Init_oder_Fehlerwert" ;
VAL_ 310 HAL_Radwinkel 1020 "Unterspannung" 1021 "nicht_kalibriert" 1022 "Init" 1023 "Fehler" ;
VAL_ 310 HAL_Warnungen 0 "keine_Warnung" 1 "Ausfall_rote_Warnung" 2 "Systemstoerung_gelbe_Warnung" 3 "HAL_deaktiviert" ;
VAL_ 310 HAL_Winkelbegrenzung 0 "nicht_aktiv" 1 "Lenkwinkelbegrenzung_aktiv" ;
VAL_ 310 HAL_VZ_Fahrerwunschwinkel_Soll 0 "positiv" 1 "negativ" ;
VAL_ 310 HAL_Fahrerwunschwinkel_Soll 1022 "Init" 1023 "Fehler" ;
VAL_ 310 HAL_max_Gradient 126 "Init" 127 "Fehler" ;
VAL_ 310 HAL_EFP_FahrPr 0 "keine_Funktion" 1 "Programm_1" 2 "Programm_2" 3 "Programm_3" 4 "Programm_4" 5 "Programm_5" 6 "Programm_6" 7 "Programm_7" 8 "Programm_8" 9 "Programm_9" 10 "Programm_10" 11 "Programm_11" 12 "Programm_12" 13 "Programm_13" 14 "Programm_14" 15 "Programm_15" ;
VAL_ 310 HAL_Status_2 0 "Init" 1 "Fahrbereit" 2 "Symmetriefahrt" 3 "Gelbe_Warnung" 4 "Rote_Warnung" 5 "Hinterachlenkung_deaktiviert" ;
VAL_ 310 HAL_Charisma_Status 0 "Init" 1 "verfuegbar" 2 "nicht_verfuegbar" 3 "asynchron_durch_Fahrerwunsch" ;
VAL_ 310 HAL_Charisma_FahrPr 0 "keine_Funktion" 1 "Programm_1" 2 "Programm_2" 3 "Programm_3" 4 "Programm_4" 5 "Programm_5" 6 "Programm_6" 7 "Programm_7" 8 "Programm_8" 9 "Programm_9" 10 "Programm_10" 11 "Programm_11" 12 "Programm_12" 13 "Programm_13" 14 "Programm_14" 15 "Programm_15" ;
VAL_ 676 HAL_IL_Status 0 "HAL_IL_nicht_aktiv" 1 "HAL_IL_Init" 2 "HAL_IL_funktionsbereit" 3 "HAL_IL_Winkelregelung_aktiv" 4 "HAL_IL_Fehler_dauer_mit_Rueckfuehr" 5 "HAL_IL_Fehler_dauer_ohne_Rueckfuehr" 6 "HAL_IL_Fehler_temp_mit_Rueckfuehr" 7 "nicht_belegt" 8 "HAL_IL_nicht_verfuegbar" ;
VAL_ 676 HAL_ARA_Status 0 "HAL_ARA_Deaktiv" 1 "HAL_ARA_Init" 2 "HAL_ARA_Fehler_mit_Eintrag" 3 "reserviert" 4 "reserviert" 5 "reserviert" 6 "HAL_ARA_Lenkwinkel_aktiv" 7 "HAL_ARA_Abgewiesen" 8 "HAL_ARA_Funktionsbereit" 9 "reserviert" 10 "HAL_ARA_Abbruch" 11 "reserviert" 12 "reserviert" 13 "reserviert" 14 "reserviert" 15 "reserviert" ;
VAL_ 676 HAL_PLA_Status 0 "HAL_PLA_Deaktiv" 1 "HAL_PLA_Init" 2 "HAL_PLA_Fehler_mit_Eintrag" 3 "reserviert" 4 "reserviert" 5 "reserviert" 6 "HAL_PLA_Lenkwinkel_aktiv" 7 "HAL_PLA_Abgewiesen" 8 "HAL_PLA_Funktionsbereit" 9 "reserviert" 10 "HAL_PLA_Abbruch" 11 "reserviert" 12 "reserviert" 13 "reserviert" 14 "reserviert" 15 "reserviert" ;
VAL_ 676 HAL_Temperatur 0 "Not_in_use" 254 "Init" 255 "Fehler" ;
VAL_ 676 HAL_PWR_Abbruch 0 "Init/Invalid" 1 "PWR beendet durch HAL-SG wegen vFzg" 2 "PWR beendet durch HAL-SG wegen HM" 3 "Radwinkeldifferenz zu groß" 4 "Gradient der Zielanforderung zu groß" 5 "reserviert" 6 "reserviert" 7 "reserviert" 8 "Falscher PLA-Status" 9 "Falscher ARA-Status" 10 "reserviert" 11 "reserviert" 12 "reserviert" 13 "reserviert" 14 "reserviert" 15 "reserviert" ;
VAL_ 676 HAL_PWR_Fehler 0 "Init/Invalid" 1 "Verfügbarkeit zu gering" 2 "reserviert" 3 "Rotorwinkel nicht initialisiert" 4 "BCM1/Rückfahrlicht veraltet" 5 "reserviert" 6 "reserviert" 7 "Fehler ESP(vFzg)" 8 "Fehler ESP(Raddrehzahlen)" 9 "reserviert" 10 "reserviert" 11 "reserviert" 12 "reserviert" 13 "reserviert" 14 "HAL_ARA_Satus == 6" 15 "HAL_PLA_Satus == 6" ;
VAL_ 1410 HD_Endstellung_oben 1 "HD in Endstellung oben (offen)" ;
VAL_ 1410 HD_Endstellung_unten 0 "Init" 1 "HD in Endstellung unten (geschlossen)" ;
VAL_ 1410 HD_Bewegung_auf 0 "Init" 1 "HD in Bewegung auf" ;
VAL_ 1410 HD_Bewegung_zu 0 "Init" 1 "HD in Bewegung zu" ;
VAL_ 1410 HD_Innentaster_betaetigt 0 "HD_Innentaster_nicht_betaetigt" 1 "HD_Innentaster_betaetigt" ;
VAL_ 1410 HD_UeKB_erkannt 0 "Init" 1 "Einklemmschutz aktiv" ;
VAL_ 1410 HD_Taster_defekt 0 "Taster_funktionsfähig" 1 "Taster defekt" ;
VAL_ 1410 HD_Rueckmeld_prog 0 "keine Rueckmeldung" 1 "Rueckmeldung zur Programmierung Endstellung aktiv" ;
VAL_ 1410 HD_Verriegelungstaster_betaetigt 0 "Taster_nicht_betaetigt" 1 "Taster_betaetigt" ;
VAL_ 1410 HD_Verr_Taster_betaetigt_inv 0 "Taster_betaetigt" 1 "Taster_nicht_betaetigt" ;
VAL_ 1410 HD_ZZH_Schalter_S3 0 "nicht_betaetigt" 1 "betaetigt" ;
VAL_ 1416 FSH_LED 0 "Aus" 1 "Ein" ;
VAL_ 1416 HSH_LED 0 "Aus" 1 "Ein" ;
VAL_ 1416 SIH_Stufe_LED_li 0 "Aus" 2 "Stufe_2" 4 "Stufe_4" 6 "Stufe_6" ;
VAL_ 1416 SIH_Stufe_LED_re 0 "Aus" 2 "Stufe_2" 4 "Stufe_4" 6 "Stufe_6" ;
VAL_ 1416 SIL_Stufe_LED_li 0 "Aus" 1 "Stufe_1" 2 "Stufe_2" 3 "Stufe_3" 4 "Stufe_4" 5 "Stufe_5" 6 "Stufe_6" ;
VAL_ 1416 SIL_Stufe_LED_re 0 "Aus" 1 "Stufe_1" 2 "Stufe_2" 3 "Stufe_3" 4 "Stufe_4" 5 "Stufe_5" 6 "Stufe_6" ;
VAL_ 1416 KRH_Stufe_LED_li 0 "Aus" 1 "Stufe_1" 2 "Stufe_2" 3 "Stufe_3" ;
VAL_ 1416 KRH_Stufe_LED_re 0 "Aus" 1 "Stufe_1" 2 "Stufe_2" 3 "Stufe_3" ;
VAL_ 1416 BCM1_TCH_HLR_Anf 0 "keine_Anforderung" 1 "Anforderung" ;
VAL_ 1416 HLR_SIH_Freigabe_Fond 0 "keine_Freigabe" 1 "Freigabe" ;
VAL_ 1416 SIL_Stufe_LED_HL 0 "Aus" 1 "Stufe_1" 2 "Stufe_2" 3 "Stufe_3" 4 "Stufe_4" 5 "Stufe_5" 6 "Stufe_6" ;
VAL_ 1416 SIL_Stufe_LED_HR 0 "Aus" 1 "Stufe_1" 2 "Stufe_2" 3 "Stufe_3" 4 "Stufe_4" 5 "Stufe_5" 6 "Stufe_6" ;
VAL_ 1416 SIH_Stufe_LED_HL 0 "Aus" 1 "Stufe_1" 2 "Stufe_2" 3 "Stufe_3" 4 "Stufe_4" 5 "Stufe_5" 6 "Stufe_6" ;
VAL_ 1416 SIH_Stufe_LED_HR 0 "Aus" 1 "Stufe_1" 2 "Stufe_2" 3 "Stufe_3" 4 "Stufe_4" 5 "Stufe_5" 6 "Stufe_6" ;
VAL_ 1016 HLR_FlHz_Freigabe_Ruhesitz 0 "0_Prozent" 1 "33_Prozent" 2 "66_Prozent" 3 "100_Prozent" ;
VAL_ 1016 HLR_FlHz_Freigabe_VR 0 "0_Prozent" 1 "33_Prozent" 2 "66_Prozent" 3 "100_Prozent" ;
VAL_ 1016 HLR_FlHz_Freigabe_VL 0 "0_Prozent" 1 "33_Prozent" 2 "66_Prozent" 3 "100_Prozent" ;
VAL_ 1016 HLR_FlHz_Freigabe_HR 0 "0_Prozent" 1 "33_Prozent" 2 "66_Prozent" 3 "100_Prozent" ;
VAL_ 1016 HLR_FlHz_Freigabe_HL 0 "0_Prozent" 1 "33_Prozent" 2 "66_Prozent" 3 "100_Prozent" ;
VAL_ 1016 HLR_TCH_Freigabe 0 "keine_Freigabe" 1 "Freigabe" ;
VAL_ 1016 HLR_SIH_Freigabe_Fond 0 "keine_Freigabe" 1 "Freigabe" ;
VAL_ 1016 HLR_Sp_Heizung_Freigabe_BT 0 "keine_Freigabe" 1 "Freigabe" ;
VAL_ 1016 HLR_Sp_Heizung_Freigabe_FT 0 "keine_Freigabe" 1 "Freigabe" ;
VAL_ 1016 HLR_KRH_Freigabe_VL 0 "0_Prozent" 1 "33_Prozent" 2 "66_Prozent" 3 "100_Prozent" ;
VAL_ 1016 HLR_KRH_Freigabe_VR 0 "0_Prozent" 1 "33_Prozent" 2 "66_Prozent" 3 "100_Prozent" ;
VAL_ 1016 HLR_SIH_Freigabe_VL 0 "0_Prozent" 1 "33_Prozent" 2 "66_Prozent" 3 "100_Prozent" ;
VAL_ 1016 HLR_SIH_Freigabe_VR 0 "0_Prozent" 1 "33_Prozent" 2 "66_Prozent" 3 "100_Prozent" ;
VAL_ 1016 HLR_SIH_Freigabe_HL 0 "0_Prozent" 1 "33_Prozent" 2 "66_Prozent" 3 "100_Prozent" ;
VAL_ 1016 HLR_SIH_Freigabe_HR 0 "0_Prozent" 1 "33_Prozent" 2 "66_Prozent" 3 "100_Prozent" ;
VAL_ 1016 HLR_SIL_Freigabe_VL 0 "0_Prozent" 1 "33_Prozent" 2 "66_Prozent" 3 "100_Prozent" ;
VAL_ 1016 HLR_SIL_Freigabe_VR 0 "0_Prozent" 1 "33_Prozent" 2 "66_Prozent" 3 "100_Prozent" ;
VAL_ 1016 HLR_SIL_Freigabe_HL 0 "0_Prozent" 1 "33_Prozent" 2 "66_Prozent" 3 "100_Prozent" ;
VAL_ 1016 HLR_SIL_Freigabe_HR 0 "0_Prozent" 1 "33_Prozent" 2 "66_Prozent" 3 "100_Prozent" ;
VAL_ 1016 HLR_FSH_Freigabe 0 "AUS" 63 "Fehler" ;
VAL_ 1016 HLR_HSH_Freigabe 0 "keine_Freigabe" 1 "Freigabe" ;
VAL_ 1016 HLR_LRH_Freigabe 0 "keine_Freigabe" 1 "Freigabe" ;
VAL_ 1016 HLR_PTC_linear_Freigabe 63 "Fehler" ;
VAL_ 1016 HLR_PTC_Freigabe 0 "Aus" 1 "Stufe_1" 2 "Stufe_2" 3 "Stufe_3" ;
VAL_ 1283 HVK_Istmodus_Anf 0 "nicht_angefordert" 1 "angefordert" ;
VAL_ 1283 HVK_TN1_Sollmodus 0 "HV_Off" 1 "HV_On" 2 "reserviert" 3 "Initialisierung" ;
VAL_ 1283 HVK_MO_EmSollzustand 0 "HvOff" 1 "HvStbyReq" 2 "HvStbyWait" 3 "HvBattOnReq" 4 "HvBattOnWait" 10 "HvOnIdle" 18 "HvOnDrvReq" 19 "HvOnDrvWait" 20 "HvOnDrvRdy" 28 "HvStepUpReq" 29 "HvStepUpWait" 30 "HvStepUp" 38 "HvStepDownReq" 39 "HvStepDownWait" 40 "HvStepDown" 46 "HvAcChPreReq" 47 "HvAcChPreWait" 48 "HvAcChReq" 49 "HvAcChWait" 50 "HvAcCh" 56 "HvDcChPreReq" 57 "HvDcChPreWait" 58 "HvDcChReq" 59 "HvDcChWait" 60 "HvDcCh" 67 "HvChOffReq" 68 "HvChOffWait" 69 "HvOnIdleReq" 70 "HvOnIdleWait" 96 "HvCpntOffReq" 97 "HvCpntOffWait" 98 "HvBattOffReq" 99 "HvBattOffWait" 109 "HvDcDcFailOffReq" 110 "HvDcDcFail" 119 "HvElmOffReq" 120 "HvElmOff" 126 "HvFailCpntOffReq" 127 "HvFailCpntOffWait" 128 "HvFailBattOffReq" 129 "HvFailBattOffWait" 130 "HvFailBattOff" 138 "HvFailUCtlReq" 139 "HvFailUCtlWait" 140 "HvFailUCtl" 150 "HvEmgcyOff" 255 "Init" ;
VAL_ 1283 HVK_BMS_Sollmodus 0 "HV_Off" 1 "HV_On" 3 "AC_Laden_erw" 4 "AC_Laden" 6 "DC_Laden" 7 "Init" ;
VAL_ 1283 HVK_DCDC_Sollmodus 0 "Standby" 1 "HV_On_Vorladen" 2 "Tiefsetzen" 3 "Hochsetzen" 4 "Pruefpuls_12V" 6 "Pruefpuls_DC_Laden" 7 "Initialisierung" ;
VAL_ 1283 HVK_EKK_Sollmodus 0 "Keine_Freigabe" 1 "Freigabe" 2 "Freigabe_ausgesetzt" 7 "Init" ;
VAL_ 1283 HVK_HVPTC_Sollmodus 0 "Keine_Freigabe" 1 "Freigabe" 2 "Freigabe_ausgesetzt" 7 "Init" ;
VAL_ 1283 HVK_HVLM_Sollmodus 0 "keine_Freigabe" 1 "Freigabe_Lademanager" 2 "Vorladung_AC_Pfad" 7 "Init" ;
VAL_ 1283 HVK_HV_Netz_Warnungen 0 "Keine_Warnung" 1 "Warntext_HV_Netz_Anf" 2 "Fehlertext_HV_Netz_Anf" 3 "Warnung_Kein_Wiederstart_moeglich" ;
VAL_ 1283 HV_Bordnetz_aktiv 0 "inaktiv" 1 "aktiv" ;
VAL_ 1283 HV_Bordnetz_Fehler 0 "kein_Fehler" 1 "Fehler" ;
VAL_ 1283 HVK_Gesamtst_Spgfreiheit 0 "Funktion_Init__ohne_Funktion" 1 "HV_System_spannungsfrei" 2 "HV_System_nicht_spannungsfrei" 3 "Fehler" ;
VAL_ 1283 HVK_AktiveEntladung_Anf 0 "nicht_angefordert" 1 "angefordert" ;
VAL_ 1283 HVK_Iso_Fehlerstatus 0 "kein_Fehler" 1 "Fehler" ;
VAL_ 1283 HVK_Iso_Messung_Start 0 "keine_Messung" 1 "Messung_HV_Netz_1" 2 "Messung_HV_Netz_2" 4 "deaktiviert" ;
VAL_ 1283 HVK_AIAD_Sollmodus_2 0 "keine_Freigabe" 1 "Freigabe" ;
VAL_ 1283 HVK_DCDC_EKK_Sollmodus 0 "aus" 1 "ein" 2 "reserviert" 3 "Init" ;
